VERSION "ConnectivityCANFD"

NS_ :

BS_ :

BU_ :  ETC IHU TCAM

BO_ 176 TcamConnCANFDFr01 : 64 TCAM
 SG_ ApproachReq_UB : 455|1@0+ (1,0) [0|1] "" IHU
 SG_ ApproachReqData1 : 7|8@0+ (1.0,0.0) [0.0|255.0] "Unitless" IHU
 SG_ ApproachReqData10 : 79|8@0+ (1.0,0.0) [0.0|255.0] "Unitless" IHU
 SG_ ApproachReqData11 : 87|8@0+ (1.0,0.0) [0.0|255.0] "Unitless" IHU
 SG_ ApproachReqData12 : 95|8@0+ (1.0,0.0) [0.0|255.0] "Unitless" IHU
 SG_ ApproachReqData13 : 103|8@0+ (1.0,0.0) [0.0|255.0] "Unitless" IHU
 SG_ ApproachReqData14 : 111|8@0+ (1.0,0.0) [0.0|255.0] "Unitless" IHU
 SG_ ApproachReqData15 : 119|8@0+ (1.0,0.0) [0.0|255.0] "Unitless" IHU
 SG_ ApproachReqData16 : 127|8@0+ (1.0,0.0) [0.0|255.0] "Unitless" IHU
 SG_ ApproachReqData2 : 15|8@0+ (1.0,0.0) [0.0|255.0] "Unitless" IHU
 SG_ ApproachReqData3 : 23|8@0+ (1.0,0.0) [0.0|255.0] "Unitless" IHU
 SG_ ApproachReqData4 : 31|8@0+ (1.0,0.0) [0.0|255.0] "Unitless" IHU
 SG_ ApproachReqData5 : 39|8@0+ (1.0,0.0) [0.0|255.0] "Unitless" IHU
 SG_ ApproachReqData6 : 47|8@0+ (1.0,0.0) [0.0|255.0] "Unitless" IHU
 SG_ ApproachReqData7 : 55|8@0+ (1.0,0.0) [0.0|255.0] "Unitless" IHU
 SG_ ApproachReqData8 : 63|8@0+ (1.0,0.0) [0.0|255.0] "Unitless" IHU
 SG_ ApproachReqData9 : 71|8@0+ (1.0,0.0) [0.0|255.0] "Unitless" IHU
 SG_ BLEKeySearchResp_UB : 454|1@0+ (1,0) [0|1] "" IHU
 SG_ BLEKeySearchRespData1 : 135|8@0+ (1.0,0.0) [0.0|255.0] "Unitless" IHU
 SG_ BLEKeySearchRespData10 : 207|8@0+ (1.0,0.0) [0.0|255.0] "Unitless" IHU
 SG_ BLEKeySearchRespData11 : 215|8@0+ (1.0,0.0) [0.0|255.0] "Unitless" IHU
 SG_ BLEKeySearchRespData12 : 223|8@0+ (1.0,0.0) [0.0|255.0] "Unitless" IHU
 SG_ BLEKeySearchRespData13 : 231|8@0+ (1.0,0.0) [0.0|255.0] "Unitless" IHU
 SG_ BLEKeySearchRespData14 : 239|8@0+ (1.0,0.0) [0.0|255.0] "Unitless" IHU
 SG_ BLEKeySearchRespData15 : 247|8@0+ (1.0,0.0) [0.0|255.0] "Unitless" IHU
 SG_ BLEKeySearchRespData16 : 255|8@0+ (1.0,0.0) [0.0|255.0] "Unitless" IHU
 SG_ BLEKeySearchRespData2 : 143|8@0+ (1.0,0.0) [0.0|255.0] "Unitless" IHU
 SG_ BLEKeySearchRespData3 : 151|8@0+ (1.0,0.0) [0.0|255.0] "Unitless" IHU
 SG_ BLEKeySearchRespData4 : 159|8@0+ (1.0,0.0) [0.0|255.0] "Unitless" IHU
 SG_ BLEKeySearchRespData5 : 167|8@0+ (1.0,0.0) [0.0|255.0] "Unitless" IHU
 SG_ BLEKeySearchRespData6 : 175|8@0+ (1.0,0.0) [0.0|255.0] "Unitless" IHU
 SG_ BLEKeySearchRespData7 : 183|8@0+ (1.0,0.0) [0.0|255.0] "Unitless" IHU
 SG_ BLEKeySearchRespData8 : 191|8@0+ (1.0,0.0) [0.0|255.0] "Unitless" IHU
 SG_ BLEKeySearchRespData9 : 199|8@0+ (1.0,0.0) [0.0|255.0] "Unitless" IHU
 SG_ DigKeyDataToHMI_UB : 453|1@0+ (1,0) [0|1] "" IHU
 SG_ DigKeyDataToHMIAcknowledgment : 263|8@0+ (1.0,0.0) [0.0|255.0] "Unitless" IHU
 SG_ DigKeyDataToHMIDKDataByte1 : 271|8@0+ (1.0,0.0) [0.0|255.0] "Unitless" IHU
 SG_ DigKeyDataToHMIDKDataByte2 : 279|8@0+ (1.0,0.0) [0.0|255.0] "Unitless" IHU
 SG_ DigKeyDataToHMIDKDataByte3 : 287|8@0+ (1.0,0.0) [0.0|255.0] "Unitless" IHU
 SG_ DigKeyDataToHMIDKDataByte4 : 295|8@0+ (1.0,0.0) [0.0|255.0] "Unitless" IHU
 SG_ DigKeyDataToHMIDKDataByte5 : 303|8@0+ (1.0,0.0) [0.0|255.0] "Unitless" IHU
 SG_ DigKeyDataToHMIDKDataByte6 : 311|8@0+ (1.0,0.0) [0.0|255.0] "Unitless" IHU
 SG_ DigKeyDataToHMIHeader : 319|8@0+ (1.0,0.0) [0.0|255.0] "Unitless" IHU
 SG_ NFCAndBLEKeyEnaSts_UB : 452|1@0+ (1,0) [0|1] "" IHU
 SG_ NFCAndBLEKeyEnaStsData1 : 327|8@0+ (1.0,0.0) [0.0|255.0] "Unitless" IHU
 SG_ NFCAndBLEKeyEnaStsData10 : 399|8@0+ (1.0,0.0) [0.0|255.0] "Unitless" IHU
 SG_ NFCAndBLEKeyEnaStsData11 : 407|8@0+ (1.0,0.0) [0.0|255.0] "Unitless" IHU
 SG_ NFCAndBLEKeyEnaStsData12 : 415|8@0+ (1.0,0.0) [0.0|255.0] "Unitless" IHU
 SG_ NFCAndBLEKeyEnaStsData13 : 423|8@0+ (1.0,0.0) [0.0|255.0] "Unitless" IHU
 SG_ NFCAndBLEKeyEnaStsData14 : 431|8@0+ (1.0,0.0) [0.0|255.0] "Unitless" IHU
 SG_ NFCAndBLEKeyEnaStsData15 : 439|8@0+ (1.0,0.0) [0.0|255.0] "Unitless" IHU
 SG_ NFCAndBLEKeyEnaStsData16 : 447|8@0+ (1.0,0.0) [0.0|255.0] "Unitless" IHU
 SG_ NFCAndBLEKeyEnaStsData2 : 335|8@0+ (1.0,0.0) [0.0|255.0] "Unitless" IHU
 SG_ NFCAndBLEKeyEnaStsData3 : 343|8@0+ (1.0,0.0) [0.0|255.0] "Unitless" IHU
 SG_ NFCAndBLEKeyEnaStsData4 : 351|8@0+ (1.0,0.0) [0.0|255.0] "Unitless" IHU
 SG_ NFCAndBLEKeyEnaStsData5 : 359|8@0+ (1.0,0.0) [0.0|255.0] "Unitless" IHU
 SG_ NFCAndBLEKeyEnaStsData6 : 367|8@0+ (1.0,0.0) [0.0|255.0] "Unitless" IHU
 SG_ NFCAndBLEKeyEnaStsData7 : 375|8@0+ (1.0,0.0) [0.0|255.0] "Unitless" IHU
 SG_ NFCAndBLEKeyEnaStsData8 : 383|8@0+ (1.0,0.0) [0.0|255.0] "Unitless" IHU
 SG_ NFCAndBLEKeyEnaStsData9 : 391|8@0+ (1.0,0.0) [0.0|255.0] "Unitless" IHU

BO_ 336 TcamConnCANFDFr02 : 64 TCAM
 SG_ BattPreHeatgLvl : 21|2@0+ (1,0) [0|3] "" IHU
 SG_ BattPreHeatgLvl_UB : 22|1@0+ (1,0) [0|1] "" IHU
 SG_ BattPreHeatgTiDif : 7|16@0+ (1.0,0.0) [0.0|65535.0] "Mins" IHU
 SG_ BattPreHeatgTiDif_UB : 23|1@0+ (1,0) [0|1] "" IHU
 SG_ BookChrgnActvdReq : 19|1@0+ (1,0) [0|1] "" IHU
 SG_ BookChrgnActvdReq_UB : 18|1@0+ (1,0) [0|1] "" IHU
 SG_ BookStopTiAchieved : 17|1@0+ (1,0) [0|1] "" IHU
 SG_ BookStopTiAchieved_UB : 16|1@0+ (1,0) [0|1] "" IHU
 SG_ BookTrvlClimaActvReq : 31|2@0+ (1,0) [0|3] "" IHU
 SG_ BookTrvlClimaActvReq_UB : 27|1@0+ (1,0) [0|1] "" IHU
 SG_ CarFindrHornLiReqFromTelm : 29|2@0+ (1,0) [0|3] "" IHU
 SG_ CarFindrHornLiReqFromTelm_UB : 26|1@0+ (1,0) [0|1] "" IHU
 SG_ CbnOverHeatProtnEnaFromTelm : 25|1@0+ (1,0) [0|1] "" IHU
 SG_ CbnOverHeatProtnEnaFromTelm_UB : 24|1@0+ (1,0) [0|1] "" IHU
 SG_ ChrgLidTelmLockgReq : 33|1@0+ (1,0) [0|1] "" IHU
 SG_ ChrgLidTelmLockgReq_UB : 32|1@0+ (1,0) [0|1] "" IHU
 SG_ ChrgnCtrlToEndOrRetartFromApp : 39|2@0+ (1,0) [0|3] "" IHU
 SG_ ChrgnCtrlToEndOrRetartFromApp_UB : 35|1@0+ (1,0) [0|1] "" IHU
 SG_ ClimaRqrd1 : 37|2@0+ (1,0) [0|3] "" IHU
 SG_ ClimaRqrd1_UB : 34|1@0+ (1,0) [0|1] "" IHU
 SG_ ClimaTmrStsTelmRqrd : 47|1@0+ (1,0) [0|1] "" IHU
 SG_ ClimaTmrStsTelmRqrd_UB : 46|1@0+ (1,0) [0|1] "" IHU
 SG_ CnclBookTrvlReq : 45|1@0+ (1,0) [0|1] "" IHU
 SG_ CnclBookTrvlReq_UB : 44|1@0+ (1,0) [0|1] "" IHU
 SG_ DigKeyGidInfo1_UB : 40|1@0+ (1,0) [0|1] "" IHU
 SG_ DigKeyGidInfo1Byte0 : 55|8@0+ (1.0,0.0) [0.0|255.0] "Unitless" IHU
 SG_ DigKeyGidInfo1Byte1 : 63|8@0+ (1.0,0.0) [0.0|255.0] "Unitless" IHU
 SG_ DigKeyGidInfo1Byte2 : 71|8@0+ (1.0,0.0) [0.0|255.0] "Unitless" IHU
 SG_ DigKeyGidInfo1Byte3 : 79|8@0+ (1.0,0.0) [0.0|255.0] "Unitless" IHU
 SG_ DigKeyGidInfo1Byte4 : 87|8@0+ (1.0,0.0) [0.0|255.0] "Unitless" IHU
 SG_ DigKeyGidInfo1Byte5 : 95|8@0+ (1.0,0.0) [0.0|255.0] "Unitless" IHU
 SG_ DigKeyGidInfo1Byte6 : 103|8@0+ (1.0,0.0) [0.0|255.0] "Unitless" IHU
 SG_ DigKeyGidInfo1Byte7 : 111|8@0+ (1.0,0.0) [0.0|255.0] "Unitless" IHU
 SG_ DigKeyGidInfo2_UB : 183|1@0+ (1,0) [0|1] "" IHU
 SG_ DigKeyGidInfo2Byte0 : 119|8@0+ (1.0,0.0) [0.0|255.0] "Unitless" IHU
 SG_ DigKeyGidInfo2Byte1 : 127|8@0+ (1.0,0.0) [0.0|255.0] "Unitless" IHU
 SG_ DigKeyGidInfo2Byte2 : 135|8@0+ (1.0,0.0) [0.0|255.0] "Unitless" IHU
 SG_ DigKeyGidInfo2Byte3 : 143|8@0+ (1.0,0.0) [0.0|255.0] "Unitless" IHU
 SG_ DigKeyGidInfo2Byte4 : 151|8@0+ (1.0,0.0) [0.0|255.0] "Unitless" IHU
 SG_ DigKeyGidInfo2Byte5 : 159|8@0+ (1.0,0.0) [0.0|255.0] "Unitless" IHU
 SG_ DigKeyGidInfo2Byte6 : 167|8@0+ (1.0,0.0) [0.0|255.0] "Unitless" IHU
 SG_ DigKeyGidInfo2Byte7 : 175|8@0+ (1.0,0.0) [0.0|255.0] "Unitless" IHU
 SG_ DKDataFromTelm_UB : 182|1@0+ (1,0) [0|1] "" IHU
 SG_ DKDataFromTelmAcknowledgment : 191|8@0+ (1.0,0.0) [0.0|255.0] "Unitless" IHU
 SG_ DKDataFromTelmDKDataByte1 : 199|8@0+ (1.0,0.0) [0.0|255.0] "Unitless" IHU
 SG_ DKDataFromTelmDKDataByte2 : 207|8@0+ (1.0,0.0) [0.0|255.0] "Unitless" IHU
 SG_ DKDataFromTelmDKDataByte3 : 215|8@0+ (1.0,0.0) [0.0|255.0] "Unitless" IHU
 SG_ DKDataFromTelmDKDataByte4 : 223|8@0+ (1.0,0.0) [0.0|255.0] "Unitless" IHU
 SG_ DKDataFromTelmDKDataByte5 : 231|8@0+ (1.0,0.0) [0.0|255.0] "Unitless" IHU
 SG_ DKDataFromTelmDKDataByte6 : 239|8@0+ (1.0,0.0) [0.0|255.0] "Unitless" IHU
 SG_ DKDataFromTelmHeader : 247|8@0+ (1.0,0.0) [0.0|255.0] "Unitless" IHU
 SG_ EmgyAsscTrigSts : 43|2@0+ (1,0) [0|3] "" IHU
 SG_ EmgyAsscTrigSts_UB : 41|1@0+ (1,0) [0|1] "" IHU
 SG_ EngForbidReqFromTelm : 259|1@0+ (1,0) [0|1] "" IHU
 SG_ EngForbidReqFromTelm_UB : 258|1@0+ (1,0) [0|1] "" IHU
 SG_ EngPermitReqFromTelm : 257|1@0+ (1,0) [0|1] "" IHU
 SG_ EngPermitReqFromTelm_UB : 256|1@0+ (1,0) [0|1] "" IHU
 SG_ ErsCmdRec_UB : 263|1@0+ (1,0) [0|1] "" IHU
 SG_ ErsCmdRecErsCmd : 255|2@0+ (1,0) [0|3] "" IHU
 SG_ ErsCmdRecErsRunTime : 253|6@0+ (1.0,0.0) [0.0|59.0] "Mins" IHU
 SG_ MemPosnFromTelm : 179|2@0+ (1,0) [0|3] "" IHU
 SG_ MemPosnFromTelm_UB : 180|1@0+ (1,0) [0|1] "" IHU
 SG_ RemACChrgLidTelmReq : 177|2@0+ (1,0) [0|3] "" IHU
 SG_ RemACChrgLidTelmReq_UB : 181|1@0+ (1,0) [0|1] "" IHU
 SG_ RemBookChrgnTarVal : 271|10@0+ (0.1,0.0) [0.0|100.0] "%" IHU
 SG_ RemBookChrgnTarVal_UB : 277|1@0+ (1,0) [0|1] "" IHU
 SG_ RemChkTInVeh : 273|1@0+ (1,0) [0|1] "" IHU
 SG_ RemChkTInVeh_UB : 272|1@0+ (1,0) [0|1] "" IHU
 SG_ RemDCChrgLidTelmReq : 261|2@0+ (1,0) [0|3] "" IHU
 SG_ RemDCChrgLidTelmReq_UB : 262|1@0+ (1,0) [0|1] "" IHU
 SG_ RemsSetDchaTarVal : 287|10@0+ (0.1,0.0) [0.0|100.0] "%" IHU
 SG_ RemsSetDchaTarVal_UB : 293|1@0+ (1,0) [0|1] "" IHU
 SG_ RemVentReq : 275|2@0+ (1,0) [0|3] "" IHU
 SG_ RemVentReq_UB : 276|1@0+ (1,0) [0|1] "" IHU
 SG_ ReqFragLvlTelm : 291|2@0+ (1,0) [0|3] "" IHU
 SG_ ReqFragLvlTelm_UB : 292|1@0+ (1,0) [0|1] "" IHU
 SG_ SeatHeatDurgClimaEnadFromTelm : 303|3@0+ (1,0) [0|7] "" IHU
 SG_ SeatHeatDurgClimaEnadFromTelm_UB : 300|1@0+ (1,0) [0|1] "" IHU
 SG_ SteerWhlHeatgDurgClimaEnadFromTelm : 289|1@0+ (1,0) [0|1] "" IHU
 SG_ SteerWhlHeatgDurgClimaEnadFromTelm_UB : 288|1@0+ (1,0) [0|1] "" IHU
 SG_ SunRoofAndCurtCmdTelm : 311|8@0+ (1,0) [0|255] "" IHU
 SG_ SunRoofAndCurtCmdTelm_UB : 296|1@0+ (1,0) [0|1] "" IHU
 SG_ TankFlapTelmLockgReq : 319|3@0+ (1,0) [0|7] "" IHU
 SG_ TankFlapTelmLockgReq_UB : 316|1@0+ (1,0) [0|1] "" IHU
 SG_ TelmAirFragTasteReq : 315|3@0+ (1,0) [0|7] "" IHU
 SG_ TelmAirFragTasteReq_UB : 312|1@0+ (1,0) [0|1] "" IHU
 SG_ TelmBookChrgnReq : 298|2@0+ (1,0) [0|3] "" IHU
 SG_ TelmBookChrgnReq_UB : 299|1@0+ (1,0) [0|1] "" IHU
 SG_ TelmBookClimaReq_UB : 328|1@0+ (1,0) [0|1] "" IHU
 SG_ TelmBookClimaReqHmiCmptmtTSpSpcl : 321|2@0+ (1,0) [0|3] "" IHU
 SG_ TelmBookClimaReqOnOffNoReq : 335|2@0+ (1,0) [0|3] "" IHU
 SG_ TelmBookClimaReqTempRange : 333|5@0+ (0.5,15.5) [15.5|28.5] "degC" IHU
 SG_ TelmBookClimaTmr : 343|16@0+ (1.0,0.0) [0.0|65535.0] "s" IHU
 SG_ TelmBookClimaTmr_UB : 322|1@0+ (1,0) [0|1] "" IHU
 SG_ TelmBookSeatHeatClimalReq_UB : 372|1@0+ (1,0) [0|1] "" IHU
 SG_ TelmBookSeatHeatClimalReqDrvHeatClimaLvl : 371|2@0+ (1,0) [0|3] "" IHU
 SG_ TelmBookSeatHeatClimalReqPassHeatClimaLvl : 369|2@0+ (1,0) [0|3] "" IHU
 SG_ TelmBookSeatHeatClimalReqSecLeHeatClimaLvl : 383|2@0+ (1,0) [0|3] "" IHU
 SG_ TelmBookSeatHeatClimalReqSecRiHeatClimaLvl : 381|2@0+ (1,0) [0|3] "" IHU
 SG_ TelmBookSeatHeatClimalReqThrdLeHeatClimaLvl : 379|2@0+ (1,0) [0|3] "" IHU
 SG_ TelmBookSeatHeatClimalReqThrdRiHeatClimaLvl : 377|2@0+ (1,0) [0|3] "" IHU
 SG_ TelmBookSeatVentnClimalReq_UB : 395|1@0+ (1,0) [0|1] "" IHU
 SG_ TelmBookSeatVentnClimalReqDrvVentnClimaLvl : 391|2@0+ (1,0) [0|3] "" IHU
 SG_ TelmBookSeatVentnClimalReqPassVentnClimaLvl : 389|2@0+ (1,0) [0|3] "" IHU
 SG_ TelmBookSeatVentnClimalReqSecLeVentnClimaLvl : 387|2@0+ (1,0) [0|3] "" IHU
 SG_ TelmBookSeatVentnClimalReqSecRiVentnClimaLvl : 385|2@0+ (1,0) [0|3] "" IHU
 SG_ TelmBookSeatVentnClimalReqThrdLeVentnClimaLvl : 399|2@0+ (1,0) [0|3] "" IHU
 SG_ TelmBookSeatVentnClimalReqThrdRiVentnClimaL : 397|2@0+ (1,0) [0|3] "" IHU
 SG_ TelmBookSteerWhlHeatClimalReq : 327|1@0+ (1,0) [0|1] "" IHU
 SG_ TelmBookSteerWhlHeatClimalReq_UB : 326|1@0+ (1,0) [0|1] "" IHU
 SG_ TelmClimaReq : 375|2@0+ (1,0) [0|3] "" IHU
 SG_ TelmClimaReq_UB : 373|1@0+ (1,0) [0|1] "" IHU
 SG_ TelmClimaTmr : 359|16@0+ (1.0,0.0) [0.0|65535.0] "s" IHU
 SG_ TelmClimaTmr_UB : 323|1@0+ (1,0) [0|1] "" IHU
 SG_ TelmClimaTSet_UB : 407|1@0+ (1,0) [0|1] "" IHU
 SG_ TelmClimaTSetHmiCmptmtTSpSpcl : 406|2@0+ (1,0) [0|3] "" IHU
 SG_ TelmClimaTSetTempRange : 404|5@0+ (0.5,15.5) [15.5|28.5] "degC" IHU
 SG_ TelmDefrostReq : 393|2@0+ (1,0) [0|3] "" IHU
 SG_ TelmDefrostReq_UB : 394|1@0+ (1,0) [0|1] "" IHU
 SG_ TelmEngDelayTi : 415|6@0+ (1.0,0.0) [0.0|59.0] "Mins" IHU
 SG_ TelmEngDelayTi_UB : 409|1@0+ (1,0) [0|1] "" IHU
 SG_ TelmFctReq : 325|1@0+ (1,0) [0|1] "" IHU
 SG_ TelmFctReq_UB : 324|1@0+ (1,0) [0|1] "" IHU
 SG_ TelmLockgCenReq_UB : 422|1@0+ (1,0) [0|1] "" IHU
 SG_ TelmLockgCenReqReqTyp : 421|2@0+ (1,0) [0|3] "" IHU
 SG_ TelmLockgCenReqTiVld : 419|4@0+ (1.0,0.0) [0.0|15.0] "Unitless" IHU
 SG_ TelmPM25Req : 408|1@0+ (1,0) [0|1] "" IHU
 SG_ TelmPM25Req_UB : 423|1@0+ (1,0) [0|1] "" IHU
 SG_ TelmPreClimaPrio : 431|2@0+ (1,0) [0|3] "" IHU
 SG_ TelmPreClimaPrio_UB : 447|1@0+ (1,0) [0|1] "" IHU
 SG_ TelmSeatDrvHeatClimaLvl : 429|2@0+ (1,0) [0|3] "" IHU
 SG_ TelmSeatDrvHeatClimaLvl_UB : 446|1@0+ (1,0) [0|1] "" IHU
 SG_ TelmSeatDrvVentnClimaLvl : 427|2@0+ (1,0) [0|3] "" IHU
 SG_ TelmSeatDrvVentnClimaLvl_UB : 445|1@0+ (1,0) [0|1] "" IHU
 SG_ TelmSeatPassHeatClimaLvl : 425|2@0+ (1,0) [0|3] "" IHU
 SG_ TelmSeatPassHeatClimaLvl_UB : 444|1@0+ (1,0) [0|1] "" IHU
 SG_ TelmSeatPassVentnClimaLvl : 439|2@0+ (1,0) [0|3] "" IHU
 SG_ TelmSeatPassVentnClimaLvl_UB : 443|1@0+ (1,0) [0|1] "" IHU
 SG_ TelmSeatSecLeHeatClimaLvl : 437|2@0+ (1,0) [0|3] "" IHU
 SG_ TelmSeatSecLeHeatClimaLvl_UB : 442|1@0+ (1,0) [0|1] "" IHU
 SG_ TelmSeatSecLeVentnClimaLvl : 435|2@0+ (1,0) [0|3] "" IHU
 SG_ TelmSeatSecLeVentnClimaLvl_UB : 441|1@0+ (1,0) [0|1] "" IHU
 SG_ TelmSeatSecRiHeatClimaLvl : 433|2@0+ (1,0) [0|3] "" IHU
 SG_ TelmSeatSecRiHeatClimaLvl_UB : 440|1@0+ (1,0) [0|1] "" IHU
 SG_ TelmSeatSecRiVentnClimaLvl : 455|2@0+ (1,0) [0|3] "" IHU
 SG_ TelmSeatSecRiVentnClimaLvl_UB : 479|1@0+ (1,0) [0|1] "" IHU
 SG_ TelmSeatThrdLeHeatClimaLvl : 453|2@0+ (1,0) [0|3] "" IHU
 SG_ TelmSeatThrdLeHeatClimaLvl_UB : 478|1@0+ (1,0) [0|1] "" IHU
 SG_ TelmSeatThrdLeVentnClimaLvl : 451|2@0+ (1,0) [0|3] "" IHU
 SG_ TelmSeatThrdLeVentnClimaLvl_UB : 477|1@0+ (1,0) [0|1] "" IHU
 SG_ TelmSeatThrdRiHeatClimaLvl : 449|2@0+ (1,0) [0|3] "" IHU
 SG_ TelmSeatThrdRiHeatClimaLvl_UB : 476|1@0+ (1,0) [0|1] "" IHU
 SG_ TelmSeatThrdRiVentnClimaLvl : 463|2@0+ (1,0) [0|3] "" IHU
 SG_ TelmSeatThrdRiVentnClimaLvl_UB : 475|1@0+ (1,0) [0|1] "" IHU
 SG_ TelmStrtEngForChrgnReq : 461|2@0+ (1,0) [0|3] "" IHU
 SG_ TelmStrtEngForChrgnReq_UB : 474|1@0+ (1,0) [0|1] "" IHU
 SG_ TelmThermoTankReq1 : 503|2@0+ (1,0) [0|3] "" IHU
 SG_ TelmThermoTankReq1_UB : 488|1@0+ (1,0) [0|1] "" IHU
 SG_ TelmThermoTankT : 487|8@0+ (1.0,-50.0) [-50.0|205.0] "degC" IHU
 SG_ TelmThermoTankT_UB : 495|1@0+ (1,0) [0|1] "" IHU
 SG_ TelmThermoTankTmr1 : 494|5@0+ (1.0,0.0) [0.0|31.0] "hours" IHU
 SG_ TelmThermoTankTmr1_UB : 489|1@0+ (1,0) [0|1] "" IHU
 SG_ UnlockAndLogInAccountReq : 459|2@0+ (1,0) [0|3] "" IHU
 SG_ UnlockAndLogInAccountReq_UB : 473|1@0+ (1,0) [0|1] "" IHU
 SG_ WinOpenClsGlbReqFromTelm_UB : 472|1@0+ (1,0) [0|1] "" IHU
 SG_ WinOpenClsGlbReqFromTelmWindowOpenValue : 471|8@0+ (1.0,0.0) [0.0|100.0] "%" IHU
 SG_ WinOpenClsGlbReqFromTelmWinOpenClsGlbSts : 457|2@0+ (1,0) [0|3] "" IHU

BO_ 192 TcamConnCANFDFr03 : 64 TCAM
 SG_ DKDataFromBLE_UB : 261|1@0+ (1,0) [0|1] "" IHU
 SG_ DKDataFromBLEAcknowledgment : 271|8@0+ (1.0,0.0) [0.0|255.0] "Unitless" IHU
 SG_ DKDataFromBLEDKDataByte1 : 279|8@0+ (1.0,0.0) [0.0|255.0] "Unitless" IHU
 SG_ DKDataFromBLEDKDataByte2 : 287|8@0+ (1.0,0.0) [0.0|255.0] "Unitless" IHU
 SG_ DKDataFromBLEDKDataByte3 : 295|8@0+ (1.0,0.0) [0.0|255.0] "Unitless" IHU
 SG_ DKDataFromBLEDKDataByte4 : 303|8@0+ (1.0,0.0) [0.0|255.0] "Unitless" IHU
 SG_ DKDataFromBLEDKDataByte5 : 311|8@0+ (1.0,0.0) [0.0|255.0] "Unitless" IHU
 SG_ DKDataFromBLEDKDataByte6 : 319|8@0+ (1.0,0.0) [0.0|255.0] "Unitless" IHU
 SG_ DKDataFromBLEHeader : 327|8@0+ (1.0,0.0) [0.0|255.0] "Unitless" IHU
 SG_ DKDataFromTelm1_UB : 260|1@0+ (1,0) [0|1] "" IHU
 SG_ DKDataFromTelm1Acknowledgment : 335|8@0+ (1.0,0.0) [0.0|255.0] "Unitless" IHU
 SG_ DKDataFromTelm1DKDataByte1 : 343|8@0+ (1.0,0.0) [0.0|255.0] "Unitless" IHU
 SG_ DKDataFromTelm1DKDataByte2 : 351|8@0+ (1.0,0.0) [0.0|255.0] "Unitless" IHU
 SG_ DKDataFromTelm1DKDataByte3 : 359|8@0+ (1.0,0.0) [0.0|255.0] "Unitless" IHU
 SG_ DKDataFromTelm1DKDataByte4 : 367|8@0+ (1.0,0.0) [0.0|255.0] "Unitless" IHU
 SG_ DKDataFromTelm1DKDataByte5 : 375|8@0+ (1.0,0.0) [0.0|255.0] "Unitless" IHU
 SG_ DKDataFromTelm1DKDataByte6 : 383|8@0+ (1.0,0.0) [0.0|255.0] "Unitless" IHU
 SG_ DKDataFromTelm1Header : 391|8@0+ (1.0,0.0) [0.0|255.0] "Unitless" IHU
 SG_ NFCKeySearchResp_UB : 263|1@0+ (1,0) [0|1] "" IHU
 SG_ NFCKeySearchRespData1 : 7|8@0+ (1.0,0.0) [0.0|255.0] "Unitless" IHU
 SG_ NFCKeySearchRespData10 : 79|8@0+ (1.0,0.0) [0.0|255.0] "Unitless" IHU
 SG_ NFCKeySearchRespData11 : 87|8@0+ (1.0,0.0) [0.0|255.0] "Unitless" IHU
 SG_ NFCKeySearchRespData12 : 95|8@0+ (1.0,0.0) [0.0|255.0] "Unitless" IHU
 SG_ NFCKeySearchRespData13 : 103|8@0+ (1.0,0.0) [0.0|255.0] "Unitless" IHU
 SG_ NFCKeySearchRespData14 : 111|8@0+ (1.0,0.0) [0.0|255.0] "Unitless" IHU
 SG_ NFCKeySearchRespData15 : 119|8@0+ (1.0,0.0) [0.0|255.0] "Unitless" IHU
 SG_ NFCKeySearchRespData16 : 127|8@0+ (1.0,0.0) [0.0|255.0] "Unitless" IHU
 SG_ NFCKeySearchRespData2 : 15|8@0+ (1.0,0.0) [0.0|255.0] "Unitless" IHU
 SG_ NFCKeySearchRespData3 : 23|8@0+ (1.0,0.0) [0.0|255.0] "Unitless" IHU
 SG_ NFCKeySearchRespData4 : 31|8@0+ (1.0,0.0) [0.0|255.0] "Unitless" IHU
 SG_ NFCKeySearchRespData5 : 39|8@0+ (1.0,0.0) [0.0|255.0] "Unitless" IHU
 SG_ NFCKeySearchRespData6 : 47|8@0+ (1.0,0.0) [0.0|255.0] "Unitless" IHU
 SG_ NFCKeySearchRespData7 : 55|8@0+ (1.0,0.0) [0.0|255.0] "Unitless" IHU
 SG_ NFCKeySearchRespData8 : 63|8@0+ (1.0,0.0) [0.0|255.0] "Unitless" IHU
 SG_ NFCKeySearchRespData9 : 71|8@0+ (1.0,0.0) [0.0|255.0] "Unitless" IHU
 SG_ RKEAndNFCReqSts_UB : 262|1@0+ (1,0) [0|1] "" IHU
 SG_ RKEAndNFCReqStsData1 : 135|8@0+ (1.0,0.0) [0.0|255.0] "Unitless" IHU
 SG_ RKEAndNFCReqStsData10 : 207|8@0+ (1.0,0.0) [0.0|255.0] "Unitless" IHU
 SG_ RKEAndNFCReqStsData11 : 215|8@0+ (1.0,0.0) [0.0|255.0] "Unitless" IHU
 SG_ RKEAndNFCReqStsData12 : 223|8@0+ (1.0,0.0) [0.0|255.0] "Unitless" IHU
 SG_ RKEAndNFCReqStsData13 : 231|8@0+ (1.0,0.0) [0.0|255.0] "Unitless" IHU
 SG_ RKEAndNFCReqStsData14 : 239|8@0+ (1.0,0.0) [0.0|255.0] "Unitless" IHU
 SG_ RKEAndNFCReqStsData15 : 247|8@0+ (1.0,0.0) [0.0|255.0] "Unitless" IHU
 SG_ RKEAndNFCReqStsData16 : 255|8@0+ (1.0,0.0) [0.0|255.0] "Unitless" IHU
 SG_ RKEAndNFCReqStsData2 : 143|8@0+ (1.0,0.0) [0.0|255.0] "Unitless" IHU
 SG_ RKEAndNFCReqStsData3 : 151|8@0+ (1.0,0.0) [0.0|255.0] "Unitless" IHU
 SG_ RKEAndNFCReqStsData4 : 159|8@0+ (1.0,0.0) [0.0|255.0] "Unitless" IHU
 SG_ RKEAndNFCReqStsData5 : 167|8@0+ (1.0,0.0) [0.0|255.0] "Unitless" IHU
 SG_ RKEAndNFCReqStsData6 : 175|8@0+ (1.0,0.0) [0.0|255.0] "Unitless" IHU
 SG_ RKEAndNFCReqStsData7 : 183|8@0+ (1.0,0.0) [0.0|255.0] "Unitless" IHU
 SG_ RKEAndNFCReqStsData8 : 191|8@0+ (1.0,0.0) [0.0|255.0] "Unitless" IHU
 SG_ RKEAndNFCReqStsData9 : 199|8@0+ (1.0,0.0) [0.0|255.0] "Unitless" IHU

BO_ 320 TcamConnCANFDFr04 : 64 TCAM
 SG_ GuestrSts1_UB : 5|1@0+ (1,0) [0|1] "" IHU
 SG_ GuestrSts1Chks : 15|8@0+ (1.0,0.0) [0.0|255.0] "Unitless" IHU
 SG_ GuestrSts1Cntr : 3|4@0+ (1.0,0.0) [0.0|15.0] "Unitless" IHU
 SG_ GuestrSts1Validity : 4|1@0+ (1,0) [0|1] "" IHU
 SG_ KickTailgateSig : 90|1@0+ (1,0) [0|1] "" IHU
 SG_ KickTailgateSig_UB : 89|1@0+ (1,0) [0|1] "" IHU
 SG_ MobDevRPAAuthResp1_UB : 50|1@0+ (1,0) [0|1] "" IHU
 SG_ MobDevRPAAuthResp1Answer : 47|9@0+ (1.0,0.0) [0.0|511.0] "Unitless" IHU
 SG_ MobDevRPAAuthResp1Chks : 23|8@0+ (1.0,0.0) [0.0|255.0] "Unitless" IHU
 SG_ MobDevRPAAuthResp1Cntr : 54|4@0+ (1.0,0.0) [0.0|15.0] "Unitless" IHU
 SG_ MobDevRPAAuthResp1X : 31|8@0+ (1.0,0.0) [0.0|255.0] "Unitless" IHU
 SG_ MobDevRPAAuthResp1Y : 39|8@0+ (1.0,0.0) [0.0|255.0] "Unitless" IHU
 SG_ MobDevRPAReq1_UB : 63|1@0+ (1,0) [0|1] "" IHU
 SG_ MobDevRPAReq1Chks : 71|8@0+ (1.0,0.0) [0.0|255.0] "Unitless" IHU
 SG_ MobDevRPAReq1Cntr : 59|4@0+ (1.0,0.0) [0.0|15.0] "Unitless" IHU
 SG_ MobDevRPAReq1MobDevSts : 79|8@0+ (1.0,0.0) [0.0|255.0] "Unitless" IHU
 SG_ MobDevRPAReq1RPAOutModeSubT : 87|4@0+ (1,0) [0|15] "" IHU
 SG_ MobDevRPAReq1RPAReq : 83|4@0+ (1,0) [0|15] "" IHU
 SG_ MobDevRPAReq1RSPACtrl : 62|3@0+ (1,0) [0|7] "" IHU
 SG_ PasEntryEnaReq1 : 7|1@0+ (1,0) [0|1] "" IHU
 SG_ PasEntryEnaReq1_UB : 6|1@0+ (1,0) [0|1] "" IHU
 SG_ RemHvStrtActvReq : 95|2@0+ (1,0) [0|3] "" IHU
 SG_ RemHvStrtActvReq_UB : 93|1@0+ (1,0) [0|1] "" IHU

BO_ 928 TcamConnCANFDFr05 : 64 TCAM
 SG_ CarSharingMde : 3|1@0+ (1,0) [0|1] "" IHU
 SG_ CarSharingMde_UB : 2|1@0+ (1,0) [0|1] "" IHU
 SG_ MobDevBtnPanicReq : 9|2@0+ (1,0) [0|3] "" IHU
 SG_ MobDevBtnPanicReq_UB : 10|1@0+ (1,0) [0|1] "" IHU
 SG_ PhoneForgottenRmnBNCM2 : 1|1@0+ (1,0) [0|1] "" IHU
 SG_ PhoneForgottenRmnBNCM2_UB : 0|1@0+ (1,0) [0|1] "" IHU
 SG_ TelmBookChrgnTyp : 7|3@0+ (1,0) [0|7] "" IHU
 SG_ TelmBookChrgnTyp_UB : 4|1@0+ (1,0) [0|1] "" IHU
 SG_ WPCChrgnStsFrntLeWPC4 : 23|2@0+ (1,0) [0|3] "" IHU
 SG_ WPCChrgnStsFrntLeWPC4_UB : 31|1@0+ (1,0) [0|1] "" IHU
 SG_ WPCChrgnStsFrntRiWPC4 : 21|2@0+ (1,0) [0|3] "" IHU
 SG_ WPCChrgnStsFrntRiWPC4_UB : 30|1@0+ (1,0) [0|1] "" IHU
 SG_ WPCCtrlResFrntLeWPC4 : 19|2@0+ (1,0) [0|3] "" IHU
 SG_ WPCCtrlResFrntLeWPC4_UB : 29|1@0+ (1,0) [0|1] "" IHU
 SG_ WPCCtrlResFrntRiWPC4 : 17|2@0+ (1,0) [0|3] "" IHU
 SG_ WPCCtrlResFrntRiWPC4_UB : 28|1@0+ (1,0) [0|1] "" IHU
 SG_ WPCFailureStsFrntLeWPC4 : 39|4@0+ (1,0) [0|15] "" IHU
 SG_ WPCFailureStsFrntLeWPC4_UB : 27|1@0+ (1,0) [0|1] "" IHU
 SG_ WPCFailureStsFrntRiWPC4 : 35|4@0+ (1,0) [0|15] "" IHU
 SG_ WPCFailureStsFrntRiWPC4_UB : 26|1@0+ (1,0) [0|1] "" IHU
 SG_ WPCModuleStsBNCM2 : 15|4@0+ (1,0) [0|15] "" IHU
 SG_ WPCModuleStsBNCM2_UB : 11|1@0+ (1,0) [0|1] "" IHU
 SG_ WPCModuleStsFrntLeWPC4 : 47|4@0+ (1,0) [0|15] "" IHU
 SG_ WPCModuleStsFrntLeWPC4_UB : 25|1@0+ (1,0) [0|1] "" IHU
 SG_ WPCModuleStsFrntRiWPC4 : 43|4@0+ (1,0) [0|15] "" IHU
 SG_ WPCModuleStsFrntRiWPC4_UB : 24|1@0+ (1,0) [0|1] "" IHU

BO_ 848 TcamConnCANFDFr06 : 64 TCAM
 SG_ BLEKeyBattLoSts : 5|1@0+ (1,0) [0|1] "" IHU
 SG_ BLEKeyBattLoSts_UB : 4|1@0+ (1,0) [0|1] "" IHU
 SG_ PhoneForgottenRmnFrntLeWPC4 : 7|1@0+ (1,0) [0|1] "" IHU
 SG_ PhoneForgottenRmnFrntLeWPC4_UB : 6|1@0+ (1,0) [0|1] "" IHU
 SG_ PhoneForgottenRmnFrntRiWPC4 : 3|1@0+ (1,0) [0|1] "" IHU
 SG_ PhoneForgottenRmnFrntRiWPC4_UB : 2|1@0+ (1,0) [0|1] "" IHU
 SG_ RemVSTDCtrlReq : 11|2@0+ (1,0) [0|3] "" IHU
 SG_ RemVSTDCtrlReq_UB : 9|1@0+ (1,0) [0|1] "" IHU

BO_ 736 TcamConnCANFDFr07 : 64 TCAM
 SG_ BleConSts : 37|1@0+ (1,0) [0|1] "" IHU
 SG_ BleConSts_UB : 36|1@0+ (1,0) [0|1] "" IHU
 SG_ CalltypeAndSts_UB : 1|1@0+ (1,0) [0|1] "" IHU
 SG_ CalltypeAndStsCallType : 7|3@0+ (1,0) [0|7] "" IHU
 SG_ CalltypeAndStsEcallStatus : 4|3@0+ (1,0) [0|7] "" IHU
 SG_ CarLocatorActvSts : 15|2@0+ (1,0) [0|3] "" IHU
 SG_ CarLocatorActvSts_UB : 0|1@0+ (1,0) [0|1] "" IHU
 SG_ NetTCAMActvt : 31|8@0+ (1.0,0.0) [0.0|255.0] "Unitless" IHU
 SG_ NetTCAMActvt_UB : 16|1@0+ (1,0) [0|1] "" IHU
 SG_ TelmPrkgCameraReq : 10|2@0+ (1,0) [0|3] "" IHU
 SG_ TelmPrkgCameraReq_UB : 8|1@0+ (1,0) [0|1] "" IHU
 SG_ UsgModChgReqFromUWB : 39|1@0+ (1,0) [0|1] "" IHU
 SG_ UsgModChgReqFromUWB_UB : 38|1@0+ (1,0) [0|1] "" IHU

BO_ 416 TcamConnCANFDFr08 : 64 TCAM
 SG_ PrkgCmftModTiCtrlReq : 7|2@0+ (1,0) [0|3] "" IHU
 SG_ PrkgCmftModTiCtrlReq_UB : 5|1@0+ (1,0) [0|1] "" IHU
 SG_ RemRemoveStrangerPassWordReq : 71|1@0+ (1,0) [0|1] "" IHU
 SG_ RemRemoveStrangerPassWordReq_UB : 70|1@0+ (1,0) [0|1] "" IHU
 SG_ RemStrtExtnTiReq : 15|6@0+ (1.0,0.0) [0.0|59.0] "Mins" IHU
 SG_ RemStrtExtnTiReq_UB : 9|1@0+ (1,0) [0|1] "" IHU
 SG_ RemStrtHvCtrlReq_UB : 8|1@0+ (1,0) [0|1] "" IHU
 SG_ RemStrtHvCtrlReqErsCmd : 23|2@0+ (1,0) [0|3] "" IHU
 SG_ RemStrtHvCtrlReqErsRunTime : 21|6@0+ (1.0,0.0) [0.0|59.0] "Mins" IHU
 SG_ TcamResetResp : 3|2@0+ (1,0) [0|3] "" IHU
 SG_ TcamResetResp_UB : 4|1@0+ (1,0) [0|1] "" IHU
 SG_ TelmExtrLiFileDeleteReq_UB : 24|1@0+ (1,0) [0|1] "" IHU
 SG_ TelmExtrLiFileDeleteReqID : 31|5@0+ (1.0,0.0) [0.0|31.0] "Unitless" IHU
 SG_ TelmExtrLiFileDeleteReqNoReqOnOff : 26|2@0+ (1,0) [0|3] "" IHU
 SG_ TelmExtrLiFileDownloadReq_UB : 32|1@0+ (1,0) [0|1] "" IHU
 SG_ TelmExtrLiFileDownloadReqID : 39|5@0+ (1.0,0.0) [0.0|31.0] "Unitless" IHU
 SG_ TelmExtrLiFileDownloadReqNoReqOnOff : 34|2@0+ (1,0) [0|3] "" IHU
 SG_ TelmExtrLiShowReq_UB : 40|1@0+ (1,0) [0|1] "" IHU
 SG_ TelmExtrLiShowReqID : 47|5@0+ (1.0,0.0) [0.0|31.0] "Unitless" IHU
 SG_ TelmExtrLiShowReqNoReqOnOff : 42|2@0+ (1,0) [0|3] "" IHU
 SG_ TelmStrangePassWordSet_UB : 67|1@0+ (1,0) [0|1] "" IHU
 SG_ TelmStrangePassWordSetNo1 : 55|4@0+ (1.0,0.0) [0.0|9.0] "Unitless" IHU
 SG_ TelmStrangePassWordSetNo2 : 51|4@0+ (1.0,0.0) [0.0|9.0] "Unitless" IHU
 SG_ TelmStrangePassWordSetNo3 : 63|4@0+ (1.0,0.0) [0.0|9.0] "Unitless" IHU
 SG_ TelmStrangePassWordSetNo4 : 59|4@0+ (1.0,0.0) [0.0|9.0] "Unitless" IHU
 SG_ TelmStrangerModStopCtrlReq : 69|1@0+ (1,0) [0|1] "" IHU
 SG_ TelmStrangerModStopCtrlReq_UB : 68|1@0+ (1,0) [0|1] "" IHU

BO_ 544 TcamConnCANFDFr09 : 64 TCAM
 SG_ BiasedPosnFromSatlt1_UB : 71|1@0+ (1,0) [0|1] "" IHU
 SG_ BiasedPosnFromSatlt1Cntr : 58|3@0+ (1.0,0.0) [0.0|7.0] "Unitless" IHU
 SG_ BiasedPosnFromSatlt1PosnLat : 7|30@0- (0.000000277778,0.0) [-90.000072|90.000072] "Deg" IHU
 SG_ BiasedPosnFromSatlt1PosnLgt : 25|31@0- (0.000000277778,0.0) [-180.000144|180.000144] "Deg" IHU
 SG_ GNSSSolution1_UB : 135|1@0+ (1,0) [0|1] "" IHU
 SG_ GNSSSolution1Cntr : 79|3@0+ (1.0,0.0) [0.0|7.0] "Unitless" IHU
 SG_ GNSSSolution1NoOfSatItForSysNo1 : 76|5@0+ (1.0,0.0) [0.0|31.0] "Unitless" IHU
 SG_ GNSSSolution1NoOfSatItForSysNo2 : 84|5@0+ (1.0,0.0) [0.0|31.0] "Unitless" IHU
 SG_ GNSSSolution1NoOfSatItForSysNo3 : 92|5@0+ (1.0,0.0) [0.0|31.0] "Unitless" IHU
 SG_ GNSSSolution1NoOfSatItForSysNo4 : 100|5@0+ (1.0,0.0) [0.0|31.0] "Unitless" IHU
 SG_ GNSSSolution1NoOfSatItForSysNo5 : 108|5@0+ (1.0,0.0) [0.0|31.0] "Unitless" IHU
 SG_ GNSSSolution1NoOfSatItForSysNo6 : 116|5@0+ (1.0,0.0) [0.0|31.0] "Unitless" IHU
 SG_ GNSSSolution1NoOfSatItForSysNo7 : 124|5@0+ (1.0,0.0) [0.0|31.0] "Unitless" IHU
 SG_ GNSSSolution1SatItSysNo1InUse : 85|1@0+ (1,0) [0|1] "" IHU
 SG_ GNSSSolution1SatItSysNo2InUse : 86|1@0+ (1,0) [0|1] "" IHU
 SG_ GNSSSolution1SatItSysNo3InUse : 87|1@0+ (1,0) [0|1] "" IHU
 SG_ GNSSSolution1SatItSysNo4InUse : 93|1@0+ (1,0) [0|1] "" IHU
 SG_ GNSSSolution1SatItSysNo5InUse : 94|1@0+ (1,0) [0|1] "" IHU
 SG_ GNSSSolution1SatItSysNo6InUse : 95|1@0+ (1,0) [0|1] "" IHU
 SG_ GNSSSolution1SatItSysNo7InUse : 101|1@0+ (1,0) [0|1] "" IHU
 SG_ GNSSSolution1SatltPosnStsPrm1 : 103|2@0+ (1,0) [0|3] "" IHU
 SG_ GNSSSolution1SatltPosnStsPrm2 : 109|1@0+ (1,0) [0|1] "" IHU
 SG_ GNSSSolution2_UB : 131|1@0+ (1,0) [0|1] "" IHU
 SG_ GNSSSolution2Cntr : 130|3@0+ (1.0,0.0) [0.0|7.0] "Unitless" IHU
 SG_ GNSSSolution2PreHozlDil : 143|8@0+ (0.1,0.0) [0.0|25.5] "Unitless" IHU
 SG_ GNSSSolution2PrePosnDil : 151|8@0+ (0.1,0.0) [0.0|25.5] "Unitless" IHU
 SG_ GNSSSolution2PreVertDil : 159|8@0+ (0.1,0.0) [0.0|25.5] "Unitless" IHU
 SG_ ImobVehRemReqAndResp_UB : 163|1@0+ (1,0) [0|1] "" IHU
 SG_ ImobVehRemReqAndRespImobVehDataRemReq0 : 175|8@0+ (1.0,0.0) [0.0|255.0] "Unitless" IHU
 SG_ ImobVehRemReqAndRespImobVehDataRemReq1 : 183|8@0+ (1.0,0.0) [0.0|255.0] "Unitless" IHU
 SG_ ImobVehRemReqAndRespImobVehDataRemReq2 : 191|8@0+ (1.0,0.0) [0.0|255.0] "Unitless" IHU
 SG_ ImobVehRemReqAndRespImobVehDataRemReq3 : 199|8@0+ (1.0,0.0) [0.0|255.0] "Unitless" IHU
 SG_ ImobVehRemReqAndRespImobVehDataRemReq4 : 207|8@0+ (1.0,0.0) [0.0|255.0] "Unitless" IHU
 SG_ ImobVehRemReqAndRespImobVehRemReqCmd : 162|3@0+ (1,0) [0|7] "" IHU
 SG_ ImobVehRemReqAndRespImobVehRemTmrOrSpdLim : 215|8@0+ (1.0,0.0) [0.0|255.0] "Unitless" IHU
 SG_ LowrReAxle : 70|1@0+ (1,0) [0|1] "" IHU
 SG_ LowrReAxle_UB : 69|1@0+ (1,0) [0|1] "" IHU
 SG_ MobDevDistSts1 : 361|10@0+ (1.0,0.0) [0.0|1023.0] "cm" IHU
 SG_ MobDevDistSts1_UB : 362|1@0+ (1,0) [0|1] "" IHU
 SG_ MobDevRCVReq1_UB : 383|1@0+ (1,0) [0|1] "" IHU
 SG_ MobDevRCVReq1Chks : 399|8@0+ (1.0,0.0) [0.0|255.0] "Unitless" IHU
 SG_ MobDevRCVReq1Cntr : 407|4@0+ (1.0,0.0) [0.0|15.0] "Unitless" IHU
 SG_ MobDevRCVReq1MobDevSts : 391|8@0+ (1.0,0.0) [0.0|255.0] "Unitless" IHU
 SG_ MobDevRCVReq1RCVCtrl : 379|4@0+ (1,0) [0|15] "" IHU
 SG_ MobDevRCVReq1Steertrim : 382|3@0+ (1,0) [0|7] "" IHU
 SG_ PosnFromSatlt1_UB : 223|1@0+ (1,0) [0|1] "" IHU
 SG_ PosnFromSatlt1Cntr : 287|3@0+ (1.0,0.0) [0.0|7.0] "Unitless" IHU
 SG_ PosnFromSatlt1PosnLat : 255|30@0- (0.000000277778,0.0) [-90.000072|90.000072] "Deg" IHU
 SG_ PosnFromSatlt1PosnLgt : 222|31@0- (0.000000277778,0.0) [-180.000144|180.000144] "Deg" IHU
 SG_ PosnFromSatlt2_UB : 284|1@0+ (1,0) [0|1] "" IHU
 SG_ PosnFromSatlt2Cntr : 283|3@0+ (1.0,0.0) [0.0|7.0] "Unitless" IHU
 SG_ PosnFromSatlt2PosnSpdosn : 280|17@0+ (0.001,0.0) [0.0|100.0] "m/s" IHU
 SG_ PosnFromSatlt3_UB : 364|1@0+ (1,0) [0|1] "" IHU
 SG_ PosnFromSatlt3Cntr : 367|3@0+ (1.0,0.0) [0.0|7.0] "Unitless" IHU
 SG_ PosnFromSatlt3PosnAlti : 311|16@0+ (0.1,-100.0) [-100.0|6000.0] "m" IHU
 SG_ PosnFromSatlt3PosnDir : 327|16@0+ (0.01,0.0) [0.0|359.99] "Deg" IHU
 SG_ PosnFromSatlt3TiForMins : 349|6@0+ (1.0,0.0) [0.0|59.0] "Mins" IHU
 SG_ PosnFromSatlt3TiForMsec : 343|10@0+ (1.0,0.0) [0.0|1023.0] "Unitless" IHU
 SG_ PosnFromSatlt3TiForSec : 359|6@0+ (1.0,0.0) [0.0|59.0] "s" IHU
 SG_ UWBKeyDistrictSts_UB : 400|1@0+ (1,0) [0|1] "" IHU
 SG_ UWBKeyDistrictStsKey0 : 415|4@0+ (1,0) [0|15] "" IHU
 SG_ UWBKeyDistrictStsKey1 : 411|4@0+ (1,0) [0|15] "" IHU
 SG_ UWBKeyDistrictStsKey2 : 423|4@0+ (1,0) [0|15] "" IHU
 SG_ UWBKeyDistrictStsKey3 : 419|4@0+ (1,0) [0|15] "" IHU

BO_ 80 TcamConnCANFDFr10 : 64 TCAM
 SG_ SpdLimdSts : 0|1@0+ (1,0) [0|1] "" IHU
 SG_ SpdLimdSts_UB : 1|1@0+ (1,0) [0|1] "" IHU

BO_ 337 TcamConnCANFDSycnReqFr : 1 TCAM
 SG_ TripResetSyncReqMsgTCAM : 7|8@0+ (1.0,0.0) [0.0|255.0] "Unitless" IHU

BO_ 1353 TcamConnCANFDVFCVectorFr : 8 TCAM
 SG_ VFCVectorTCAMBlockID : 1|2@0+ (1.0,0.0) [0.0|3.0] "Unitless" IHU
 SG_ VFCVectorTCAMVFCid0 : 2|1@0+ (1,0) [0|1] "" IHU
 SG_ VFCVectorTCAMVFCid1 : 3|1@0+ (1,0) [0|1] "" IHU
 SG_ VFCVectorTCAMVFCid10 : 12|1@0+ (1,0) [0|1] "" IHU
 SG_ VFCVectorTCAMVFCid11 : 13|1@0+ (1,0) [0|1] "" IHU
 SG_ VFCVectorTCAMVFCid12 : 14|1@0+ (1,0) [0|1] "" IHU
 SG_ VFCVectorTCAMVFCid13 : 15|1@0+ (1,0) [0|1] "" IHU
 SG_ VFCVectorTCAMVFCid14 : 16|1@0+ (1,0) [0|1] "" IHU
 SG_ VFCVectorTCAMVFCid15 : 17|1@0+ (1,0) [0|1] "" IHU
 SG_ VFCVectorTCAMVFCid16 : 18|1@0+ (1,0) [0|1] "" IHU
 SG_ VFCVectorTCAMVFCid17 : 19|1@0+ (1,0) [0|1] "" IHU
 SG_ VFCVectorTCAMVFCid18 : 20|1@0+ (1,0) [0|1] "" IHU
 SG_ VFCVectorTCAMVFCid19 : 21|1@0+ (1,0) [0|1] "" IHU
 SG_ VFCVectorTCAMVFCid2 : 4|1@0+ (1,0) [0|1] "" IHU
 SG_ VFCVectorTCAMVFCid20 : 22|1@0+ (1,0) [0|1] "" IHU
 SG_ VFCVectorTCAMVFCid21 : 23|1@0+ (1,0) [0|1] "" IHU
 SG_ VFCVectorTCAMVFCid22 : 24|1@0+ (1,0) [0|1] "" IHU
 SG_ VFCVectorTCAMVFCid23 : 25|1@0+ (1,0) [0|1] "" IHU
 SG_ VFCVectorTCAMVFCid24 : 26|1@0+ (1,0) [0|1] "" IHU
 SG_ VFCVectorTCAMVFCid25 : 27|1@0+ (1,0) [0|1] "" IHU
 SG_ VFCVectorTCAMVFCid26 : 28|1@0+ (1,0) [0|1] "" IHU
 SG_ VFCVectorTCAMVFCid27 : 29|1@0+ (1,0) [0|1] "" IHU
 SG_ VFCVectorTCAMVFCid28 : 30|1@0+ (1,0) [0|1] "" IHU
 SG_ VFCVectorTCAMVFCid29 : 31|1@0+ (1,0) [0|1] "" IHU
 SG_ VFCVectorTCAMVFCid3 : 5|1@0+ (1,0) [0|1] "" IHU
 SG_ VFCVectorTCAMVFCid30 : 32|1@0+ (1,0) [0|1] "" IHU
 SG_ VFCVectorTCAMVFCid31 : 33|1@0+ (1,0) [0|1] "" IHU
 SG_ VFCVectorTCAMVFCid32 : 34|1@0+ (1,0) [0|1] "" IHU
 SG_ VFCVectorTCAMVFCid33 : 35|1@0+ (1,0) [0|1] "" IHU
 SG_ VFCVectorTCAMVFCid34 : 36|1@0+ (1,0) [0|1] "" IHU
 SG_ VFCVectorTCAMVFCid35 : 37|1@0+ (1,0) [0|1] "" IHU
 SG_ VFCVectorTCAMVFCid36 : 38|1@0+ (1,0) [0|1] "" IHU
 SG_ VFCVectorTCAMVFCid37 : 39|1@0+ (1,0) [0|1] "" IHU
 SG_ VFCVectorTCAMVFCid38 : 40|1@0+ (1,0) [0|1] "" IHU
 SG_ VFCVectorTCAMVFCid39 : 41|1@0+ (1,0) [0|1] "" IHU
 SG_ VFCVectorTCAMVFCid4 : 6|1@0+ (1,0) [0|1] "" IHU
 SG_ VFCVectorTCAMVFCid40 : 42|1@0+ (1,0) [0|1] "" IHU
 SG_ VFCVectorTCAMVFCid41 : 43|1@0+ (1,0) [0|1] "" IHU
 SG_ VFCVectorTCAMVFCid42 : 44|1@0+ (1,0) [0|1] "" IHU
 SG_ VFCVectorTCAMVFCid43 : 45|1@0+ (1,0) [0|1] "" IHU
 SG_ VFCVectorTCAMVFCid44 : 46|1@0+ (1,0) [0|1] "" IHU
 SG_ VFCVectorTCAMVFCid45 : 47|1@0+ (1,0) [0|1] "" IHU
 SG_ VFCVectorTCAMVFCid46 : 48|1@0+ (1,0) [0|1] "" IHU
 SG_ VFCVectorTCAMVFCid47 : 49|1@0+ (1,0) [0|1] "" IHU
 SG_ VFCVectorTCAMVFCid48 : 50|1@0+ (1,0) [0|1] "" IHU
 SG_ VFCVectorTCAMVFCid49 : 51|1@0+ (1,0) [0|1] "" IHU
 SG_ VFCVectorTCAMVFCid5 : 7|1@0+ (1,0) [0|1] "" IHU
 SG_ VFCVectorTCAMVFCid50 : 52|1@0+ (1,0) [0|1] "" IHU
 SG_ VFCVectorTCAMVFCid51 : 53|1@0+ (1,0) [0|1] "" IHU
 SG_ VFCVectorTCAMVFCid52 : 54|1@0+ (1,0) [0|1] "" IHU
 SG_ VFCVectorTCAMVFCid53 : 55|1@0+ (1,0) [0|1] "" IHU
 SG_ VFCVectorTCAMVFCid54 : 56|1@0+ (1,0) [0|1] "" IHU
 SG_ VFCVectorTCAMVFCid55 : 57|1@0+ (1,0) [0|1] "" IHU
 SG_ VFCVectorTCAMVFCid56 : 58|1@0+ (1,0) [0|1] "" IHU
 SG_ VFCVectorTCAMVFCid57 : 59|1@0+ (1,0) [0|1] "" IHU
 SG_ VFCVectorTCAMVFCid58 : 60|1@0+ (1,0) [0|1] "" IHU
 SG_ VFCVectorTCAMVFCid59 : 61|1@0+ (1,0) [0|1] "" IHU
 SG_ VFCVectorTCAMVFCid6 : 8|1@0+ (1,0) [0|1] "" IHU
 SG_ VFCVectorTCAMVFCid60 : 62|1@0+ (1,0) [0|1] "" IHU
 SG_ VFCVectorTCAMVFCid61 : 63|1@0+ (1,0) [0|1] "" IHU
 SG_ VFCVectorTCAMVFCid7 : 9|1@0+ (1,0) [0|1] "" IHU
 SG_ VFCVectorTCAMVFCid8 : 10|1@0+ (1,0) [0|1] "" IHU
 SG_ VFCVectorTCAMVFCid9 : 11|1@0+ (1,0) [0|1] "" IHU

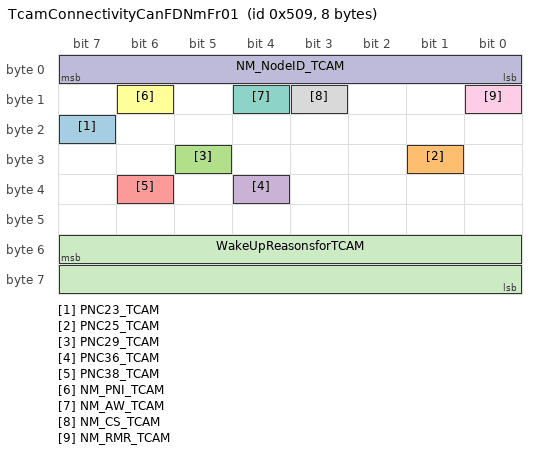
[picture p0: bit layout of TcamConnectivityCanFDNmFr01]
BO_ 1289 TcamConnectivityCanFDNmFr01 : 8 TCAM
 SG_ PNC23_TCAM : 23|1@0+ (1,0) [0|0] "" Vector__XXX
 SG_ PNC25_TCAM : 25|1@0+ (1,0) [0|0] "" Vector__XXX
 SG_ PNC29_TCAM : 29|1@0+ (1,0) [0|0] "" Vector__XXX
 SG_ PNC36_TCAM : 36|1@0+ (1,0) [0|0] "" Vector__XXX
 SG_ PNC38_TCAM : 38|1@0+ (1,0) [0|0] "" Vector__XXX
 SG_ NM_PNI_TCAM : 14|1@0+ (1,0) [0|0] "" Vector__XXX
 SG_ NM_AW_TCAM : 12|1@0+ (1,0) [0|0] "" Vector__XXX
 SG_ NM_CS_TCAM : 11|1@0+ (1,0) [0|0] "" Vector__XXX
 SG_ NM_RMR_TCAM : 8|1@0+ (1,0) [0|0] "" Vector__XXX
 SG_ NM_NodeID_TCAM : 7|8@0+ (1,0) [0|0] "" Vector__XXX

 SG_ WakeUpReasonsforTCAM : 55|16@0+ (1,0) [0|65535] "" Vector__XXX

BO_ 338 TcamToDhuSecOCFr01 : 64 TCAM
 SG_ DigKeyReqSts : 7|4@0+ (1,0) [0|15] "" IHU
 SG_ DigKeyReqSts_UB : 3|1@0+ (1,0) [0|1] "" IHU

BO_ 1574 Wpc3ToDhuConnectivityCANFDDiagResFrame : 64 TCAM

CM_ SG_ 176 ApproachReqData1 "data";
CM_ SG_ 176 ApproachReqData10 "data";
CM_ SG_ 176 ApproachReqData11 "data";
CM_ SG_ 176 ApproachReqData12 "data";
CM_ SG_ 176 ApproachReqData13 "data";
CM_ SG_ 176 ApproachReqData14 "data";
CM_ SG_ 176 ApproachReqData15 "data";
CM_ SG_ 176 ApproachReqData16 "data";
CM_ SG_ 176 ApproachReqData2 "data";
CM_ SG_ 176 ApproachReqData3 "data";
CM_ SG_ 176 ApproachReqData4 "data";
CM_ SG_ 176 ApproachReqData5 "data";
CM_ SG_ 176 ApproachReqData6 "data";
CM_ SG_ 176 ApproachReqData7 "data";
CM_ SG_ 176 ApproachReqData8 "data";
CM_ SG_ 176 ApproachReqData9 "data";
CM_ SG_ 176 BLEKeySearchRespData1 "data";
CM_ SG_ 176 BLEKeySearchRespData10 "data";
CM_ SG_ 176 BLEKeySearchRespData11 "data";
CM_ SG_ 176 BLEKeySearchRespData12 "data";
CM_ SG_ 176 BLEKeySearchRespData13 "data";
CM_ SG_ 176 BLEKeySearchRespData14 "data";
CM_ SG_ 176 BLEKeySearchRespData15 "data";
CM_ SG_ 176 BLEKeySearchRespData16 "data";
CM_ SG_ 176 BLEKeySearchRespData2 "data";
CM_ SG_ 176 BLEKeySearchRespData3 "data";
CM_ SG_ 176 BLEKeySearchRespData4 "data";
CM_ SG_ 176 BLEKeySearchRespData5 "data";
CM_ SG_ 176 BLEKeySearchRespData6 "data";
CM_ SG_ 176 BLEKeySearchRespData7 "data";
CM_ SG_ 176 BLEKeySearchRespData8 "data";
CM_ SG_ 176 BLEKeySearchRespData9 "data";
CM_ SG_ 176 DigKeyDataToHMIAcknowledgment "ACK";
CM_ SG_ 176 DigKeyDataToHMIDKDataByte1 "DATA";
CM_ SG_ 176 DigKeyDataToHMIDKDataByte2 "DATA";
CM_ SG_ 176 DigKeyDataToHMIDKDataByte3 "DATA";
CM_ SG_ 176 DigKeyDataToHMIDKDataByte4 "DATA";
CM_ SG_ 176 DigKeyDataToHMIDKDataByte5 "DATA";
CM_ SG_ 176 DigKeyDataToHMIDKDataByte6 "DATA";
CM_ SG_ 176 DigKeyDataToHMIHeader "Header";
CM_ SG_ 176 NFCAndBLEKeyEnaStsData1 "data";
CM_ SG_ 176 NFCAndBLEKeyEnaStsData10 "data";
CM_ SG_ 176 NFCAndBLEKeyEnaStsData11 "data";
CM_ SG_ 176 NFCAndBLEKeyEnaStsData12 "data";
CM_ SG_ 176 NFCAndBLEKeyEnaStsData13 "data";
CM_ SG_ 176 NFCAndBLEKeyEnaStsData14 "data";
CM_ SG_ 176 NFCAndBLEKeyEnaStsData15 "data";
CM_ SG_ 176 NFCAndBLEKeyEnaStsData16 "data";
CM_ SG_ 176 NFCAndBLEKeyEnaStsData2 "data";
CM_ SG_ 176 NFCAndBLEKeyEnaStsData3 "data";
CM_ SG_ 176 NFCAndBLEKeyEnaStsData4 "data";
CM_ SG_ 176 NFCAndBLEKeyEnaStsData5 "data";
CM_ SG_ 176 NFCAndBLEKeyEnaStsData6 "data";
CM_ SG_ 176 NFCAndBLEKeyEnaStsData7 "data";
CM_ SG_ 176 NFCAndBLEKeyEnaStsData8 "data";
CM_ SG_ 176 NFCAndBLEKeyEnaStsData9 "data";
CM_ SG_ 336 BattPreHeatgLvl "Battery heating level chosen by user in the book travel function";
CM_ SG_ 336 BattPreHeatgTiDif "Time difference between the current time and the departure time";
CM_ SG_ 336 BookChrgnActvdReq "Book Charging ACtivted Request";
CM_ SG_ 336 BookStopTiAchieved "Stop charging time Achieved";
CM_ SG_ 336 BookTrvlClimaActvReq "The request to activate air conditioning for the booking travel function with climate control";
CM_ SG_ 336 CarFindrHornLiReqFromTelm "Request signal from Telematics to activate the Car Locator Horn and Light function (FR Mobile App).";
CM_ SG_ 336 CbnOverHeatProtnEnaFromTelm "Users activate or inactivate the cabin overheat protection function through mobile app";
CM_ SG_ 336 ChrgLidTelmLockgReq "Release request for charging lid unlocking by phone App.";
CM_ SG_ 336 ChrgnCtrlToEndOrRetartFromApp "this signal is use for end DC or AC charging control  and use for  end discharging control ";
CM_ SG_ 336 ClimaRqrd1 "Request signal from Telematics to start or stop a remote pre-climatization.";
CM_ SG_ 336 ClimaTmrStsTelmRqrd "Pre-climatization  Indicate  an active time ";
CM_ SG_ 336 CnclBookTrvlReq "A cancel request of the reservation departure function";
CM_ SG_ 336 DigKeyGidInfo1Byte0 "digilate key GID info1";
CM_ SG_ 336 DigKeyGidInfo1Byte1 "digilate key GID info2";
CM_ SG_ 336 DigKeyGidInfo1Byte2 "digilate key GID info3";
CM_ SG_ 336 DigKeyGidInfo1Byte3 "digilate key GID info4";
CM_ SG_ 336 DigKeyGidInfo1Byte4 "digilate key GID info5";
CM_ SG_ 336 DigKeyGidInfo1Byte5 "digilate key GID info6";
CM_ SG_ 336 DigKeyGidInfo1Byte6 "digilate key GID info7";
CM_ SG_ 336 DigKeyGidInfo1Byte7 "digilate key GID info8";
CM_ SG_ 336 DigKeyGidInfo2Byte0 "digilate key GID info9";
CM_ SG_ 336 DigKeyGidInfo2Byte1 "digilate key GID info10";
CM_ SG_ 336 DigKeyGidInfo2Byte2 "digilate key GID info11";
CM_ SG_ 336 DigKeyGidInfo2Byte3 "digilate key GID InfoResv1";
CM_ SG_ 336 DigKeyGidInfo2Byte4 "digilate key GID InfoResv2";
CM_ SG_ 336 DigKeyGidInfo2Byte5 "digilate key GID InfoResv3";
CM_ SG_ 336 DigKeyGidInfo2Byte6 "digilate key GID InfoResv4";
CM_ SG_ 336 DigKeyGidInfo2Byte7 "digilate key GID InfoResv5";
CM_ SG_ 336 DKDataFromTelmAcknowledgment "Packet received acknowledgement";
CM_ SG_ 336 DKDataFromTelmDKDataByte1 "Byte number 1";
CM_ SG_ 336 DKDataFromTelmDKDataByte2 "Byte number 2";
CM_ SG_ 336 DKDataFromTelmDKDataByte3 "Byte number 3";
CM_ SG_ 336 DKDataFromTelmDKDataByte4 "Byte number 4";
CM_ SG_ 336 DKDataFromTelmDKDataByte5 "Byte number 5";
CM_ SG_ 336 DKDataFromTelmDKDataByte6 "Byte number 6";
CM_ SG_ 336 DKDataFromTelmHeader "Packet Header";
CM_ SG_ 336 EmgyAsscTrigSts "Defined the signal as:
0: when the eCall without trigget
1: eCall been automatically trigget by SRS
2: eCall been manually trigget by user via SOS button
3: eCall has fault when SRS trigget crash   ";
CM_ SG_ 336 EngForbidReqFromTelm "remote forbid engine start";
CM_ SG_ 336 EngPermitReqFromTelm "remote permit engine start";
CM_ SG_ 336 ErsCmdRecErsCmd "Ers command signal";
CM_ SG_ 336 ErsCmdRecErsRunTime "How long time to run ERS";
CM_ SG_ 336 MemPosnFromTelm "memory position from TSP";
CM_ SG_ 336 RemACChrgLidTelmReq "Remote DC charge lid open/close request";
CM_ SG_ 336 RemBookChrgnTarVal "Remote Book Charging Target Value";
CM_ SG_ 336 RemChkTInVeh "Remote Check Temperature In Vehicle";
CM_ SG_ 336 RemDCChrgLidTelmReq "Remote DC charge lid open/close request";
CM_ SG_ 336 RemsSetDchaTarVal "remote setting the discharging SOC";
CM_ SG_ 336 RemVentReq "remote cockpit ventilate request";
CM_ SG_ 336 ReqFragLvlTelm "remote  Fragrance lever request";
CM_ SG_ 336 SeatHeatDurgClimaEnadFromTelm "Request signal from Telematics to start the seat heater during a pre-climatization.";
CM_ SG_ 336 SteerWhlHeatgDurgClimaEnadFromTelm "Request signal from Telematics to start the stearing wheel heater during a pre-climatization.";
CM_ SG_ 336 SunRoofAndCurtCmdTelm " sunRoof and Curt Remote Command ";
CM_ SG_ 336 TankFlapTelmLockgReq "LockActvnOff";
CM_ SG_ 336 TelmAirFragTasteReq "remote Fragrance channel Taste request";
CM_ SG_ 336 TelmBookChrgnReq "Telm Book Chrgn Request form APP";
CM_ SG_ 336 TelmBookClimaReqHmiCmptmtTSpSpcl "Climate mode Normal/Lo/Hi";
CM_ SG_ 336 TelmBookClimaReqOnOffNoReq "Climate request On/Off";
CM_ SG_ 336 TelmBookClimaReqTempRange "Climate temperature set";
CM_ SG_ 336 TelmBookClimaTmr "Telm Book Clima Timer Set";
CM_ SG_ 336 TelmBookSeatHeatClimalReqDrvHeatClimaLvl "driver seat heat level for booking climate";
CM_ SG_ 336 TelmBookSeatHeatClimalReqPassHeatClimaLvl "passenger seat heat level for booking climate";
CM_ SG_ 336 TelmBookSeatHeatClimalReqSecLeHeatClimaLvl "second left seat heat level for booking climate";
CM_ SG_ 336 TelmBookSeatHeatClimalReqSecRiHeatClimaLvl "second right seat heat level for booking climate";
CM_ SG_ 336 TelmBookSeatHeatClimalReqThrdLeHeatClimaLvl "third left seat heat level for booking climate";
CM_ SG_ 336 TelmBookSeatHeatClimalReqThrdRiHeatClimaLvl "third right seat heat level for booking climate";
CM_ SG_ 336 TelmBookSeatVentnClimalReqDrvVentnClimaLvl "driver seat ventilate level for booking climate";
CM_ SG_ 336 TelmBookSeatVentnClimalReqPassVentnClimaLvl "passenger seat ventilate level for booking climate";
CM_ SG_ 336 TelmBookSeatVentnClimalReqSecLeVentnClimaLvl "second left seat ventilate level for booking climate";
CM_ SG_ 336 TelmBookSeatVentnClimalReqSecRiVentnClimaLvl "second right seat ventilate level for booking climate";
CM_ SG_ 336 TelmBookSeatVentnClimalReqThrdLeVentnClimaLvl "third left seat ventilate level for booking climate";
CM_ SG_ 336 TelmBookSeatVentnClimalReqThrdRiVentnClimaL "third right seat ventilate level for booking climate";
CM_ SG_ 336 TelmBookSteerWhlHeatClimalReq "Telm Book Steer Whleel Heat Request On/Off";
CM_ SG_ 336 TelmClimaReq "remote climate start request";
CM_ SG_ 336 TelmClimaTmr "Pre-climatization activated timer from telematics.";
CM_ SG_ 336 TelmClimaTSetHmiCmptmtTSpSpcl "remote climate temperature setting status";
CM_ SG_ 336 TelmClimaTSetTempRange "remote climate temperature setting";
CM_ SG_ 336 TelmDefrostReq "Remote defrost request
";
CM_ SG_ 336 TelmEngDelayTi "remote engine delay time";
CM_ SG_ 336 TelmFctReq "Telematis Function Request";
CM_ SG_ 336 TelmLockgCenReqReqTyp "Request signal from Telematics to central lock/unlock the vehicle or to unlock via tailgate enabled. (VEH-FCT : S-83-06 Vehicle LockingUnlocking / SPA; 0) Request type";
CM_ SG_ 336 TelmLockgCenReqTiVld "Request signal from Telematics to central lock/unlock the vehicle or to unlock via tailgate enabled. (VEH-FCT : S-83-06 Vehicle LockingUnlocking / SPA; 0) Valid time";
CM_ SG_ 336 TelmPM25Req "remote PM2.5request";
CM_ SG_ 336 TelmPreClimaPrio "Energy prioritization mode for pre-climatization";
CM_ SG_ 336 TelmSeatDrvHeatClimaLvl "remote driver seat heating level";
CM_ SG_ 336 TelmSeatDrvVentnClimaLvl "remote driver seat ventilate level";
CM_ SG_ 336 TelmSeatPassHeatClimaLvl "remote Passer seat heating level";
CM_ SG_ 336 TelmSeatPassVentnClimaLvl "remote passer seat ventilate level";
CM_ SG_ 336 TelmSeatSecLeHeatClimaLvl "remote second left seat heating level";
CM_ SG_ 336 TelmSeatSecLeVentnClimaLvl "remote second left seat ventilate level";
CM_ SG_ 336 TelmSeatSecRiHeatClimaLvl "remote second right seat heating level";
CM_ SG_ 336 TelmSeatSecRiVentnClimaLvl "remote second right seat ventilate level";
CM_ SG_ 336 TelmSeatThrdLeHeatClimaLvl "remote third left seat heat level";
CM_ SG_ 336 TelmSeatThrdLeVentnClimaLvl "remote third left seat ventilate level";
CM_ SG_ 336 TelmSeatThrdRiHeatClimaLvl "remote third right seat heat level";
CM_ SG_ 336 TelmSeatThrdRiVentnClimaLvl "remote third right seat ventilate level";
CM_ SG_ 336 TelmStrtEngForChrgnReq "remote start engine request for discharging";
CM_ SG_ 336 TelmThermoTankReq1 "Remote Thermotank Control request";
CM_ SG_ 336 TelmThermoTankT "temperature setting for Remote Thermotank Control ";
CM_ SG_ 336 TelmThermoTankTmr1 "Running time setting for Remote Thermotank Control ";
CM_ SG_ 336 UnlockAndLogInAccountReq "Unlock And Log In Account Request on or off";
CM_ SG_ 336 WinOpenClsGlbReqFromTelmWindowOpenValue "Windows open value pec open 1-100";
CM_ SG_ 336 WinOpenClsGlbReqFromTelmWinOpenClsGlbSts "remote global windows open and closed command request from telematics";
CM_ SG_ 192 DKDataFromBLEAcknowledgment "ACK";
CM_ SG_ 192 DKDataFromBLEDKDataByte1 "data";
CM_ SG_ 192 DKDataFromBLEDKDataByte2 "data";
CM_ SG_ 192 DKDataFromBLEDKDataByte3 "data";
CM_ SG_ 192 DKDataFromBLEDKDataByte4 "data";
CM_ SG_ 192 DKDataFromBLEDKDataByte5 "data";
CM_ SG_ 192 DKDataFromBLEDKDataByte6 "data";
CM_ SG_ 192 DKDataFromBLEHeader "header";
CM_ SG_ 192 DKDataFromTelm1Acknowledgment "ACK";
CM_ SG_ 192 DKDataFromTelm1DKDataByte1 "data";
CM_ SG_ 192 DKDataFromTelm1DKDataByte2 "data";
CM_ SG_ 192 DKDataFromTelm1DKDataByte3 "data";
CM_ SG_ 192 DKDataFromTelm1DKDataByte4 "data";
CM_ SG_ 192 DKDataFromTelm1DKDataByte5 "data";
CM_ SG_ 192 DKDataFromTelm1DKDataByte6 "data";
CM_ SG_ 192 DKDataFromTelm1Header "header";
CM_ SG_ 192 NFCKeySearchRespData1 "data";
CM_ SG_ 192 NFCKeySearchRespData10 "data";
CM_ SG_ 192 NFCKeySearchRespData11 "data";
CM_ SG_ 192 NFCKeySearchRespData12 "data";
CM_ SG_ 192 NFCKeySearchRespData13 "data";
CM_ SG_ 192 NFCKeySearchRespData14 "data";
CM_ SG_ 192 NFCKeySearchRespData15 "data";
CM_ SG_ 192 NFCKeySearchRespData16 "data";
CM_ SG_ 192 NFCKeySearchRespData2 "data";
CM_ SG_ 192 NFCKeySearchRespData3 "data";
CM_ SG_ 192 NFCKeySearchRespData4 "data";
CM_ SG_ 192 NFCKeySearchRespData5 "data";
CM_ SG_ 192 NFCKeySearchRespData6 "data";
CM_ SG_ 192 NFCKeySearchRespData7 "data";
CM_ SG_ 192 NFCKeySearchRespData8 "data";
CM_ SG_ 192 NFCKeySearchRespData9 "data";
CM_ SG_ 192 RKEAndNFCReqStsData1 "data";
CM_ SG_ 192 RKEAndNFCReqStsData10 "data";
CM_ SG_ 192 RKEAndNFCReqStsData11 "data";
CM_ SG_ 192 RKEAndNFCReqStsData12 "data";
CM_ SG_ 192 RKEAndNFCReqStsData13 "data";
CM_ SG_ 192 RKEAndNFCReqStsData14 "data";
CM_ SG_ 192 RKEAndNFCReqStsData15 "data";
CM_ SG_ 192 RKEAndNFCReqStsData16 "data";
CM_ SG_ 192 RKEAndNFCReqStsData2 "data";
CM_ SG_ 192 RKEAndNFCReqStsData3 "data";
CM_ SG_ 192 RKEAndNFCReqStsData4 "data";
CM_ SG_ 192 RKEAndNFCReqStsData5 "data";
CM_ SG_ 192 RKEAndNFCReqStsData6 "data";
CM_ SG_ 192 RKEAndNFCReqStsData7 "data";
CM_ SG_ 192 RKEAndNFCReqStsData8 "data";
CM_ SG_ 192 RKEAndNFCReqStsData9 "data";
CM_ SG_ 320 GuestrSts1Chks "checksum calculation";
CM_ SG_ 320 GuestrSts1Cntr "E2E counter";
CM_ SG_ 320 GuestrSts1Validity "Guesture status";
CM_ SG_ 320 KickTailgateSig "UWB kick tailgate signal";
CM_ SG_ 320 MobDevRPAAuthResp1Answer "answer";
CM_ SG_ 320 MobDevRPAAuthResp1Chks "checksum calculation";
CM_ SG_ 320 MobDevRPAAuthResp1Cntr "E2E counter";
CM_ SG_ 320 MobDevRPAAuthResp1X "x";
CM_ SG_ 320 MobDevRPAAuthResp1Y "y";
CM_ SG_ 320 MobDevRPAReq1Chks "Checksum calculation for E2E";
CM_ SG_ 320 MobDevRPAReq1Cntr "E2E counter";
CM_ SG_ 320 MobDevRPAReq1MobDevSts "mobile device status";
CM_ SG_ 320 MobDevRPAReq1RPAOutModeSubT "RPA Out Mode Direction";
CM_ SG_ 320 MobDevRPAReq1RPAReq "RPA control";
CM_ SG_ 320 MobDevRPAReq1RSPACtrl "RSPA control";
CM_ SG_ 320 PasEntryEnaReq1 "Request locking to enable passive entry function";
CM_ SG_ 320 RemHvStrtActvReq "remote High volage power start request for remote real time video function";
CM_ SG_ 928 CarSharingMde "Car sharing mode";
CM_ SG_ 928 MobDevBtnPanicReq "Panic  alarm  active request on the Mobile Device ";
CM_ SG_ 928 PhoneForgottenRmnBNCM2 "remind user that the mobile phone was forgotten";
CM_ SG_ 928 TelmBookChrgnTyp "Telm Book Chrgn Type from HIM or APP";
CM_ SG_ 928 WPCChrgnStsFrntLeWPC4 "WPCChrgnStsFrntLeWPC4";
CM_ SG_ 928 WPCChrgnStsFrntRiWPC4 "WPCChrgnStsFrntRiWPC4";
CM_ SG_ 928 WPCCtrlResFrntLeWPC4 "WPCCtrlResFrntLeWPC4";
CM_ SG_ 928 WPCCtrlResFrntRiWPC4 "WPCCtrlResFrntRiWPC4";
CM_ SG_ 928 WPCFailureStsFrntLeWPC4 "WPCFailureStsFrntLeWPC4";
CM_ SG_ 928 WPCFailureStsFrntRiWPC4 "WPCFailureStsFrntRiWPC4";
CM_ SG_ 928 WPCModuleStsBNCM2 "WPC charging status and exception status";
CM_ SG_ 928 WPCModuleStsFrntLeWPC4 "WPCModuleStsFrntLeWPC4";
CM_ SG_ 928 WPCModuleStsFrntRiWPC4 "WPCModuleStsFrntRiWPC4";
CM_ SG_ 848 BLEKeyBattLoSts "BLE/UWB key fob battery low energy status";
CM_ SG_ 848 PhoneForgottenRmnFrntLeWPC4 "PhoneForgottenRmnFrntLeWPC4";
CM_ SG_ 848 PhoneForgottenRmnFrntRiWPC4 "PhoneForgottenRmnFrntRiWPC4";
CM_ SG_ 848 RemVSTDCtrlReq "Remote VSTD on/off control request";
CM_ SG_ 736 BleConSts "After the BLE module and mobile phone verification is completed, the BLE module provides Bluetooth connection status.";
CM_ SG_ 736 CalltypeAndStsCallType "call type";
CM_ SG_ 736 CalltypeAndStsEcallStatus "ecall status";
CM_ SG_ 736 CarLocatorActvSts "car locator actived status ";
CM_ SG_ 736 NetTCAMActvt "It describes which state managers that are member of each resource group.";
CM_ SG_ 736 TelmPrkgCameraReq "the setting request for taking picture when parking switch";
CM_ SG_ 736 UsgModChgReqFromUWB "Request UsgMod change to inactive from abandon for UWB key";
CM_ SG_ 416 PrkgCmftModTiCtrlReq "remote parking mode time control request from mobile APP";
CM_ SG_ 416 RemRemoveStrangerPassWordReq "Remote remove the pass word for stranger on HMI";
CM_ SG_ 416 RemStrtExtnTiReq "remote start high voltage extend time request";
CM_ SG_ 416 RemStrtHvCtrlReqErsCmd "remote start high voltage control request";
CM_ SG_ 416 RemStrtHvCtrlReqErsRunTime "remote start high voltage control time";
CM_ SG_ 416 TcamResetResp "TCAM response the reset request";
CM_ SG_ 416 TelmExtrLiFileDeleteReqID "External light show ID";
CM_ SG_ 416 TelmExtrLiFileDeleteReqNoReqOnOff "External light show delete File request
";
CM_ SG_ 416 TelmExtrLiFileDownloadReqID "External light show ID";
CM_ SG_ 416 TelmExtrLiFileDownloadReqNoReqOnOff "External light show File download request
";
CM_ SG_ 416 TelmExtrLiShowReqID "External light show ID";
CM_ SG_ 416 TelmExtrLiShowReqNoReqOnOff "External light show display request";
CM_ SG_ 416 TelmStrangePassWordSetNo1 "the first byte of remote stranger pass word setting ";
CM_ SG_ 416 TelmStrangePassWordSetNo2 "the second byte of remote stranger pass word setting ";
CM_ SG_ 416 TelmStrangePassWordSetNo3 "the third byte of remote stranger pass word setting ";
CM_ SG_ 416 TelmStrangePassWordSetNo4 "the fourth byte of remote stranger pass word setting ";
CM_ SG_ 416 TelmStrangerModStopCtrlReq "Stranger mode control request signal from Telematics";
CM_ SG_ 544 BiasedPosnFromSatlt1Cntr "counter";
CM_ SG_ 544 BiasedPosnFromSatlt1PosnLat "Latitude";
CM_ SG_ 544 BiasedPosnFromSatlt1PosnLgt "Longitude";
CM_ SG_ 544 GNSSSolution1Cntr "Counter";
CM_ SG_ 544 GNSSSolution1NoOfSatItForSysNo1 "Number of GPS satellites used for positioning";
CM_ SG_ 544 GNSSSolution1NoOfSatItForSysNo2 "Number of GLONASS satellites used for positioning";
CM_ SG_ 544 GNSSSolution1NoOfSatItForSysNo3 "Number of Galileo satellites used for positioning";
CM_ SG_ 544 GNSSSolution1NoOfSatItForSysNo4 "Number of SBAS satellites used for positioning";
CM_ SG_ 544 GNSSSolution1NoOfSatItForSysNo5 "Number of QZSS L1 satellites used for positioning";
CM_ SG_ 544 GNSSSolution1NoOfSatItForSysNo6 "Number of QZSS L1-SAIF satellites used for positioning";
CM_ SG_ 544 GNSSSolution1NoOfSatItForSysNo7 "Number of BeiDou satellites used for positioning";
CM_ SG_ 544 GNSSSolution1SatItSysNo1InUse "GPS used for positioning";
CM_ SG_ 544 GNSSSolution1SatItSysNo2InUse "GLONASS used for positioning";
CM_ SG_ 544 GNSSSolution1SatItSysNo3InUse "Galileo used for positioning";
CM_ SG_ 544 GNSSSolution1SatItSysNo4InUse "SBAS used for positioning";
CM_ SG_ 544 GNSSSolution1SatItSysNo5InUse "QZSS L1 used for positioning";
CM_ SG_ 544 GNSSSolution1SatItSysNo6InUse "QZSS L1-SAIF used for positioning";
CM_ SG_ 544 GNSSSolution1SatItSysNo7InUse "BeiDou used for positioning";
CM_ SG_ 544 GNSSSolution1SatltPosnStsPrm1 "Navigation solution status";
CM_ SG_ 544 GNSSSolution1SatltPosnStsPrm2 "DGPS usage in solution";
CM_ SG_ 544 GNSSSolution2Cntr "Counter ";
CM_ SG_ 544 GNSSSolution2PreHozlDil "Horizontal Dilution Of Precision";
CM_ SG_ 544 GNSSSolution2PrePosnDil "Position Dilution Of Precision";
CM_ SG_ 544 GNSSSolution2PreVertDil "Vertical Dilution Of Precision";
CM_ SG_ 544 ImobVehRemReqAndRespImobVehDataRemReq0 "RVI request from TEM to CEM, 5 bytes of response and timer value. Byte nummer 0";
CM_ SG_ 544 ImobVehRemReqAndRespImobVehDataRemReq1 "RVI request from TEM to CEM, 5 bytes of response and timer value. Byte nummer 1";
CM_ SG_ 544 ImobVehRemReqAndRespImobVehDataRemReq2 "RVI request from TEM to CEM, 5 bytes of response and timer value. Byte nummer 2";
CM_ SG_ 544 ImobVehRemReqAndRespImobVehDataRemReq3 "RVI request from TEM to CEM, 5 bytes of response and timer value. Byte nummer 3";
CM_ SG_ 544 ImobVehRemReqAndRespImobVehDataRemReq4 "RVI request from TEM to CEM, 5 bytes of response and timer value. Byte nummer 4";
CM_ SG_ 544 ImobVehRemReqAndRespImobVehRemReqCmd "RVI request from TEM to CEM, 5 bytes of response and timer value. Request from TEM";
CM_ SG_ 544 ImobVehRemReqAndRespImobVehRemTmrOrSpdLim "RVI request from TEM to CEM, 5 bytes of response and timer value. Time or Speed Limit";
CM_ SG_ 544 LowrReAxle "Lower rear axle request";
CM_ SG_ 544 MobDevDistSts1 "MobDevDistSts - Key Distance status";
CM_ SG_ 544 MobDevRCVReq1Chks "Checksum calculation for E2E";
CM_ SG_ 544 MobDevRCVReq1Cntr "E2E counter";
CM_ SG_ 544 MobDevRCVReq1MobDevSts "Mobile device status";
CM_ SG_ 544 MobDevRCVReq1RCVCtrl "RCV request";
CM_ SG_ 544 MobDevRCVReq1Steertrim "RcvSteeringRequest";
CM_ SG_ 544 PosnFromSatlt1Cntr "Counter ";
CM_ SG_ 544 PosnFromSatlt1PosnLat "Latitude";
CM_ SG_ 544 PosnFromSatlt1PosnLgt "Longitude";
CM_ SG_ 544 PosnFromSatlt2Cntr "counter";
CM_ SG_ 544 PosnFromSatlt2PosnSpdosn "Speed";
CM_ SG_ 544 PosnFromSatlt3Cntr "counter";
CM_ SG_ 544 PosnFromSatlt3PosnAlti "Altitide from mean sea level";
CM_ SG_ 544 PosnFromSatlt3PosnDir "Heading from true north";
CM_ SG_ 544 PosnFromSatlt3TiForMins "minute";
CM_ SG_ 544 PosnFromSatlt3TiForMsec "milliseconds";
CM_ SG_ 544 PosnFromSatlt3TiForSec "second";
CM_ SG_ 544 UWBKeyDistrictStsKey0 "UWB key district status";
CM_ SG_ 544 UWBKeyDistrictStsKey1 "UWB key district status";
CM_ SG_ 544 UWBKeyDistrictStsKey2 "UWB key district status";
CM_ SG_ 544 UWBKeyDistrictStsKey3 "UWB key district status";
CM_ SG_ 80 SpdLimdSts "the shared key speed limited status";
CM_ SG_ 337 TripResetSyncReqMsgTCAM "TripResetSyncReqMsg";
CM_ SG_ 1353 VFCVectorTCAMBlockID "BlockID";
CM_ SG_ 1353 VFCVectorTCAMVFCid0 "SettingsComfort";
CM_ SG_ 1353 VFCVectorTCAMVFCid1 "ParkingDrivingClimatization";
CM_ SG_ 1353 VFCVectorTCAMVFCid10 "ExteriorLighting";
CM_ SG_ 1353 VFCVectorTCAMVFCid11 "VFC11";
CM_ SG_ 1353 VFCVectorTCAMVFCid12 "Alarm";
CM_ SG_ 1353 VFCVectorTCAMVFCid13 "VFC13";
CM_ SG_ 1353 VFCVectorTCAMVFCid14 "InteriorLighting";
CM_ SG_ 1353 VFCVectorTCAMVFCid15 "VFC15";
CM_ SG_ 1353 VFCVectorTCAMVFCid16 "Locking";
CM_ SG_ 1353 VFCVectorTCAMVFCid17 "RemoteKeyFunctionality";
CM_ SG_ 1353 VFCVectorTCAMVFCid18 "PropulsionStart";
CM_ SG_ 1353 VFCVectorTCAMVFCid19 "VFC19";
CM_ SG_ 1353 VFCVectorTCAMVFCid2 "PostClimatisation";
CM_ SG_ 1353 VFCVectorTCAMVFCid20 "VFC20";
CM_ SG_ 1353 VFCVectorTCAMVFCid21 "PowerClosures";
CM_ SG_ 1353 VFCVectorTCAMVFCid22 "VehicleDriving";
CM_ SG_ 1353 VFCVectorTCAMVFCid23 "VFC23";
CM_ SG_ 1353 VFCVectorTCAMVFCid24 "SettingsProfile";
CM_ SG_ 1353 VFCVectorTCAMVFCid25 "SeatComfortFunctions";
CM_ SG_ 1353 VFCVectorTCAMVFCid26 "Brake";
CM_ SG_ 1353 VFCVectorTCAMVFCid27 "InfotainmentPoll";
CM_ SG_ 1353 VFCVectorTCAMVFCid28 "HVEnergyStorage";
CM_ SG_ 1353 VFCVectorTCAMVFCid29 "VFC29";
CM_ SG_ 1353 VFCVectorTCAMVFCid3 "PowertrainParkingClimatization";
CM_ SG_ 1353 VFCVectorTCAMVFCid30 "TelematicsConnectivity";
CM_ SG_ 1353 VFCVectorTCAMVFCid31 "VFC31";
CM_ SG_ 1353 VFCVectorTCAMVFCid32 "VFC32";
CM_ SG_ 1353 VFCVectorTCAMVFCid33 "Diagnostics";
CM_ SG_ 1353 VFCVectorTCAMVFCid34 "VehicleModeManagement";
CM_ SG_ 1353 VFCVectorTCAMVFCid35 "TrailerCaravanFunctions";
CM_ SG_ 1353 VFCVectorTCAMVFCid36 "Immobilizer";
CM_ SG_ 1353 VFCVectorTCAMVFCid37 "Windows";
CM_ SG_ 1353 VFCVectorTCAMVFCid38 "Visibility";
CM_ SG_ 1353 VFCVectorTCAMVFCid39 "VFC39";
CM_ SG_ 1353 VFCVectorTCAMVFCid4 "VFC4";
CM_ SG_ 1353 VFCVectorTCAMVFCid40 "VFC40";
CM_ SG_ 1353 VFCVectorTCAMVFCid41 "InfotainmentPush";
CM_ SG_ 1353 VFCVectorTCAMVFCid42 "ChargingHV";
CM_ SG_ 1353 VFCVectorTCAMVFCid43 "BodyPreClimatisation";
CM_ SG_ 1353 VFCVectorTCAMVFCid44 "Crash";
CM_ SG_ 1353 VFCVectorTCAMVFCid45 "GlobalShortDuration";
CM_ SG_ 1353 VFCVectorTCAMVFCid46 "ExteriorLightsHazard";
CM_ SG_ 1353 VFCVectorTCAMVFCid47 "VFC47";
CM_ SG_ 1353 VFCVectorTCAMVFCid48 "DoorOpenWarning";
CM_ SG_ 1353 VFCVectorTCAMVFCid49 "ChargingLVInit";
CM_ SG_ 1353 VFCVectorTCAMVFCid5 "VFC5";
CM_ SG_ 1353 VFCVectorTCAMVFCid50 "VFC50";
CM_ SG_ 1353 VFCVectorTCAMVFCid51 "VFC51";
CM_ SG_ 1353 VFCVectorTCAMVFCid52 "HVBatteryThermalEventWarning";
CM_ SG_ 1353 VFCVectorTCAMVFCid53 "VisualAssist";
CM_ SG_ 1353 VFCVectorTCAMVFCid54 "PassiveSafety";
CM_ SG_ 1353 VFCVectorTCAMVFCid55 "LifeDetection";
CM_ SG_ 1353 VFCVectorTCAMVFCid56 "BackboneFlexray";
CM_ SG_ 1353 VFCVectorTCAMVFCid57 "Functionmarket";
CM_ SG_ 1353 VFCVectorTCAMVFCid58 "VFC58";
CM_ SG_ 1353 VFCVectorTCAMVFCid59 "VFC59";
CM_ SG_ 1353 VFCVectorTCAMVFCid6 "SettingsVehicle";
CM_ SG_ 1353 VFCVectorTCAMVFCid60 "VFC60";
CM_ SG_ 1353 VFCVectorTCAMVFCid61 "VFC61";
CM_ SG_ 1353 VFCVectorTCAMVFCid7 "VFC7";
CM_ SG_ 1353 VFCVectorTCAMVFCid8 "VFC8";
CM_ SG_ 1353 VFCVectorTCAMVFCid9 "IPWakeup";
CM_ SG_ 1289 WakeUpReasonsforTCAM "WakeUpReasons";
CM_ SG_ 338 DigKeyReqSts "digital key request status to HMI";
BA_DEF_ BO_ "CANFD_BRS" ENUM "0","1";
BA_DEF_ BO_ "GenMsgCycleTime" INT 0 65536;
BA_DEF_ BO_ "GenMsgDelayTime" INT 0 65536;
BA_DEF_ BO_ "GenMsgSendType" ENUM "cyclic", "spontaneous", "not-used", "not-used", "not-used", "cyclicAndSpontaneous", "not-used", "cyclicIfActive", "NoMsgSendType";
BA_DEF_ BO_ "GenMsgStartDelayTime" INT 0 65536;
BA_DEF_ BO_ "VFrameFormat" ENUM "StandardCAN","ExtendedCAN","reserved","J1939PG","reserved","reserved","reserved","reserved","reserved","reserved","reserved","reserved","reserved","reserved","StandardCAN_FD","ExtendedCAN_FD";
BA_DEF_ SG_ "GenSigSendType" ENUM "Cyclic","OnWrite","OnWriteWithRepetition","OnChange","OnChangeWithRepetition","IfActive","IfActiveWithRepetition","NoSigSendType";
BA_DEF_ SG_ "GenSigStartValue" HEX 0 80000000;
BA_DEF_ BO_ "GenMsgILSupport" ENUM "No","Yes";
BA_DEF_ BO_ "NmAsrMessage" ENUM "No","Yes";
BA_DEF_ SG_ "GenSigFuncType" ENUM "NoFunction","n/a","n/a","n/a","n/a","n/a","n/a","n/a","n/a","n/a","n/a","n/a","n/a","n/a","n/a","CHK","CNTR","n/a","n/a","n/a","CNTR_AR_01","CRC_AR_01_BOTH","CRC_AR_01_ALT","CRC_AR_01_LOW","CRC_AR_01_NIBBLE","CNTR_AR_04","CRC_AR_04A","CNTR_AR_05","CRC_AR_05";
BA_DEF_ SG_ "GenSigDataID" STRING;
BA_DEF_ SG_ "SigGroup" STRING;
BA_DEF_DEF_ "CANFD_BRS" "1";
BA_DEF_DEF_ "GenSigStartValue" 0;
BA_DEF_DEF_ "VFrameFormat" "J1939PG";
BA_DEF_DEF_ "GenSigSendType" "NoSigSendType";
BA_DEF_DEF_ "GenMsgCycleTime" 0;
BA_DEF_DEF_ "GenMsgDelayTime" 0;
BA_DEF_DEF_ "GenMsgStartDelayTime" 0;
BA_DEF_DEF_ "GenMsgSendType" "NoMsgSendType";
BA_DEF_DEF_ "GenMsgILSupport" "Yes";
BA_DEF_DEF_ "NmAsrMessage" "No";
BA_DEF_DEF_ "GenSigFuncType" "NoFunction";
BA_DEF_DEF_ "GenSigDataID" "";
BA_DEF_DEF_ "SigGroup" "";

BA_ "GenMsgDelayTime" BO_ 176 10.000;
BA_ "GenMsgSendType" BO_ 176 1;
BA_ "VFrameFormat" BO_ 176 14;

BA_ "GenMsgDelayTime" BO_ 336 30.000;
BA_ "GenMsgSendType" BO_ 336 1;
BA_ "VFrameFormat" BO_ 336 14;

BA_ "GenMsgDelayTime" BO_ 192 10.000;
BA_ "GenMsgSendType" BO_ 192 1;
BA_ "VFrameFormat" BO_ 192 14;

BA_ "GenMsgCycleTime" BO_ 320 30.000;
BA_ "GenMsgSendType" BO_ 320 0;
BA_ "VFrameFormat" BO_ 320 14;

BA_ "GenMsgCycleTime" BO_ 928 250.000;
BA_ "GenMsgSendType" BO_ 928 0;
BA_ "VFrameFormat" BO_ 928 14;

BA_ "GenMsgCycleTime" BO_ 848 150.000;
BA_ "GenMsgSendType" BO_ 848 0;
BA_ "VFrameFormat" BO_ 848 14;

BA_ "GenMsgCycleTime" BO_ 736 100.000;
BA_ "GenMsgSendType" BO_ 736 0;
BA_ "VFrameFormat" BO_ 736 14;

BA_ "GenMsgDelayTime" BO_ 416 40.000;
BA_ "GenMsgSendType" BO_ 416 1;
BA_ "VFrameFormat" BO_ 416 14;

BA_ "GenMsgCycleTime" BO_ 544 60.000;
BA_ "GenMsgSendType" BO_ 544 0;
BA_ "VFrameFormat" BO_ 544 14;

BA_ "GenMsgCycleTime" BO_ 80 10.000;
BA_ "GenMsgSendType" BO_ 80 0;
BA_ "VFrameFormat" BO_ 80 14;

BA_ "GenMsgDelayTime" BO_ 337 50.000;
BA_ "GenMsgSendType" BO_ 337 1;
BA_ "VFrameFormat" BO_ 337 14;

BA_ "GenMsgCycleTime" BO_ 1353 500.000;
BA_ "GenMsgSendType" BO_ 1353 0;
BA_ "VFrameFormat" BO_ 1353 0;

BA_ "GenMsgDelayTime" BO_ 1289 20.000;
BA_ "GenMsgSendType" BO_ 1289 1;
BA_ "VFrameFormat" BO_ 1289 0;

BA_ "GenMsgCycleTime" BO_ 338 50.000;
BA_ "GenMsgSendType" BO_ 338 0;
BA_ "VFrameFormat" BO_ 338 14;

BA_ "GenMsgDelayTime" BO_ 1574 5.000;
BA_ "GenMsgSendType" BO_ 1574 1;
BA_ "VFrameFormat" BO_ 1574 14;
BA_ "GenMsgILSupport" BO_ 1289 0;
BA_ "NmAsrMessage" BO_ 1289 1;
BA_ "GenSigSendType" SG_ 176 ApproachReqData1 1;
BA_ "GenSigSendType" SG_ 176 ApproachReqData10 1;
BA_ "GenSigSendType" SG_ 176 ApproachReqData11 1;
BA_ "GenSigSendType" SG_ 176 ApproachReqData12 1;
BA_ "GenSigSendType" SG_ 176 ApproachReqData13 1;
BA_ "GenSigSendType" SG_ 176 ApproachReqData14 1;
BA_ "GenSigSendType" SG_ 176 ApproachReqData15 1;
BA_ "GenSigSendType" SG_ 176 ApproachReqData16 1;
BA_ "GenSigSendType" SG_ 176 ApproachReqData2 1;
BA_ "GenSigSendType" SG_ 176 ApproachReqData3 1;
BA_ "GenSigSendType" SG_ 176 ApproachReqData4 1;
BA_ "GenSigSendType" SG_ 176 ApproachReqData5 1;
BA_ "GenSigSendType" SG_ 176 ApproachReqData6 1;
BA_ "GenSigSendType" SG_ 176 ApproachReqData7 1;
BA_ "GenSigSendType" SG_ 176 ApproachReqData8 1;
BA_ "GenSigSendType" SG_ 176 ApproachReqData9 1;
BA_ "GenSigSendType" SG_ 848 BLEKeyBattLoSts 0;
BA_ "GenSigSendType" SG_ 176 BLEKeySearchRespData1 1;
BA_ "GenSigSendType" SG_ 176 BLEKeySearchRespData10 1;
BA_ "GenSigSendType" SG_ 176 BLEKeySearchRespData11 1;
BA_ "GenSigSendType" SG_ 176 BLEKeySearchRespData12 1;
BA_ "GenSigSendType" SG_ 176 BLEKeySearchRespData13 1;
BA_ "GenSigSendType" SG_ 176 BLEKeySearchRespData14 1;
BA_ "GenSigSendType" SG_ 176 BLEKeySearchRespData15 1;
BA_ "GenSigSendType" SG_ 176 BLEKeySearchRespData16 1;
BA_ "GenSigSendType" SG_ 176 BLEKeySearchRespData2 1;
BA_ "GenSigSendType" SG_ 176 BLEKeySearchRespData3 1;
BA_ "GenSigSendType" SG_ 176 BLEKeySearchRespData4 1;
BA_ "GenSigSendType" SG_ 176 BLEKeySearchRespData5 1;
BA_ "GenSigSendType" SG_ 176 BLEKeySearchRespData6 1;
BA_ "GenSigSendType" SG_ 176 BLEKeySearchRespData7 1;
BA_ "GenSigSendType" SG_ 176 BLEKeySearchRespData8 1;
BA_ "GenSigSendType" SG_ 176 BLEKeySearchRespData9 1;
BA_ "GenSigSendType" SG_ 336 BattPreHeatgLvl 1;
BA_ "GenSigSendType" SG_ 336 BattPreHeatgTiDif 1;
BA_ "GenSigSendType" SG_ 544 BiasedPosnFromSatlt1Cntr 0;
BA_ "GenSigSendType" SG_ 544 BiasedPosnFromSatlt1PosnLat 0;
BA_ "GenSigStartValue" SG_ 544 BiasedPosnFromSatlt1PosnLat 323999740.8002074;
BA_ "GenSigSendType" SG_ 544 BiasedPosnFromSatlt1PosnLgt 0;
BA_ "GenSigStartValue" SG_ 544 BiasedPosnFromSatlt1PosnLgt 647999481.6004148;
BA_ "GenSigSendType" SG_ 736 BleConSts 0;
BA_ "GenSigSendType" SG_ 336 BookChrgnActvdReq 1;
BA_ "GenSigSendType" SG_ 336 BookStopTiAchieved 1;
BA_ "GenSigSendType" SG_ 336 BookTrvlClimaActvReq 1;
BA_ "GenSigSendType" SG_ 736 CalltypeAndStsCallType 0;
BA_ "GenSigSendType" SG_ 736 CalltypeAndStsEcallStatus 0;
BA_ "GenSigSendType" SG_ 336 CarFindrHornLiReqFromTelm 1;
BA_ "GenSigSendType" SG_ 736 CarLocatorActvSts 0;
BA_ "GenSigSendType" SG_ 928 CarSharingMde 0;
BA_ "GenSigSendType" SG_ 336 CbnOverHeatProtnEnaFromTelm 1;
BA_ "GenSigSendType" SG_ 336 ChrgLidTelmLockgReq 1;
BA_ "GenSigSendType" SG_ 336 ChrgnCtrlToEndOrRetartFromApp 1;
BA_ "GenSigSendType" SG_ 336 ClimaRqrd1 1;
BA_ "GenSigSendType" SG_ 336 ClimaTmrStsTelmRqrd 1;
BA_ "GenSigSendType" SG_ 336 CnclBookTrvlReq 1;
BA_ "GenSigSendType" SG_ 192 DKDataFromBLEAcknowledgment 1;
BA_ "GenSigSendType" SG_ 192 DKDataFromBLEDKDataByte1 1;
BA_ "GenSigSendType" SG_ 192 DKDataFromBLEDKDataByte2 1;
BA_ "GenSigSendType" SG_ 192 DKDataFromBLEDKDataByte3 1;
BA_ "GenSigSendType" SG_ 192 DKDataFromBLEDKDataByte4 1;
BA_ "GenSigSendType" SG_ 192 DKDataFromBLEDKDataByte5 1;
BA_ "GenSigSendType" SG_ 192 DKDataFromBLEDKDataByte6 1;
BA_ "GenSigSendType" SG_ 192 DKDataFromBLEHeader 1;
BA_ "GenSigSendType" SG_ 192 DKDataFromTelm1Acknowledgment 1;
BA_ "GenSigSendType" SG_ 192 DKDataFromTelm1DKDataByte1 1;
BA_ "GenSigSendType" SG_ 192 DKDataFromTelm1DKDataByte2 1;
BA_ "GenSigSendType" SG_ 192 DKDataFromTelm1DKDataByte3 1;
BA_ "GenSigSendType" SG_ 192 DKDataFromTelm1DKDataByte4 1;
BA_ "GenSigSendType" SG_ 192 DKDataFromTelm1DKDataByte5 1;
BA_ "GenSigSendType" SG_ 192 DKDataFromTelm1DKDataByte6 1;
BA_ "GenSigSendType" SG_ 192 DKDataFromTelm1Header 1;
BA_ "GenSigSendType" SG_ 336 DKDataFromTelmAcknowledgment 1;
BA_ "GenSigSendType" SG_ 336 DKDataFromTelmDKDataByte1 1;
BA_ "GenSigSendType" SG_ 336 DKDataFromTelmDKDataByte2 1;
BA_ "GenSigSendType" SG_ 336 DKDataFromTelmDKDataByte3 1;
BA_ "GenSigSendType" SG_ 336 DKDataFromTelmDKDataByte4 1;
BA_ "GenSigSendType" SG_ 336 DKDataFromTelmDKDataByte5 1;
BA_ "GenSigSendType" SG_ 336 DKDataFromTelmDKDataByte6 1;
BA_ "GenSigSendType" SG_ 336 DKDataFromTelmHeader 1;
BA_ "GenSigSendType" SG_ 176 DigKeyDataToHMIAcknowledgment 1;
BA_ "GenSigSendType" SG_ 176 DigKeyDataToHMIDKDataByte1 1;
BA_ "GenSigSendType" SG_ 176 DigKeyDataToHMIDKDataByte2 1;
BA_ "GenSigSendType" SG_ 176 DigKeyDataToHMIDKDataByte3 1;
BA_ "GenSigSendType" SG_ 176 DigKeyDataToHMIDKDataByte4 1;
BA_ "GenSigSendType" SG_ 176 DigKeyDataToHMIDKDataByte5 1;
BA_ "GenSigSendType" SG_ 176 DigKeyDataToHMIDKDataByte6 1;
BA_ "GenSigSendType" SG_ 176 DigKeyDataToHMIHeader 1;
BA_ "GenSigSendType" SG_ 336 DigKeyGidInfo1Byte0 1;
BA_ "GenSigStartValue" SG_ 336 DigKeyGidInfo1Byte0 32;
BA_ "GenSigSendType" SG_ 336 DigKeyGidInfo1Byte1 1;
BA_ "GenSigStartValue" SG_ 336 DigKeyGidInfo1Byte1 32;
BA_ "GenSigSendType" SG_ 336 DigKeyGidInfo1Byte2 1;
BA_ "GenSigStartValue" SG_ 336 DigKeyGidInfo1Byte2 32;
BA_ "GenSigSendType" SG_ 336 DigKeyGidInfo1Byte3 1;
BA_ "GenSigStartValue" SG_ 336 DigKeyGidInfo1Byte3 32;
BA_ "GenSigSendType" SG_ 336 DigKeyGidInfo1Byte4 1;
BA_ "GenSigStartValue" SG_ 336 DigKeyGidInfo1Byte4 32;
BA_ "GenSigSendType" SG_ 336 DigKeyGidInfo1Byte5 1;
BA_ "GenSigStartValue" SG_ 336 DigKeyGidInfo1Byte5 32;
BA_ "GenSigSendType" SG_ 336 DigKeyGidInfo1Byte6 1;
BA_ "GenSigStartValue" SG_ 336 DigKeyGidInfo1Byte6 32;
BA_ "GenSigSendType" SG_ 336 DigKeyGidInfo1Byte7 1;
BA_ "GenSigStartValue" SG_ 336 DigKeyGidInfo1Byte7 32;
BA_ "GenSigSendType" SG_ 336 DigKeyGidInfo2Byte0 1;
BA_ "GenSigStartValue" SG_ 336 DigKeyGidInfo2Byte0 32;
BA_ "GenSigSendType" SG_ 336 DigKeyGidInfo2Byte1 1;
BA_ "GenSigStartValue" SG_ 336 DigKeyGidInfo2Byte1 32;
BA_ "GenSigSendType" SG_ 336 DigKeyGidInfo2Byte2 1;
BA_ "GenSigStartValue" SG_ 336 DigKeyGidInfo2Byte2 32;
BA_ "GenSigSendType" SG_ 336 DigKeyGidInfo2Byte3 1;
BA_ "GenSigStartValue" SG_ 336 DigKeyGidInfo2Byte3 32;
BA_ "GenSigSendType" SG_ 336 DigKeyGidInfo2Byte4 1;
BA_ "GenSigStartValue" SG_ 336 DigKeyGidInfo2Byte4 32;
BA_ "GenSigSendType" SG_ 336 DigKeyGidInfo2Byte5 1;
BA_ "GenSigStartValue" SG_ 336 DigKeyGidInfo2Byte5 32;
BA_ "GenSigSendType" SG_ 336 DigKeyGidInfo2Byte6 1;
BA_ "GenSigStartValue" SG_ 336 DigKeyGidInfo2Byte6 32;
BA_ "GenSigSendType" SG_ 336 DigKeyGidInfo2Byte7 1;
BA_ "GenSigStartValue" SG_ 336 DigKeyGidInfo2Byte7 32;
BA_ "GenSigSendType" SG_ 338 DigKeyReqSts 0;
BA_ "GenSigSendType" SG_ 336 EmgyAsscTrigSts 1;
BA_ "GenSigSendType" SG_ 336 EngForbidReqFromTelm 1;
BA_ "GenSigSendType" SG_ 336 EngPermitReqFromTelm 1;
BA_ "GenSigSendType" SG_ 336 ErsCmdRecErsCmd 1;
BA_ "GenSigSendType" SG_ 336 ErsCmdRecErsRunTime 1;
BA_ "GenSigSendType" SG_ 544 GNSSSolution1Cntr 0;
BA_ "GenSigSendType" SG_ 544 GNSSSolution1NoOfSatItForSysNo1 0;
BA_ "GenSigSendType" SG_ 544 GNSSSolution1NoOfSatItForSysNo2 0;
BA_ "GenSigSendType" SG_ 544 GNSSSolution1NoOfSatItForSysNo3 0;
BA_ "GenSigSendType" SG_ 544 GNSSSolution1NoOfSatItForSysNo4 0;
BA_ "GenSigSendType" SG_ 544 GNSSSolution1NoOfSatItForSysNo5 0;
BA_ "GenSigSendType" SG_ 544 GNSSSolution1NoOfSatItForSysNo6 0;
BA_ "GenSigSendType" SG_ 544 GNSSSolution1NoOfSatItForSysNo7 0;
BA_ "GenSigSendType" SG_ 544 GNSSSolution1SatItSysNo1InUse 0;
BA_ "GenSigSendType" SG_ 544 GNSSSolution1SatItSysNo2InUse 0;
BA_ "GenSigSendType" SG_ 544 GNSSSolution1SatItSysNo3InUse 0;
BA_ "GenSigSendType" SG_ 544 GNSSSolution1SatItSysNo4InUse 0;
BA_ "GenSigSendType" SG_ 544 GNSSSolution1SatItSysNo5InUse 0;
BA_ "GenSigSendType" SG_ 544 GNSSSolution1SatItSysNo6InUse 0;
BA_ "GenSigSendType" SG_ 544 GNSSSolution1SatItSysNo7InUse 0;
BA_ "GenSigSendType" SG_ 544 GNSSSolution1SatltPosnStsPrm1 0;
BA_ "GenSigSendType" SG_ 544 GNSSSolution1SatltPosnStsPrm2 0;
BA_ "GenSigSendType" SG_ 544 GNSSSolution2Cntr 0;
BA_ "GenSigSendType" SG_ 544 GNSSSolution2PreHozlDil 0;
BA_ "GenSigSendType" SG_ 544 GNSSSolution2PrePosnDil 0;
BA_ "GenSigSendType" SG_ 544 GNSSSolution2PreVertDil 0;
BA_ "GenSigDataID" SG_ 320 GuestrSts1Chks "0x1F5E";
BA_ "GenSigFuncType" SG_ 320 GuestrSts1Chks 15;
BA_ "GenSigSendType" SG_ 320 GuestrSts1Chks 0;
BA_ "GenSigFuncType" SG_ 320 GuestrSts1Cntr 16;
BA_ "GenSigSendType" SG_ 320 GuestrSts1Cntr 0;
BA_ "GenSigSendType" SG_ 320 GuestrSts1Validity 0;
BA_ "GenSigSendType" SG_ 544 ImobVehRemReqAndRespImobVehDataRemReq0 0;
BA_ "GenSigSendType" SG_ 544 ImobVehRemReqAndRespImobVehDataRemReq1 0;
BA_ "GenSigSendType" SG_ 544 ImobVehRemReqAndRespImobVehDataRemReq2 0;
BA_ "GenSigSendType" SG_ 544 ImobVehRemReqAndRespImobVehDataRemReq3 0;
BA_ "GenSigSendType" SG_ 544 ImobVehRemReqAndRespImobVehDataRemReq4 0;
BA_ "GenSigSendType" SG_ 544 ImobVehRemReqAndRespImobVehRemReqCmd 0;
BA_ "GenSigSendType" SG_ 544 ImobVehRemReqAndRespImobVehRemTmrOrSpdLim 0;
BA_ "GenSigSendType" SG_ 320 KickTailgateSig 0;
BA_ "GenSigSendType" SG_ 544 LowrReAxle 0;
BA_ "GenSigSendType" SG_ 336 MemPosnFromTelm 1;
BA_ "GenSigSendType" SG_ 928 MobDevBtnPanicReq 0;
BA_ "GenSigSendType" SG_ 544 MobDevDistSts1 0;
BA_ "GenSigStartValue" SG_ 544 MobDevDistSts1 1023;
BA_ "GenSigSendType" SG_ 544 MobDevRCVReq1Chks 0;
BA_ "GenSigSendType" SG_ 544 MobDevRCVReq1Cntr 0;
BA_ "GenSigSendType" SG_ 544 MobDevRCVReq1MobDevSts 0;
BA_ "GenSigSendType" SG_ 544 MobDevRCVReq1RCVCtrl 0;
BA_ "GenSigSendType" SG_ 544 MobDevRCVReq1Steertrim 0;
BA_ "GenSigSendType" SG_ 320 MobDevRPAAuthResp1Answer 0;
BA_ "GenSigDataID" SG_ 320 MobDevRPAAuthResp1Chks "0x1F5D";
BA_ "GenSigFuncType" SG_ 320 MobDevRPAAuthResp1Chks 15;
BA_ "GenSigSendType" SG_ 320 MobDevRPAAuthResp1Chks 0;
BA_ "GenSigFuncType" SG_ 320 MobDevRPAAuthResp1Cntr 16;
BA_ "GenSigSendType" SG_ 320 MobDevRPAAuthResp1Cntr 0;
BA_ "GenSigSendType" SG_ 320 MobDevRPAAuthResp1X 0;
BA_ "GenSigSendType" SG_ 320 MobDevRPAAuthResp1Y 0;
BA_ "GenSigDataID" SG_ 320 MobDevRPAReq1Chks "0x1F5C";
BA_ "GenSigFuncType" SG_ 320 MobDevRPAReq1Chks 15;
BA_ "GenSigSendType" SG_ 320 MobDevRPAReq1Chks 0;
BA_ "GenSigFuncType" SG_ 320 MobDevRPAReq1Cntr 16;
BA_ "GenSigSendType" SG_ 320 MobDevRPAReq1Cntr 0;
BA_ "GenSigSendType" SG_ 320 MobDevRPAReq1MobDevSts 0;
BA_ "GenSigSendType" SG_ 320 MobDevRPAReq1RPAOutModeSubT 0;
BA_ "GenSigSendType" SG_ 320 MobDevRPAReq1RPAReq 0;
BA_ "GenSigSendType" SG_ 320 MobDevRPAReq1RSPACtrl 0;
BA_ "GenSigSendType" SG_ 176 NFCAndBLEKeyEnaStsData1 1;
BA_ "GenSigSendType" SG_ 176 NFCAndBLEKeyEnaStsData10 1;
BA_ "GenSigSendType" SG_ 176 NFCAndBLEKeyEnaStsData11 1;
BA_ "GenSigSendType" SG_ 176 NFCAndBLEKeyEnaStsData12 1;
BA_ "GenSigSendType" SG_ 176 NFCAndBLEKeyEnaStsData13 1;
BA_ "GenSigSendType" SG_ 176 NFCAndBLEKeyEnaStsData14 1;
BA_ "GenSigSendType" SG_ 176 NFCAndBLEKeyEnaStsData15 1;
BA_ "GenSigSendType" SG_ 176 NFCAndBLEKeyEnaStsData16 1;
BA_ "GenSigSendType" SG_ 176 NFCAndBLEKeyEnaStsData2 1;
BA_ "GenSigSendType" SG_ 176 NFCAndBLEKeyEnaStsData3 1;
BA_ "GenSigSendType" SG_ 176 NFCAndBLEKeyEnaStsData4 1;
BA_ "GenSigSendType" SG_ 176 NFCAndBLEKeyEnaStsData5 1;
BA_ "GenSigSendType" SG_ 176 NFCAndBLEKeyEnaStsData6 1;
BA_ "GenSigSendType" SG_ 176 NFCAndBLEKeyEnaStsData7 1;
BA_ "GenSigSendType" SG_ 176 NFCAndBLEKeyEnaStsData8 1;
BA_ "GenSigSendType" SG_ 176 NFCAndBLEKeyEnaStsData9 1;
BA_ "GenSigSendType" SG_ 192 NFCKeySearchRespData1 1;
BA_ "GenSigSendType" SG_ 192 NFCKeySearchRespData10 1;
BA_ "GenSigSendType" SG_ 192 NFCKeySearchRespData11 1;
BA_ "GenSigSendType" SG_ 192 NFCKeySearchRespData12 1;
BA_ "GenSigSendType" SG_ 192 NFCKeySearchRespData13 1;
BA_ "GenSigSendType" SG_ 192 NFCKeySearchRespData14 1;
BA_ "GenSigSendType" SG_ 192 NFCKeySearchRespData15 1;
BA_ "GenSigSendType" SG_ 192 NFCKeySearchRespData16 1;
BA_ "GenSigSendType" SG_ 192 NFCKeySearchRespData2 1;
BA_ "GenSigSendType" SG_ 192 NFCKeySearchRespData3 1;
BA_ "GenSigSendType" SG_ 192 NFCKeySearchRespData4 1;
BA_ "GenSigSendType" SG_ 192 NFCKeySearchRespData5 1;
BA_ "GenSigSendType" SG_ 192 NFCKeySearchRespData6 1;
BA_ "GenSigSendType" SG_ 192 NFCKeySearchRespData7 1;
BA_ "GenSigSendType" SG_ 192 NFCKeySearchRespData8 1;
BA_ "GenSigSendType" SG_ 192 NFCKeySearchRespData9 1;
BA_ "GenSigSendType" SG_ 736 NetTCAMActvt 0;
BA_ "GenSigSendType" SG_ 320 PasEntryEnaReq1 0;
BA_ "GenSigSendType" SG_ 928 PhoneForgottenRmnBNCM2 0;
BA_ "GenSigSendType" SG_ 848 PhoneForgottenRmnFrntLeWPC4 0;
BA_ "GenSigSendType" SG_ 848 PhoneForgottenRmnFrntRiWPC4 0;
BA_ "GenSigSendType" SG_ 544 PosnFromSatlt1Cntr 0;
BA_ "GenSigSendType" SG_ 544 PosnFromSatlt1PosnLat 0;
BA_ "GenSigStartValue" SG_ 544 PosnFromSatlt1PosnLat 323999740.8002074;
BA_ "GenSigSendType" SG_ 544 PosnFromSatlt1PosnLgt 0;
BA_ "GenSigStartValue" SG_ 544 PosnFromSatlt1PosnLgt 647999481.6004148;
BA_ "GenSigSendType" SG_ 544 PosnFromSatlt2Cntr 0;
BA_ "GenSigSendType" SG_ 544 PosnFromSatlt2PosnSpdosn 0;
BA_ "GenSigSendType" SG_ 544 PosnFromSatlt3Cntr 0;
BA_ "GenSigSendType" SG_ 544 PosnFromSatlt3PosnAlti 0;
BA_ "GenSigStartValue" SG_ 544 PosnFromSatlt3PosnAlti 1000;
BA_ "GenSigSendType" SG_ 544 PosnFromSatlt3PosnDir 0;
BA_ "GenSigStartValue" SG_ 544 PosnFromSatlt3PosnDir 100;
BA_ "GenSigSendType" SG_ 544 PosnFromSatlt3TiForMins 0;
BA_ "GenSigSendType" SG_ 544 PosnFromSatlt3TiForMsec 0;
BA_ "GenSigSendType" SG_ 544 PosnFromSatlt3TiForSec 0;
BA_ "GenSigSendType" SG_ 416 PrkgCmftModTiCtrlReq 1;
BA_ "GenSigSendType" SG_ 192 RKEAndNFCReqStsData1 1;
BA_ "GenSigSendType" SG_ 192 RKEAndNFCReqStsData10 1;
BA_ "GenSigSendType" SG_ 192 RKEAndNFCReqStsData11 1;
BA_ "GenSigSendType" SG_ 192 RKEAndNFCReqStsData12 1;
BA_ "GenSigSendType" SG_ 192 RKEAndNFCReqStsData13 1;
BA_ "GenSigSendType" SG_ 192 RKEAndNFCReqStsData14 1;
BA_ "GenSigSendType" SG_ 192 RKEAndNFCReqStsData15 1;
BA_ "GenSigSendType" SG_ 192 RKEAndNFCReqStsData16 1;
BA_ "GenSigSendType" SG_ 192 RKEAndNFCReqStsData2 1;
BA_ "GenSigSendType" SG_ 192 RKEAndNFCReqStsData3 1;
BA_ "GenSigSendType" SG_ 192 RKEAndNFCReqStsData4 1;
BA_ "GenSigSendType" SG_ 192 RKEAndNFCReqStsData5 1;
BA_ "GenSigSendType" SG_ 192 RKEAndNFCReqStsData6 1;
BA_ "GenSigSendType" SG_ 192 RKEAndNFCReqStsData7 1;
BA_ "GenSigSendType" SG_ 192 RKEAndNFCReqStsData8 1;
BA_ "GenSigSendType" SG_ 192 RKEAndNFCReqStsData9 1;
BA_ "GenSigSendType" SG_ 336 RemACChrgLidTelmReq 1;
BA_ "GenSigSendType" SG_ 336 RemBookChrgnTarVal 1;
BA_ "GenSigSendType" SG_ 336 RemChkTInVeh 1;
BA_ "GenSigSendType" SG_ 336 RemDCChrgLidTelmReq 1;
BA_ "GenSigSendType" SG_ 320 RemHvStrtActvReq 0;
BA_ "GenSigSendType" SG_ 416 RemRemoveStrangerPassWordReq 1;
BA_ "GenSigSendType" SG_ 416 RemStrtExtnTiReq 1;
BA_ "GenSigSendType" SG_ 416 RemStrtHvCtrlReqErsCmd 1;
BA_ "GenSigSendType" SG_ 416 RemStrtHvCtrlReqErsRunTime 1;
BA_ "GenSigSendType" SG_ 848 RemVSTDCtrlReq 1;
BA_ "GenSigSendType" SG_ 336 RemVentReq 1;
BA_ "GenSigSendType" SG_ 336 RemsSetDchaTarVal 1;
BA_ "GenSigSendType" SG_ 336 ReqFragLvlTelm 1;
BA_ "GenSigSendType" SG_ 336 SeatHeatDurgClimaEnadFromTelm 1;
BA_ "GenSigSendType" SG_ 80 SpdLimdSts 0;
BA_ "GenSigSendType" SG_ 336 SteerWhlHeatgDurgClimaEnadFromTelm 1;
BA_ "GenSigSendType" SG_ 336 SunRoofAndCurtCmdTelm 1;
BA_ "GenSigSendType" SG_ 336 TankFlapTelmLockgReq 1;
BA_ "GenSigSendType" SG_ 416 TcamResetResp 1;
BA_ "GenSigSendType" SG_ 336 TelmAirFragTasteReq 1;
BA_ "GenSigSendType" SG_ 336 TelmBookChrgnReq 1;
BA_ "GenSigSendType" SG_ 928 TelmBookChrgnTyp 0;
BA_ "GenSigSendType" SG_ 336 TelmBookClimaReqHmiCmptmtTSpSpcl 1;
BA_ "GenSigSendType" SG_ 336 TelmBookClimaReqOnOffNoReq 1;
BA_ "GenSigSendType" SG_ 336 TelmBookClimaReqTempRange 1;
BA_ "GenSigSendType" SG_ 336 TelmBookClimaTmr 1;
BA_ "GenSigSendType" SG_ 336 TelmBookSeatHeatClimalReqDrvHeatClimaLvl 1;
BA_ "GenSigSendType" SG_ 336 TelmBookSeatHeatClimalReqPassHeatClimaLvl 1;
BA_ "GenSigSendType" SG_ 336 TelmBookSeatHeatClimalReqSecLeHeatClimaLvl 1;
BA_ "GenSigSendType" SG_ 336 TelmBookSeatHeatClimalReqSecRiHeatClimaLvl 1;
BA_ "GenSigSendType" SG_ 336 TelmBookSeatHeatClimalReqThrdLeHeatClimaLvl 1;
BA_ "GenSigSendType" SG_ 336 TelmBookSeatHeatClimalReqThrdRiHeatClimaLvl 1;
BA_ "GenSigSendType" SG_ 336 TelmBookSeatVentnClimalReqDrvVentnClimaLvl 1;
BA_ "GenSigSendType" SG_ 336 TelmBookSeatVentnClimalReqPassVentnClimaLvl 1;
BA_ "GenSigSendType" SG_ 336 TelmBookSeatVentnClimalReqSecLeVentnClimaLvl 1;
BA_ "GenSigSendType" SG_ 336 TelmBookSeatVentnClimalReqSecRiVentnClimaLvl 1;
BA_ "GenSigSendType" SG_ 336 TelmBookSeatVentnClimalReqThrdLeVentnClimaLvl 1;
BA_ "GenSigSendType" SG_ 336 TelmBookSeatVentnClimalReqThrdRiVentnClimaL 1;
BA_ "GenSigSendType" SG_ 336 TelmBookSteerWhlHeatClimalReq 1;
BA_ "GenSigSendType" SG_ 336 TelmClimaReq 1;
BA_ "GenSigSendType" SG_ 336 TelmClimaTSetHmiCmptmtTSpSpcl 1;
BA_ "GenSigSendType" SG_ 336 TelmClimaTSetTempRange 1;
BA_ "GenSigSendType" SG_ 336 TelmClimaTmr 1;
BA_ "GenSigSendType" SG_ 336 TelmDefrostReq 1;
BA_ "GenSigSendType" SG_ 336 TelmEngDelayTi 1;
BA_ "GenSigSendType" SG_ 416 TelmExtrLiFileDeleteReqID 1;
BA_ "GenSigSendType" SG_ 416 TelmExtrLiFileDeleteReqNoReqOnOff 1;
BA_ "GenSigSendType" SG_ 416 TelmExtrLiFileDownloadReqID 1;
BA_ "GenSigSendType" SG_ 416 TelmExtrLiFileDownloadReqNoReqOnOff 1;
BA_ "GenSigSendType" SG_ 416 TelmExtrLiShowReqID 1;
BA_ "GenSigSendType" SG_ 416 TelmExtrLiShowReqNoReqOnOff 1;
BA_ "GenSigSendType" SG_ 336 TelmFctReq 1;
BA_ "GenSigSendType" SG_ 336 TelmLockgCenReqReqTyp 1;
BA_ "GenSigSendType" SG_ 336 TelmLockgCenReqTiVld 1;
BA_ "GenSigSendType" SG_ 336 TelmPM25Req 1;
BA_ "GenSigSendType" SG_ 336 TelmPreClimaPrio 1;
BA_ "GenSigStartValue" SG_ 336 TelmPreClimaPrio 2;
BA_ "GenSigSendType" SG_ 736 TelmPrkgCameraReq 1;
BA_ "GenSigSendType" SG_ 336 TelmSeatDrvHeatClimaLvl 1;
BA_ "GenSigSendType" SG_ 336 TelmSeatDrvVentnClimaLvl 1;
BA_ "GenSigSendType" SG_ 336 TelmSeatPassHeatClimaLvl 1;
BA_ "GenSigSendType" SG_ 336 TelmSeatPassVentnClimaLvl 1;
BA_ "GenSigSendType" SG_ 336 TelmSeatSecLeHeatClimaLvl 1;
BA_ "GenSigSendType" SG_ 336 TelmSeatSecLeVentnClimaLvl 1;
BA_ "GenSigSendType" SG_ 336 TelmSeatSecRiHeatClimaLvl 1;
BA_ "GenSigSendType" SG_ 336 TelmSeatSecRiVentnClimaLvl 1;
BA_ "GenSigSendType" SG_ 336 TelmSeatThrdLeHeatClimaLvl 1;
BA_ "GenSigSendType" SG_ 336 TelmSeatThrdLeVentnClimaLvl 1;
BA_ "GenSigSendType" SG_ 336 TelmSeatThrdRiHeatClimaLvl 1;
BA_ "GenSigSendType" SG_ 336 TelmSeatThrdRiVentnClimaLvl 1;
BA_ "GenSigSendType" SG_ 416 TelmStrangePassWordSetNo1 1;
BA_ "GenSigSendType" SG_ 416 TelmStrangePassWordSetNo2 1;
BA_ "GenSigSendType" SG_ 416 TelmStrangePassWordSetNo3 1;
BA_ "GenSigSendType" SG_ 416 TelmStrangePassWordSetNo4 1;
BA_ "GenSigSendType" SG_ 416 TelmStrangerModStopCtrlReq 1;
BA_ "GenSigSendType" SG_ 336 TelmStrtEngForChrgnReq 1;
BA_ "GenSigSendType" SG_ 336 TelmThermoTankReq1 1;
BA_ "GenSigSendType" SG_ 336 TelmThermoTankT 1;
BA_ "GenSigStartValue" SG_ 336 TelmThermoTankT 50;
BA_ "GenSigSendType" SG_ 336 TelmThermoTankTmr1 1;
BA_ "GenSigSendType" SG_ 337 TripResetSyncReqMsgTCAM 1;
BA_ "GenSigSendType" SG_ 544 UWBKeyDistrictStsKey0 0;
BA_ "GenSigSendType" SG_ 544 UWBKeyDistrictStsKey1 0;
BA_ "GenSigSendType" SG_ 544 UWBKeyDistrictStsKey2 0;
BA_ "GenSigSendType" SG_ 544 UWBKeyDistrictStsKey3 0;
BA_ "GenSigSendType" SG_ 336 UnlockAndLogInAccountReq 1;
BA_ "GenSigSendType" SG_ 736 UsgModChgReqFromUWB 0;
BA_ "GenSigSendType" SG_ 1353 VFCVectorTCAMBlockID 0;
BA_ "GenSigSendType" SG_ 1353 VFCVectorTCAMVFCid0 0;
BA_ "GenSigSendType" SG_ 1353 VFCVectorTCAMVFCid1 0;
BA_ "GenSigSendType" SG_ 1353 VFCVectorTCAMVFCid10 0;
BA_ "GenSigSendType" SG_ 1353 VFCVectorTCAMVFCid11 0;
BA_ "GenSigSendType" SG_ 1353 VFCVectorTCAMVFCid12 0;
BA_ "GenSigSendType" SG_ 1353 VFCVectorTCAMVFCid13 0;
BA_ "GenSigSendType" SG_ 1353 VFCVectorTCAMVFCid14 0;
BA_ "GenSigSendType" SG_ 1353 VFCVectorTCAMVFCid15 0;
BA_ "GenSigSendType" SG_ 1353 VFCVectorTCAMVFCid16 0;
BA_ "GenSigSendType" SG_ 1353 VFCVectorTCAMVFCid17 0;
BA_ "GenSigSendType" SG_ 1353 VFCVectorTCAMVFCid18 0;
BA_ "GenSigSendType" SG_ 1353 VFCVectorTCAMVFCid19 0;
BA_ "GenSigSendType" SG_ 1353 VFCVectorTCAMVFCid2 0;
BA_ "GenSigSendType" SG_ 1353 VFCVectorTCAMVFCid20 0;
BA_ "GenSigSendType" SG_ 1353 VFCVectorTCAMVFCid21 0;
BA_ "GenSigSendType" SG_ 1353 VFCVectorTCAMVFCid22 0;
BA_ "GenSigSendType" SG_ 1353 VFCVectorTCAMVFCid23 0;
BA_ "GenSigSendType" SG_ 1353 VFCVectorTCAMVFCid24 0;
BA_ "GenSigSendType" SG_ 1353 VFCVectorTCAMVFCid25 0;
BA_ "GenSigSendType" SG_ 1353 VFCVectorTCAMVFCid26 0;
BA_ "GenSigSendType" SG_ 1353 VFCVectorTCAMVFCid27 0;
BA_ "GenSigSendType" SG_ 1353 VFCVectorTCAMVFCid28 0;
BA_ "GenSigSendType" SG_ 1353 VFCVectorTCAMVFCid29 0;
BA_ "GenSigSendType" SG_ 1353 VFCVectorTCAMVFCid3 0;
BA_ "GenSigSendType" SG_ 1353 VFCVectorTCAMVFCid30 0;
BA_ "GenSigSendType" SG_ 1353 VFCVectorTCAMVFCid31 0;
BA_ "GenSigSendType" SG_ 1353 VFCVectorTCAMVFCid32 0;
BA_ "GenSigSendType" SG_ 1353 VFCVectorTCAMVFCid33 0;
BA_ "GenSigSendType" SG_ 1353 VFCVectorTCAMVFCid34 0;
BA_ "GenSigSendType" SG_ 1353 VFCVectorTCAMVFCid35 0;
BA_ "GenSigSendType" SG_ 1353 VFCVectorTCAMVFCid36 0;
BA_ "GenSigSendType" SG_ 1353 VFCVectorTCAMVFCid37 0;
BA_ "GenSigSendType" SG_ 1353 VFCVectorTCAMVFCid38 0;
BA_ "GenSigSendType" SG_ 1353 VFCVectorTCAMVFCid39 0;
BA_ "GenSigSendType" SG_ 1353 VFCVectorTCAMVFCid4 0;
BA_ "GenSigSendType" SG_ 1353 VFCVectorTCAMVFCid40 0;
BA_ "GenSigSendType" SG_ 1353 VFCVectorTCAMVFCid41 0;
BA_ "GenSigSendType" SG_ 1353 VFCVectorTCAMVFCid42 0;
BA_ "GenSigSendType" SG_ 1353 VFCVectorTCAMVFCid43 0;
BA_ "GenSigSendType" SG_ 1353 VFCVectorTCAMVFCid44 0;
BA_ "GenSigSendType" SG_ 1353 VFCVectorTCAMVFCid45 0;
BA_ "GenSigSendType" SG_ 1353 VFCVectorTCAMVFCid46 0;
BA_ "GenSigSendType" SG_ 1353 VFCVectorTCAMVFCid47 0;
BA_ "GenSigSendType" SG_ 1353 VFCVectorTCAMVFCid48 0;
BA_ "GenSigSendType" SG_ 1353 VFCVectorTCAMVFCid49 0;
BA_ "GenSigSendType" SG_ 1353 VFCVectorTCAMVFCid5 0;
BA_ "GenSigSendType" SG_ 1353 VFCVectorTCAMVFCid50 0;
BA_ "GenSigSendType" SG_ 1353 VFCVectorTCAMVFCid51 0;
BA_ "GenSigSendType" SG_ 1353 VFCVectorTCAMVFCid52 0;
BA_ "GenSigSendType" SG_ 1353 VFCVectorTCAMVFCid53 0;
BA_ "GenSigSendType" SG_ 1353 VFCVectorTCAMVFCid54 0;
BA_ "GenSigSendType" SG_ 1353 VFCVectorTCAMVFCid55 0;
BA_ "GenSigSendType" SG_ 1353 VFCVectorTCAMVFCid56 0;
BA_ "GenSigSendType" SG_ 1353 VFCVectorTCAMVFCid57 0;
BA_ "GenSigSendType" SG_ 1353 VFCVectorTCAMVFCid58 0;
BA_ "GenSigSendType" SG_ 1353 VFCVectorTCAMVFCid59 0;
BA_ "GenSigSendType" SG_ 1353 VFCVectorTCAMVFCid6 0;
BA_ "GenSigSendType" SG_ 1353 VFCVectorTCAMVFCid60 0;
BA_ "GenSigSendType" SG_ 1353 VFCVectorTCAMVFCid61 0;
BA_ "GenSigSendType" SG_ 1353 VFCVectorTCAMVFCid7 0;
BA_ "GenSigSendType" SG_ 1353 VFCVectorTCAMVFCid8 0;
BA_ "GenSigSendType" SG_ 1353 VFCVectorTCAMVFCid9 0;
BA_ "GenSigSendType" SG_ 928 WPCChrgnStsFrntLeWPC4 0;
BA_ "GenSigSendType" SG_ 928 WPCChrgnStsFrntRiWPC4 0;
BA_ "GenSigSendType" SG_ 928 WPCCtrlResFrntLeWPC4 0;
BA_ "GenSigSendType" SG_ 928 WPCCtrlResFrntRiWPC4 0;
BA_ "GenSigSendType" SG_ 928 WPCFailureStsFrntLeWPC4 0;
BA_ "GenSigSendType" SG_ 928 WPCFailureStsFrntRiWPC4 0;
BA_ "GenSigSendType" SG_ 928 WPCModuleStsBNCM2 0;
BA_ "GenSigStartValue" SG_ 928 WPCModuleStsBNCM2 1;
BA_ "GenSigSendType" SG_ 928 WPCModuleStsFrntLeWPC4 0;
BA_ "GenSigStartValue" SG_ 928 WPCModuleStsFrntLeWPC4 1;
BA_ "GenSigSendType" SG_ 928 WPCModuleStsFrntRiWPC4 0;
BA_ "GenSigStartValue" SG_ 928 WPCModuleStsFrntRiWPC4 1;
BA_ "GenSigSendType" SG_ 1289 WakeUpReasonsforTCAM 0;
BA_ "GenSigSendType" SG_ 336 WinOpenClsGlbReqFromTelmWinOpenClsGlbSts 1;
BA_ "GenSigSendType" SG_ 336 WinOpenClsGlbReqFromTelmWindowOpenValue 1;
VAL_ 336 BattPreHeatgLvl 0 "ModeLvl_Default" 1 "ModeLvl_Econ" 2 "ModeLvl_Sport" 3 "ModeLvl_Reserved";
VAL_ 336 BookChrgnActvdReq 0 "Boolean_FALSE" 1 "Boolean_TRUE";
VAL_ 336 BookStopTiAchieved 0 "Boolean_FALSE" 1 "Boolean_TRUE";
VAL_ 336 BookTrvlClimaActvReq 0 "OnOffNoReq_NoReq" 1 "OnOffNoReq_On" 2 "OnOffNoReq_Off";
VAL_ 336 CarFindrHornLiReqFromTelm 0 "CarFindrHornLiReqFromTelm_NoReq" 1 "CarFindrHornLiReqFromTelm_HornReq" 2 "CarFindrHornLiReqFromTelm_LiReq" 3 "CarFindrHornLiReqFromTelm_HornLiReq";
VAL_ 336 CbnOverHeatProtnEnaFromTelm 0 "OnOff1_Off" 1 "OnOff1_On";
VAL_ 336 ChrgLidTelmLockgReq 0 "ReqSts1_NotReqd" 1 "ReqSts1_Reqd";
VAL_ 336 ChrgnCtrlToEndOrRetartFromApp 0 "OnOffNoReq_NoReq" 1 "OnOffNoReq_On" 2 "OnOffNoReq_Off";
VAL_ 336 ClimaRqrd1 0 "OnOffNoReq_NoReq" 1 "OnOffNoReq_On" 2 "OnOffNoReq_Off";
VAL_ 336 ClimaTmrStsTelmRqrd 0 "OnOff1_Off" 1 "OnOff1_On";
VAL_ 336 CnclBookTrvlReq 0 "ReqSts1_NotReqd" 1 "ReqSts1_Reqd";
VAL_ 336 EmgyAsscTrigSts 0 "AfsStsReq_Inactive" 1 "AfsStsReq_AutomaticallySet" 2 "AfsStsReq_ManuallySet" 3 "AfsStsReq_Fault";
VAL_ 336 EngForbidReqFromTelm 0 "ReqSts1_NotReqd" 1 "ReqSts1_Reqd";
VAL_ 336 EngPermitReqFromTelm 0 "ReqSts1_NotReqd" 1 "ReqSts1_Reqd";
VAL_ 336 ErsCmdRecErsCmd 0 "ErsCmd_ErsCmdNotSet" 1 "ErsCmd_ErsCmdOn" 2 "ErsCmd_ErsCmdOff";
VAL_ 336 MemPosnFromTelm 0 "MemPosn_ProfPosn" 1 "MemPosn_MemBnk1" 2 "MemPosn_MemBnk2" 3 "MemPosn_MemBnk3";
VAL_ 336 RemACChrgLidTelmReq 0 "OnOffNoReq_NoReq" 1 "OnOffNoReq_On" 2 "OnOffNoReq_Off";
VAL_ 336 RemChkTInVeh 0 "ReqSts1_NotReqd" 1 "ReqSts1_Reqd";
VAL_ 336 RemDCChrgLidTelmReq 0 "OnOffNoReq_NoReq" 1 "OnOffNoReq_On" 2 "OnOffNoReq_Off";
VAL_ 336 RemVentReq 0 "OnOffNoReq_NoReq" 1 "OnOffNoReq_On" 2 "OnOffNoReq_Off";
VAL_ 336 ReqFragLvlTelm 0 "ReqFragLvl_OFF" 1 "ReqFragLvl_Level1" 2 "ReqFragLvl_Level2" 3 "ReqFragLvl_Level3";
VAL_ 336 SeatHeatDurgClimaEnadFromTelm 0 "SeatHeatDurgClimaEnad2_SeatHeatOff" 1 "SeatHeatDurgClimaEnad2_SeatDrvOn" 2 "SeatHeatDurgClimaEnad2_SeatPassOn" 3 "SeatHeatDurgClimaEnad2_SeatDrvrAndPass" 4 "SeatHeatDurgClimaEnad2_SeatLeftRearOn" 5 "SeatHeatDurgClimaEnad2_SeatRightRearOn";
VAL_ 336 SteerWhlHeatgDurgClimaEnadFromTelm 0 "OnOff1_Off" 1 "OnOff1_On";
VAL_ 336 SunRoofAndCurtCmdTelm 0 "SunRoofAndCurtCmdExt_Idle" 1 "SunRoofAndCurtCmdExt_OpenCurtain" 2 "SunRoofAndCurtCmdExt_CloseCurtain" 3 "SunRoofAndCurtCmdExt_OpenPanel" 4 "SunRoofAndCurtCmdExt_ClosePanel" 5 "SunRoofAndCurtCmdExt_OpenManual" 6 "SunRoofAndCurtCmdExt_CloseManual" 7 "SunRoofAndCurtCmdExt_OpenTilt";
VAL_ 336 TankFlapTelmLockgReq 0 "LockActvn2_LockActvnOff" 1 "LockActvn2_LockActvnUnlck" 2 "LockActvn2_LockActvnLock" 3 "LockActvn2_LockActvnSafe" 4 "LockActvn2_LockActvnUnlckByCrash";
VAL_ 336 TelmAirFragTasteReq 0 "TelmAirFragChReq_NoReq" 1 "TelmAirFragChReq_Ch1" 2 "TelmAirFragChReq_Ch2" 3 "TelmAirFragChReq_Ch3" 4 "TelmAirFragChReq_Ch4" 5 "TelmAirFragChReq_Ch5";
VAL_ 336 TelmBookChrgnReq 0 "OnOffNoReq_NoReq" 1 "OnOffNoReq_On" 2 "OnOffNoReq_Off";
VAL_ 336 TelmBookClimaReqHmiCmptmtTSpSpcl 0 "NormalLowHigh_Normal" 1 "NormalLowHigh_Low" 2 "NormalLowHigh_High";
VAL_ 336 TelmBookClimaReqOnOffNoReq 0 "NoReqOnOff_Norequest" 1 "NoReqOnOff_On" 2 "NoReqOnOff_Off";
VAL_ 336 TelmBookSeatHeatClimalReqDrvHeatClimaLvl 0 "TelmSeatClimaLvl_off" 1 "TelmSeatClimaLvl_Lvl1" 2 "TelmSeatClimaLvl_Lvl2" 3 "TelmSeatClimaLvl_Lvl3";
VAL_ 336 TelmBookSeatHeatClimalReqPassHeatClimaLvl 0 "TelmSeatClimaLvl_off" 1 "TelmSeatClimaLvl_Lvl1" 2 "TelmSeatClimaLvl_Lvl2" 3 "TelmSeatClimaLvl_Lvl3";
VAL_ 336 TelmBookSeatHeatClimalReqSecLeHeatClimaLvl 0 "TelmSeatClimaLvl_off" 1 "TelmSeatClimaLvl_Lvl1" 2 "TelmSeatClimaLvl_Lvl2" 3 "TelmSeatClimaLvl_Lvl3";
VAL_ 336 TelmBookSeatHeatClimalReqSecRiHeatClimaLvl 0 "TelmSeatClimaLvl_off" 1 "TelmSeatClimaLvl_Lvl1" 2 "TelmSeatClimaLvl_Lvl2" 3 "TelmSeatClimaLvl_Lvl3";
VAL_ 336 TelmBookSeatHeatClimalReqThrdLeHeatClimaLvl 0 "TelmSeatClimaLvl_off" 1 "TelmSeatClimaLvl_Lvl1" 2 "TelmSeatClimaLvl_Lvl2" 3 "TelmSeatClimaLvl_Lvl3";
VAL_ 336 TelmBookSeatHeatClimalReqThrdRiHeatClimaLvl 0 "TelmSeatClimaLvl_off" 1 "TelmSeatClimaLvl_Lvl1" 2 "TelmSeatClimaLvl_Lvl2" 3 "TelmSeatClimaLvl_Lvl3";
VAL_ 336 TelmBookSeatVentnClimalReqDrvVentnClimaLvl 0 "TelmSeatClimaLvl_off" 1 "TelmSeatClimaLvl_Lvl1" 2 "TelmSeatClimaLvl_Lvl2" 3 "TelmSeatClimaLvl_Lvl3";
VAL_ 336 TelmBookSeatVentnClimalReqPassVentnClimaLvl 0 "TelmSeatClimaLvl_off" 1 "TelmSeatClimaLvl_Lvl1" 2 "TelmSeatClimaLvl_Lvl2" 3 "TelmSeatClimaLvl_Lvl3";
VAL_ 336 TelmBookSeatVentnClimalReqSecLeVentnClimaLvl 0 "TelmSeatClimaLvl_off" 1 "TelmSeatClimaLvl_Lvl1" 2 "TelmSeatClimaLvl_Lvl2" 3 "TelmSeatClimaLvl_Lvl3";
VAL_ 336 TelmBookSeatVentnClimalReqSecRiVentnClimaLvl 0 "TelmSeatClimaLvl_off" 1 "TelmSeatClimaLvl_Lvl1" 2 "TelmSeatClimaLvl_Lvl2" 3 "TelmSeatClimaLvl_Lvl3";
VAL_ 336 TelmBookSeatVentnClimalReqThrdLeVentnClimaLvl 0 "TelmSeatClimaLvl_off" 1 "TelmSeatClimaLvl_Lvl1" 2 "TelmSeatClimaLvl_Lvl2" 3 "TelmSeatClimaLvl_Lvl3";
VAL_ 336 TelmBookSeatVentnClimalReqThrdRiVentnClimaL 0 "TelmSeatClimaLvl_off" 1 "TelmSeatClimaLvl_Lvl1" 2 "TelmSeatClimaLvl_Lvl2" 3 "TelmSeatClimaLvl_Lvl3";
VAL_ 336 TelmBookSteerWhlHeatClimalReq 0 "OnOff1_Off" 1 "OnOff1_On";
VAL_ 336 TelmClimaReq 0 "OnOffNoReq_NoReq" 1 "OnOffNoReq_On" 2 "OnOffNoReq_Off";
VAL_ 336 TelmClimaTSetHmiCmptmtTSpSpcl 0 "HmiCmptmtTSpSpcl_Norm" 1 "HmiCmptmtTSpSpcl_Lo" 2 "HmiCmptmtTSpSpcl_Hi";
VAL_ 336 TelmDefrostReq 0 "OnOffNoReq_NoReq" 1 "OnOffNoReq_On" 2 "OnOffNoReq_Off";
VAL_ 336 TelmFctReq 0 "Boolean_FALSE" 1 "Boolean_TRUE";
VAL_ 336 TelmLockgCenReqReqTyp 0 "TelmLockgCenReq2_TelmNoReq" 1 "TelmLockgCenReq2_TelmLock" 2 "TelmLockgCenReq2_TelmUnlck" 3 "TelmLockgCenReq2_TelmUnlckByTrSwtEna";
VAL_ 336 TelmPM25Req 0 "ReqSts1_NotReqd" 1 "ReqSts1_Reqd";
VAL_ 336 TelmPreClimaPrio 0 "PreClimaPrio_Range" 1 "PreClimaPrio_KeepSOC" 2 "PreClimaPrio_Comfort" 3 "PreClimaPrio_Reserved";
VAL_ 336 TelmSeatDrvHeatClimaLvl 0 "TelmSeatClimaLvl_off" 1 "TelmSeatClimaLvl_Lvl1" 2 "TelmSeatClimaLvl_Lvl2" 3 "TelmSeatClimaLvl_Lvl3";
VAL_ 336 TelmSeatDrvVentnClimaLvl 0 "TelmSeatClimaLvl_off" 1 "TelmSeatClimaLvl_Lvl1" 2 "TelmSeatClimaLvl_Lvl2" 3 "TelmSeatClimaLvl_Lvl3";
VAL_ 336 TelmSeatPassHeatClimaLvl 0 "TelmSeatClimaLvl_off" 1 "TelmSeatClimaLvl_Lvl1" 2 "TelmSeatClimaLvl_Lvl2" 3 "TelmSeatClimaLvl_Lvl3";
VAL_ 336 TelmSeatPassVentnClimaLvl 0 "TelmSeatClimaLvl_off" 1 "TelmSeatClimaLvl_Lvl1" 2 "TelmSeatClimaLvl_Lvl2" 3 "TelmSeatClimaLvl_Lvl3";
VAL_ 336 TelmSeatSecLeHeatClimaLvl 0 "TelmSeatClimaLvl_off" 1 "TelmSeatClimaLvl_Lvl1" 2 "TelmSeatClimaLvl_Lvl2" 3 "TelmSeatClimaLvl_Lvl3";
VAL_ 336 TelmSeatSecLeVentnClimaLvl 0 "TelmSeatClimaLvl_off" 1 "TelmSeatClimaLvl_Lvl1" 2 "TelmSeatClimaLvl_Lvl2" 3 "TelmSeatClimaLvl_Lvl3";
VAL_ 336 TelmSeatSecRiHeatClimaLvl 0 "TelmSeatClimaLvl_off" 1 "TelmSeatClimaLvl_Lvl1" 2 "TelmSeatClimaLvl_Lvl2" 3 "TelmSeatClimaLvl_Lvl3";
VAL_ 336 TelmSeatSecRiVentnClimaLvl 0 "TelmSeatClimaLvl_off" 1 "TelmSeatClimaLvl_Lvl1" 2 "TelmSeatClimaLvl_Lvl2" 3 "TelmSeatClimaLvl_Lvl3";
VAL_ 336 TelmSeatThrdLeHeatClimaLvl 0 "TelmSeatClimaLvl_off" 1 "TelmSeatClimaLvl_Lvl1" 2 "TelmSeatClimaLvl_Lvl2" 3 "TelmSeatClimaLvl_Lvl3";
VAL_ 336 TelmSeatThrdLeVentnClimaLvl 0 "TelmSeatClimaLvl_off" 1 "TelmSeatClimaLvl_Lvl1" 2 "TelmSeatClimaLvl_Lvl2" 3 "TelmSeatClimaLvl_Lvl3";
VAL_ 336 TelmSeatThrdRiHeatClimaLvl 0 "TelmSeatClimaLvl_off" 1 "TelmSeatClimaLvl_Lvl1" 2 "TelmSeatClimaLvl_Lvl2" 3 "TelmSeatClimaLvl_Lvl3";
VAL_ 336 TelmSeatThrdRiVentnClimaLvl 0 "TelmSeatClimaLvl_off" 1 "TelmSeatClimaLvl_Lvl1" 2 "TelmSeatClimaLvl_Lvl2" 3 "TelmSeatClimaLvl_Lvl3";
VAL_ 336 TelmStrtEngForChrgnReq 0 "ErsCmd_ErsCmdNotSet" 1 "ErsCmd_ErsCmdOn" 2 "ErsCmd_ErsCmdOff";
VAL_ 336 TelmThermoTankReq1 0 "Req_NoReq" 1 "Req_off" 2 "Req_Coolg" 3 "Req_Heatlg";
VAL_ 336 UnlockAndLogInAccountReq 0 "OnOffNoReq_NoReq" 1 "OnOffNoReq_On" 2 "OnOffNoReq_Off";
VAL_ 336 WinOpenClsGlbReqFromTelmWinOpenClsGlbSts 0 "WinOpenClsGlbReqFromTelm_Idle" 1 "WinOpenClsGlbReqFromTelm_Open" 2 "WinOpenClsGlbReqFromTelm_Close";
VAL_ 320 GuestrSts1Validity 0 "Validity_NotValid" 1 "Validity_Valid";
VAL_ 320 KickTailgateSig 0 "Boolean_FALSE" 1 "Boolean_TRUE";
VAL_ 320 MobDevRPAReq1RPAOutModeSubT 0 "RPAOutModeSubT_Idle" 1 "RPAOutModeSubT_PrlRiOut" 2 "RPAOutModeSubT_RrlLeOut" 3 "RPAOutModeSubT_HeadPrpndRiOut" 4 "RPAOutModeSubT_HeadPrpndLeOut" 5 "RPAOutModeSubT_TailPrpndRiOut" 6 "RPAOutModeSubT_TailPrpndLeOut" 7 "RPAOutModeSubT_Resd1" 8 "RPAOutModeSubT_Resd2";
VAL_ 320 MobDevRPAReq1RPAReq 0 "RPAReq_Idle" 1 "RPAReq_Start" 2 "RPAReq_Stop" 3 "RPAReq_OutMode" 4 "RPAReq_Undo" 5 "RPAReq_Start_Searching" 6 "RPAReq_Start_Parking_In" 7 "RPAReq_Start_Parking_Out" 8 "RPAReq_Pause" 9 "RPAReq_Continue" 10 "RPAReq_Reserved" 11 "RPAReq_RPA_Park_Out_Req" 12 "RPAReq_Return_To_Previous_Menu" 13 "RPAReq_Clickremoteparkinginbutton" 14 "RPAReq_RemParkOutCrsSwtON" 15 "RPAReq_RemParkOutCrsSwtOFF";
VAL_ 320 MobDevRPAReq1RSPACtrl 0 "RSPACtrl_Idle" 1 "RSPACtrl_Function_On" 2 "RSPACtrl_Backward" 3 "RSPACtrl_Forward" 4 "RSPACtrl_Release_Button" 5 "RSPACtrl_Exit_Function" 6 "RSPACtrl_RSPA_Complete";
VAL_ 320 PasEntryEnaReq1 0 "OnOff1_Off" 1 "OnOff1_On";
VAL_ 320 RemHvStrtActvReq 0 "OnOffNoReq_NoReq" 1 "OnOffNoReq_On" 2 "OnOffNoReq_Off";
VAL_ 928 CarSharingMde 0 "Boolean_FALSE" 1 "Boolean_TRUE";
VAL_ 928 MobDevBtnPanicReq 0 "OnOffNoReq_NoReq" 1 "OnOffNoReq_On" 2 "OnOffNoReq_Off";
VAL_ 928 PhoneForgottenRmnBNCM2 0 "Boolean_FALSE" 1 "Boolean_TRUE";
VAL_ 928 TelmBookChrgnTyp 0 "TelmBookChrgnTyp_Idle" 1 "TelmBookChrgnTyp_Off" 2 "TelmBookChrgnTyp_SingleBooking" 3 "TelmBookChrgnTyp_CyclicBooking" 4 "TelmBookChrgnTyp_PlugInBooking";
VAL_ 928 WPCChrgnStsFrntLeWPC4 0 "WPCChrgnSts_Standby" 1 "WPCChrgnSts_Charging" 2 "WPCChrgnSts_ChargingcompletedAvailedwhenRxsupport" 3 "WPCChrgnSts_Notinstandby";
VAL_ 928 WPCChrgnStsFrntRiWPC4 0 "WPCChrgnSts_Standby" 1 "WPCChrgnSts_Charging" 2 "WPCChrgnSts_ChargingcompletedAvailedwhenRxsupport" 3 "WPCChrgnSts_Notinstandby";
VAL_ 928 WPCCtrlResFrntLeWPC4 0 "WPCCtrlRes_WPCenabled" 1 "WPCCtrlRes_WPCdisabledbyPEPS" 2 "WPCCtrlRes_WPCshutdownbySwitchOrCAN" 3 "WPCCtrlRes_WPCdisabledbyNFC";
VAL_ 928 WPCCtrlResFrntRiWPC4 0 "WPCCtrlRes_WPCenabled" 1 "WPCCtrlRes_WPCdisabledbyPEPS" 2 "WPCCtrlRes_WPCshutdownbySwitchOrCAN" 3 "WPCCtrlRes_WPCdisabledbyNFC";
VAL_ 928 WPCFailureStsFrntLeWPC4 0 "WPCFailureSts_NoFailure" 1 "WPCFailureSts_OverTemperature" 2 "WPCFailureSts_RFOD" 3 "WPCFailureSts_VoltageProtected" 4 "WPCFailureSts_OverPowerProtected" 5 "WPCFailureSts_InternalFailure" 6 "WPCFailureSts_SmartPhoneNoResponseOrUnknown" 7 "WPCFailureSts_OFOD" 8 "WPCFailureSts_Reserved1" 9 "WPCFailureSts_Reserved2" 10 "WPCFailureSts_Reserved3" 11 "WPCFailureSts_Reserved4" 12 "WPCFailureSts_Reserved5" 13 "WPCFailureSts_Reserved6" 14 "WPCFailureSts_Reserved7" 15 "WPCFailureSts_Invalid";
VAL_ 928 WPCFailureStsFrntRiWPC4 0 "WPCFailureSts_NoFailure" 1 "WPCFailureSts_OverTemperature" 2 "WPCFailureSts_RFOD" 3 "WPCFailureSts_VoltageProtected" 4 "WPCFailureSts_OverPowerProtected" 5 "WPCFailureSts_InternalFailure" 6 "WPCFailureSts_SmartPhoneNoResponseOrUnknown" 7 "WPCFailureSts_OFOD" 8 "WPCFailureSts_Reserved1" 9 "WPCFailureSts_Reserved2" 10 "WPCFailureSts_Reserved3" 11 "WPCFailureSts_Reserved4" 12 "WPCFailureSts_Reserved5" 13 "WPCFailureSts_Reserved6" 14 "WPCFailureSts_Reserved7" 15 "WPCFailureSts_Invalid";
VAL_ 928 WPCModuleStsBNCM2 0 "WPCModuleSts_OverTemperatureProtected" 1 "WPCModuleSts_Standby" 2 "WPCModuleSts_Charging" 3 "WPCModuleSts_FOD" 4 "WPCModuleSts_VoltageProtected" 5 "WPCModuleSts_OverPowerProtected" 6 "WPCModuleSts_Transmittingcoildisable" 7 "WPCModuleSts_OFF" 8 "WPCModuleSts_ChargingCompleted" 9 "WPCModuleSts_DeactivatedbyUser" 10 "WPCModuleSts_50WCharging" 11 "WPCModuleSts_Resvd3" 12 "WPCModuleSts_Resvd4" 13 "WPCModuleSts_Resvd5" 14 "WPCModuleSts_Resvd6" 15 "WPCModuleSts_Invalid";
VAL_ 928 WPCModuleStsFrntLeWPC4 0 "WPCModuleSts_OverTemperatureProtected" 1 "WPCModuleSts_Standby" 2 "WPCModuleSts_Charging" 3 "WPCModuleSts_FOD" 4 "WPCModuleSts_VoltageProtected" 5 "WPCModuleSts_OverPowerProtected" 6 "WPCModuleSts_Transmittingcoildisable" 7 "WPCModuleSts_OFF" 8 "WPCModuleSts_ChargingCompleted" 9 "WPCModuleSts_DeactivatedbyUser" 10 "WPCModuleSts_50WCharging" 11 "WPCModuleSts_Resvd3" 12 "WPCModuleSts_Resvd4" 13 "WPCModuleSts_Resvd5" 14 "WPCModuleSts_Resvd6" 15 "WPCModuleSts_Invalid";
VAL_ 928 WPCModuleStsFrntRiWPC4 0 "WPCModuleSts_OverTemperatureProtected" 1 "WPCModuleSts_Standby" 2 "WPCModuleSts_Charging" 3 "WPCModuleSts_FOD" 4 "WPCModuleSts_VoltageProtected" 5 "WPCModuleSts_OverPowerProtected" 6 "WPCModuleSts_Transmittingcoildisable" 7 "WPCModuleSts_OFF" 8 "WPCModuleSts_ChargingCompleted" 9 "WPCModuleSts_DeactivatedbyUser" 10 "WPCModuleSts_50WCharging" 11 "WPCModuleSts_Resvd3" 12 "WPCModuleSts_Resvd4" 13 "WPCModuleSts_Resvd5" 14 "WPCModuleSts_Resvd6" 15 "WPCModuleSts_Invalid";
VAL_ 848 BLEKeyBattLoSts 0 "Boolean_FALSE" 1 "Boolean_TRUE";
VAL_ 848 PhoneForgottenRmnFrntLeWPC4 0 "Boolean_FALSE" 1 "Boolean_TRUE";
VAL_ 848 PhoneForgottenRmnFrntRiWPC4 0 "Boolean_FALSE" 1 "Boolean_TRUE";
VAL_ 848 RemVSTDCtrlReq 0 "OnOffNoReq_NoReq" 1 "OnOffNoReq_On" 2 "OnOffNoReq_Off";
VAL_ 736 BleConSts 0 "Boolean_FALSE" 1 "Boolean_TRUE";
VAL_ 736 CalltypeAndStsCallType 0 "CallType_NoCall" 1 "CallType_ManualEcall" 2 "CallType_AutoEcall" 3 "CallType_BcallOrIcall" 4 "CallType_Reserved1" 5 "CallType_Reserved2" 6 "CallType_Reserved3" 7 "CallType_Reserved4";
VAL_ 736 CalltypeAndStsEcallStatus 0 "EcallStatus_Default" 1 "EcallStatus_Calltart" 2 "EcallStatus_CallConnecting" 3 "EcallStatus_CallDataSenting" 4 "EcallStatus_CallConnected" 5 "EcallStatus_CallEnded" 6 "EcallStatus_IncomingCall" 7 "EcallStatus_CallFailed";
VAL_ 736 CarLocatorActvSts 0 "ActvnAvl3_Idle" 1 "ActvnAvl3_Actvn" 2 "ActvnAvl3_Deactvn";
VAL_ 736 TelmPrkgCameraReq 0 "OnOffNoReq_NoReq" 1 "OnOffNoReq_On" 2 "OnOffNoReq_Off";
VAL_ 736 UsgModChgReqFromUWB 0 "ReqSts1_NotReqd" 1 "ReqSts1_Reqd";
VAL_ 416 PrkgCmftModTiCtrlReq 0 "OnOffNoReq_NoReq" 1 "OnOffNoReq_On" 2 "OnOffNoReq_Off";
VAL_ 416 RemRemoveStrangerPassWordReq 0 "ReqSts1_NotReqd" 1 "ReqSts1_Reqd";
VAL_ 416 RemStrtHvCtrlReqErsCmd 0 "ErsCmd_ErsCmdNotSet" 1 "ErsCmd_ErsCmdOn" 2 "ErsCmd_ErsCmdOff";
VAL_ 416 TcamResetResp 0 "SuccessFailNoResp_NoResponse" 1 "SuccessFailNoResp_Success" 2 "SuccessFailNoResp_Fail" 3 "SuccessFailNoResp_Reserved";
VAL_ 416 TelmExtrLiFileDeleteReqNoReqOnOff 0 "NoReqOnOff_Norequest" 1 "NoReqOnOff_On" 2 "NoReqOnOff_Off";
VAL_ 416 TelmExtrLiFileDownloadReqNoReqOnOff 0 "NoReqOnOff_Norequest" 1 "NoReqOnOff_On" 2 "NoReqOnOff_Off";
VAL_ 416 TelmExtrLiShowReqNoReqOnOff 0 "NoReqOnOff_Norequest" 1 "NoReqOnOff_On" 2 "NoReqOnOff_Off";
VAL_ 416 TelmStrangerModStopCtrlReq 0 "ReqSts1_NotReqd" 1 "ReqSts1_Reqd";
VAL_ 544 GNSSSolution1SatItSysNo1InUse 0 "NoYes1_No" 1 "NoYes1_Yes";
VAL_ 544 GNSSSolution1SatItSysNo2InUse 0 "NoYes1_No" 1 "NoYes1_Yes";
VAL_ 544 GNSSSolution1SatItSysNo3InUse 0 "NoYes1_No" 1 "NoYes1_Yes";
VAL_ 544 GNSSSolution1SatItSysNo4InUse 0 "NoYes1_No" 1 "NoYes1_Yes";
VAL_ 544 GNSSSolution1SatItSysNo5InUse 0 "NoYes1_No" 1 "NoYes1_Yes";
VAL_ 544 GNSSSolution1SatItSysNo6InUse 0 "NoYes1_No" 1 "NoYes1_Yes";
VAL_ 544 GNSSSolution1SatItSysNo7InUse 0 "NoYes1_No" 1 "NoYes1_Yes";
VAL_ 544 GNSSSolution1SatltPosnStsPrm1 0 "SatltPosnSts_PosnStsOfLvl1" 1 "SatltPosnSts_PosnStsOfLvl2" 2 "SatltPosnSts_PosnStsOfLvl3" 3 "SatltPosnSts_PosnStsOfLvl4";
VAL_ 544 GNSSSolution1SatltPosnStsPrm2 0 "Boolean_FALSE" 1 "Boolean_TRUE";
VAL_ 544 ImobVehRemReqAndRespImobVehRemReqCmd 0 "ImobVehRemReqCmd_ImobRemReqIdle" 1 "ImobVehRemReqCmd_NoImobnRemReq" 2 "ImobVehRemReqCmd_ImobnRemReq" 3 "ImobVehRemReqCmd_SpdLimRemReq" 4 "ImobVehRemReqCmd_ImobRemChkReq" 5 "ImobVehRemReqCmd_ImobRemStsReq";
VAL_ 544 LowrReAxle 0 "ReqSts1_NotReqd" 1 "ReqSts1_Reqd";
VAL_ 544 MobDevRCVReq1RCVCtrl 0 "RCVCtrl_Idle" 1 "RCVCtrl_Request" 2 "RCVCtrl_Start" 3 "RCVCtrl_Forward" 4 "RCVCtrl_Backward" 5 "RCVCtrl_Release" 6 "RCVCtrl_Quit" 7 "RCVCtrl_Complete" 8 "RCVCtrl_ForwardExchange" 9 "RCVCtrl_BackwardExchange";
VAL_ 544 MobDevRCVReq1Steertrim 0 "Steertrim_Idle" 1 "Steertrim_TurnLeft" 2 "Steertrim_TurnRight" 3 "Steertrim_TurnLeftExchange" 4 "Steertrim_TurnRightExchange" 5 "Steertrim_Release";
VAL_ 544 UWBKeyDistrictStsKey0 0 "UWBKeySts_idle" 1 "UWBKeySts_NotKeyFound" 2 "UWBKeySts_InternalFound" 3 "UWBKeySts_External_ExceedSixMeter" 4 "UWBKeySts_External_FrntFound" 5 "UWBKeySts_External_LeFrntFound" 6 "UWBKeySts_External_RiFrntFound" 7 "UWBKeySts_External_LeFound" 8 "UWBKeySts_External_RiFound" 9 "UWBKeySts_External_RearFound" 10 "UWBKeySts_External_LeRearFound" 11 "UWBKeySts_External_RiRearFound";
VAL_ 544 UWBKeyDistrictStsKey1 0 "UWBKeySts_idle" 1 "UWBKeySts_NotKeyFound" 2 "UWBKeySts_InternalFound" 3 "UWBKeySts_External_ExceedSixMeter" 4 "UWBKeySts_External_FrntFound" 5 "UWBKeySts_External_LeFrntFound" 6 "UWBKeySts_External_RiFrntFound" 7 "UWBKeySts_External_LeFound" 8 "UWBKeySts_External_RiFound" 9 "UWBKeySts_External_RearFound" 10 "UWBKeySts_External_LeRearFound" 11 "UWBKeySts_External_RiRearFound";
VAL_ 544 UWBKeyDistrictStsKey2 0 "UWBKeySts_idle" 1 "UWBKeySts_NotKeyFound" 2 "UWBKeySts_InternalFound" 3 "UWBKeySts_External_ExceedSixMeter" 4 "UWBKeySts_External_FrntFound" 5 "UWBKeySts_External_LeFrntFound" 6 "UWBKeySts_External_RiFrntFound" 7 "UWBKeySts_External_LeFound" 8 "UWBKeySts_External_RiFound" 9 "UWBKeySts_External_RearFound" 10 "UWBKeySts_External_LeRearFound" 11 "UWBKeySts_External_RiRearFound";
VAL_ 544 UWBKeyDistrictStsKey3 0 "UWBKeySts_idle" 1 "UWBKeySts_NotKeyFound" 2 "UWBKeySts_InternalFound" 3 "UWBKeySts_External_ExceedSixMeter" 4 "UWBKeySts_External_FrntFound" 5 "UWBKeySts_External_LeFrntFound" 6 "UWBKeySts_External_RiFrntFound" 7 "UWBKeySts_External_LeFound" 8 "UWBKeySts_External_RiFound" 9 "UWBKeySts_External_RearFound" 10 "UWBKeySts_External_LeRearFound" 11 "UWBKeySts_External_RiRearFound";
VAL_ 80 SpdLimdSts 0 "Boolean_FALSE" 1 "Boolean_TRUE";
VAL_ 1353 VFCVectorTCAMVFCid0 0 "VFCOnOff_Off" 1 "VFCOnOff_On";
VAL_ 1353 VFCVectorTCAMVFCid1 0 "VFCOnOff_Off" 1 "VFCOnOff_On";
VAL_ 1353 VFCVectorTCAMVFCid10 0 "VFCOnOff_Off" 1 "VFCOnOff_On";
VAL_ 1353 VFCVectorTCAMVFCid11 0 "VFCOnOff_Off" 1 "VFCOnOff_On";
VAL_ 1353 VFCVectorTCAMVFCid12 0 "VFCOnOff_Off" 1 "VFCOnOff_On";
VAL_ 1353 VFCVectorTCAMVFCid13 0 "VFCOnOff_Off" 1 "VFCOnOff_On";
VAL_ 1353 VFCVectorTCAMVFCid14 0 "VFCOnOff_Off" 1 "VFCOnOff_On";
VAL_ 1353 VFCVectorTCAMVFCid15 0 "VFCOnOff_Off" 1 "VFCOnOff_On";
VAL_ 1353 VFCVectorTCAMVFCid16 0 "VFCOnOff_Off" 1 "VFCOnOff_On";
VAL_ 1353 VFCVectorTCAMVFCid17 0 "VFCOnOff_Off" 1 "VFCOnOff_On";
VAL_ 1353 VFCVectorTCAMVFCid18 0 "VFCOnOff_Off" 1 "VFCOnOff_On";
VAL_ 1353 VFCVectorTCAMVFCid19 0 "VFCOnOff_Off" 1 "VFCOnOff_On";
VAL_ 1353 VFCVectorTCAMVFCid2 0 "VFCOnOff_Off" 1 "VFCOnOff_On";
VAL_ 1353 VFCVectorTCAMVFCid20 0 "VFCOnOff_Off" 1 "VFCOnOff_On";
VAL_ 1353 VFCVectorTCAMVFCid21 0 "VFCOnOff_Off" 1 "VFCOnOff_On";
VAL_ 1353 VFCVectorTCAMVFCid22 0 "VFCOnOff_Off" 1 "VFCOnOff_On";
VAL_ 1353 VFCVectorTCAMVFCid23 0 "VFCOnOff_Off" 1 "VFCOnOff_On";
VAL_ 1353 VFCVectorTCAMVFCid24 0 "VFCOnOff_Off" 1 "VFCOnOff_On";
VAL_ 1353 VFCVectorTCAMVFCid25 0 "VFCOnOff_Off" 1 "VFCOnOff_On";
VAL_ 1353 VFCVectorTCAMVFCid26 0 "VFCOnOff_Off" 1 "VFCOnOff_On";
VAL_ 1353 VFCVectorTCAMVFCid27 0 "VFCOnOff_Off" 1 "VFCOnOff_On";
VAL_ 1353 VFCVectorTCAMVFCid28 0 "VFCOnOff_Off" 1 "VFCOnOff_On";
VAL_ 1353 VFCVectorTCAMVFCid29 0 "VFCOnOff_Off" 1 "VFCOnOff_On";
VAL_ 1353 VFCVectorTCAMVFCid3 0 "VFCOnOff_Off" 1 "VFCOnOff_On";
VAL_ 1353 VFCVectorTCAMVFCid30 0 "VFCOnOff_Off" 1 "VFCOnOff_On";
VAL_ 1353 VFCVectorTCAMVFCid31 0 "VFCOnOff_Off" 1 "VFCOnOff_On";
VAL_ 1353 VFCVectorTCAMVFCid32 0 "VFCOnOff_Off" 1 "VFCOnOff_On";
VAL_ 1353 VFCVectorTCAMVFCid33 0 "VFCOnOff_Off" 1 "VFCOnOff_On";
VAL_ 1353 VFCVectorTCAMVFCid34 0 "VFCOnOff_Off" 1 "VFCOnOff_On";
VAL_ 1353 VFCVectorTCAMVFCid35 0 "VFCOnOff_Off" 1 "VFCOnOff_On";
VAL_ 1353 VFCVectorTCAMVFCid36 0 "VFCOnOff_Off" 1 "VFCOnOff_On";
VAL_ 1353 VFCVectorTCAMVFCid37 0 "VFCOnOff_Off" 1 "VFCOnOff_On";
VAL_ 1353 VFCVectorTCAMVFCid38 0 "VFCOnOff_Off" 1 "VFCOnOff_On";
VAL_ 1353 VFCVectorTCAMVFCid39 0 "VFCOnOff_Off" 1 "VFCOnOff_On";
VAL_ 1353 VFCVectorTCAMVFCid4 0 "VFCOnOff_Off" 1 "VFCOnOff_On";
VAL_ 1353 VFCVectorTCAMVFCid40 0 "VFCOnOff_Off" 1 "VFCOnOff_On";
VAL_ 1353 VFCVectorTCAMVFCid41 0 "VFCOnOff_Off" 1 "VFCOnOff_On";
VAL_ 1353 VFCVectorTCAMVFCid42 0 "VFCOnOff_Off" 1 "VFCOnOff_On";
VAL_ 1353 VFCVectorTCAMVFCid43 0 "VFCOnOff_Off" 1 "VFCOnOff_On";
VAL_ 1353 VFCVectorTCAMVFCid44 0 "VFCOnOff_Off" 1 "VFCOnOff_On";
VAL_ 1353 VFCVectorTCAMVFCid45 0 "VFCOnOff_Off" 1 "VFCOnOff_On";
VAL_ 1353 VFCVectorTCAMVFCid46 0 "VFCOnOff_Off" 1 "VFCOnOff_On";
VAL_ 1353 VFCVectorTCAMVFCid47 0 "VFCOnOff_Off" 1 "VFCOnOff_On";
VAL_ 1353 VFCVectorTCAMVFCid48 0 "VFCOnOff_Off" 1 "VFCOnOff_On";
VAL_ 1353 VFCVectorTCAMVFCid49 0 "VFCOnOff_Off" 1 "VFCOnOff_On";
VAL_ 1353 VFCVectorTCAMVFCid5 0 "VFCOnOff_Off" 1 "VFCOnOff_On";
VAL_ 1353 VFCVectorTCAMVFCid50 0 "VFCOnOff_Off" 1 "VFCOnOff_On";
VAL_ 1353 VFCVectorTCAMVFCid51 0 "VFCOnOff_Off" 1 "VFCOnOff_On";
VAL_ 1353 VFCVectorTCAMVFCid52 0 "VFCOnOff_Off" 1 "VFCOnOff_On";
VAL_ 1353 VFCVectorTCAMVFCid53 0 "VFCOnOff_Off" 1 "VFCOnOff_On";
VAL_ 1353 VFCVectorTCAMVFCid54 0 "VFCOnOff_Off" 1 "VFCOnOff_On";
VAL_ 1353 VFCVectorTCAMVFCid55 0 "VFCOnOff_Off" 1 "VFCOnOff_On";
VAL_ 1353 VFCVectorTCAMVFCid56 0 "VFCOnOff_Off" 1 "VFCOnOff_On";
VAL_ 1353 VFCVectorTCAMVFCid57 0 "VFCOnOff_Off" 1 "VFCOnOff_On";
VAL_ 1353 VFCVectorTCAMVFCid58 0 "VFCOnOff_Off" 1 "VFCOnOff_On";
VAL_ 1353 VFCVectorTCAMVFCid59 0 "VFCOnOff_Off" 1 "VFCOnOff_On";
VAL_ 1353 VFCVectorTCAMVFCid6 0 "VFCOnOff_Off" 1 "VFCOnOff_On";
VAL_ 1353 VFCVectorTCAMVFCid60 0 "VFCOnOff_Off" 1 "VFCOnOff_On";
VAL_ 1353 VFCVectorTCAMVFCid61 0 "VFCOnOff_Off" 1 "VFCOnOff_On";
VAL_ 1353 VFCVectorTCAMVFCid7 0 "VFCOnOff_Off" 1 "VFCOnOff_On";
VAL_ 1353 VFCVectorTCAMVFCid8 0 "VFCOnOff_Off" 1 "VFCOnOff_On";
VAL_ 1353 VFCVectorTCAMVFCid9 0 "VFCOnOff_Off" 1 "VFCOnOff_On";
VAL_ 1289 WakeUpReasonsforTCAM 0 "WakeupReasons_667949" 1 "WakeupReasons_667950" 2 "WakeupReasons_169654" 3 "WakeupReasons_667951" 4 "WakeupReasons_168965" 5 "WakeupReasons_197643" 6 "WakeupReasons_264933" 7 "WakeupReasons_45654" 8 "WakeupReasons_22058" 9 "WakeupReasons_49446" 10 "WakeupReasons_22060" 11 "WakeupReasons_269740" 12 "WakeupReasons_269735" 13 "WakeupReasons_269739" 14 "WakeupReasons_658500" 15 "WakeupReasons_21901" 16 "WakeupReasons_45793" 17 "WakeupReasons_45794" 18 "WakeupReasons_22005" 19 "WakeupReasons_22013" 20 "WakeupReasons_22100" 21 "WakeupReasons_45659" 22 "WakeupReasons_45657" 23 "WakeupReasons_140084" 24 "WakeupReasons_21973" 25 "WakeupReasons_91253" 26 "WakeupReasons_88123" 27 "WakeupReasons_88125" 28 "WakeupReasons_321583" 29 "WakeupReasons_74188" 30 "WakeupReasons_667945" 31 "WakeupReasons_169655" 32 "WakeupReasons_667948" 33 "WakeupReasons_168966" 34 "WakeupReasons_170865" 35 "WakeupReasons_197642" 36 "WakeupReasons_264876" 37 "WakeupReasons_191050" 38 "WakeupReasons_182033" 39 "WakeupReasons_200937" 40 "WakeupReasons_170807" 41 "WakeupReasons_319139" 42 "WakeupReasons_100298" 43 "WakeupReasons_100275" 44 "WakeupReasons_100300" 45 "WakeupReasons_100278" 46 "WakeupReasons_100281" 47 "WakeupReasons_265333" 48 "WakeupReasons_108776" 49 "WakeupReasons_176921" 50 "WakeupReasons_197826" 51 "WakeupReasons_185670" 52 "WakeupReasons_161066" 53 "WakeupReasons_200156" 54 "WakeupReasons_225696" 55 "WakeupReasons_21997" 56 "WakeupReasons_45656" 57 "WakeupReasons_266860" 58 "WakeupReasons_169894" 59 "WakeupReasons_320282" 60 "WakeupReasons_319422" 61 "WakeupReasons_320277" 62 "WakeupReasons_355601" 63 "WakeupReasons_360904" 64 "WakeupReasons_361505" 65 "WakeupReasons_361509" 66 "WakeupReasons_645094" 67 "WakeupReasons_68676" 68 "WakeupReasons_360008" 69 "WakeupReasons_109382" 70 "WakeupReasons_119273" 71 "WakeupReasons_224065" 72 "WakeupReasons_68644" 73 "WakeupReasons_109364" 74 "WakeupReasons_68481" 75 "WakeupReasons_224061" 76 "WakeupReasons_360006" 77 "WakeupReasons_138997" 78 "WakeupReasons_634696" 79 "WakeupReasons_645810" 80 "WakeupReasons_297868" 81 "WakeupReasons_315364" 82 "WakeupReasons_109367" 83 "WakeupReasons_320126" 84 "WakeupReasons_109387" 85 "WakeupReasons_634710" 86 "WakeupReasons_338820" 87 "WakeupReasons_67182" 88 "WakeupReasons_152237" 89 "WakeupReasons_145707" 90 "WakeupReasons_199172" 91 "WakeupReasons_144897" 92 "WakeupReasons_186489" 93 "WakeupReasons_144970" 94 "WakeupReasons_152786" 95 "WakeupReasons_264932" 96 "WakeupReasons_264934" 97 "WakeupReasons_356190" 98 "WakeupReasons_145688" 99 "WakeupReasons_95444" 100 "WakeupReasons_169945" 101 "WakeupReasons_140678" 102 "WakeupReasons_222553" 103 "WakeupReasons_224831" 104 "WakeupReasons_201815" 105 "WakeupReasons_45864" 106 "WakeupReasons_659549" 107 "WakeupReasons_45866" 108 "WakeupReasons_45867" 109 "WakeupReasons_169884" 110 "WakeupReasons_264962" 111 "WakeupReasons_201348" 112 "WakeupReasons_320287" 113 "WakeupReasons_156412" 114 "WakeupReasons_133749" 115 "WakeupReasons_355409" 116 "WakeupReasons_636692" 117 "WakeupReasons_533044" 118 "WakeupReasons_106774" 119 "WakeupReasons_145311" 120 "WakeupReasons_145319" 121 "WakeupReasons_152774" 122 "WakeupReasons_145330" 123 "WakeupReasons_145388" 124 "WakeupReasons_145399" 125 "WakeupReasons_145362" 126 "WakeupReasons_145385" 127 "WakeupReasons_145373" 128 "WakeupReasons_145288" 129 "WakeupReasons_145419" 130 "WakeupReasons_145454" 131 "WakeupReasons_145462" 132 "WakeupReasons_269156" 133 "WakeupReasons_300427" 134 "WakeupReasons_220322" 135 "WakeupReasons_224617" 136 "WakeupReasons_224634" 137 "WakeupReasons_300682" 138 "WakeupReasons_264958" 139 "WakeupReasons_160597" 140 "WakeupReasons_160602" 141 "WakeupReasons_108841" 142 "WakeupReasons_265569" 143 "WakeupReasons_526429" 144 "WakeupReasons_514545" 145 "WakeupReasons_265232" 146 "WakeupReasons_644550" 147 "WakeupReasons_317616" 148 "WakeupReasons_354791" 149 "WakeupReasons_320631" 150 "WakeupReasons_337565" 151 "WakeupReasons_532007" 152 "WakeupReasons_514503" 153 "WakeupReasons_299117" 154 "WakeupReasons_340667" 155 "WakeupReasons_321845" 156 "WakeupReasons_179103" 157 "WakeupReasons_108810" 158 "WakeupReasons_322857" 159 "WakeupReasons_658603" 160 "WakeupReasons_197648" 161 "WakeupReasons_160596" 162 "WakeupReasons_361272" 163 "WakeupReasons_361279" 164 "WakeupReasons_265305" 165 "WakeupReasons_265328" 166 "WakeupReasons_265330" 167 "WakeupReasons_298808" 168 "WakeupReasons_515804" 169 "WakeupReasons_514502" 170 "WakeupReasons_645753" 171 "WakeupReasons_646109" 172 "WakeupReasons_299547" 173 "WakeupReasons_318342" 174 "WakeupReasons_360543" 175 "WakeupReasons_356549" 176 "WakeupReasons_198484" 177 "WakeupReasons_300681" 178 "WakeupReasons_359211" 179 "WakeupReasons_534077" 180 "WakeupReasons_525705" 181 "WakeupReasons_360299" 182 "WakeupReasons_526445" 183 "WakeupReasons_534145" 184 "WakeupReasons_192030" 185 "WakeupReasons_652361" 186 "WakeupReasons_355214" 187 "WakeupReasons_321317" 188 "WakeupReasons_359187" 189 "WakeupReasons_321057" 190 "WakeupReasons_321319" 191 "WakeupReasons_321323" 192 "WakeupReasons_321077" 193 "WakeupReasons_320895" 194 "WakeupReasons_655340" 195 "WakeupReasons_636556" 196 "WakeupReasons_108834" 197 "WakeupReasons_265937" 198 "WakeupReasons_533050" 199 "WakeupReasons_526426" 200 "WakeupReasons_264712" 201 "WakeupReasons_319401" 202 "WakeupReasons_643973" 203 "WakeupReasons_223715" 204 "WakeupReasons_199159" 205 "WakeupReasons_318382" 206 "WakeupReasons_226967" 207 "WakeupReasons_531743" 208 "WakeupReasons_360542" 209 "WakeupReasons_264726" 210 "WakeupReasons_535214" 211 "WakeupReasons_335068" 212 "WakeupReasons_316796" 213 "WakeupReasons_526438" 214 "WakeupReasons_198433" 215 "WakeupReasons_225961" 216 "WakeupReasons_197665" 217 "WakeupReasons_224550" 218 "WakeupReasons_667962" 219 "WakeupReasons_667953" 220 "WakeupReasons_110885" 221 "WakeupReasons_224552" 222 "WakeupReasons_224553" 223 "WakeupReasons_652546" 224 "WakeupReasons_331194" 225 "WakeupReasons_667820" 226 "WakeupReasons_659350" 227 "WakeupReasons_101706" 228 "WakeupReasons_101725" 229 "WakeupReasons_101728" 230 "WakeupReasons_101727" 231 "WakeupReasons_166267" 232 "WakeupReasons_156440" 233 "WakeupReasons_95949" 234 "WakeupReasons_112799" 235 "WakeupReasons_146470" 236 "WakeupReasons_176748" 237 "WakeupReasons_223920" 238 "WakeupReasons_668531" 239 "WakeupReasons_670087" 240 "WakeupReasons_668529" 241 "WakeupReasons_45858" 242 "WakeupReasons_315981" 243 "WakeupReasons_533370" 244 "WakeupReasons_533371" 245 "WakeupReasons_533372" 246 "WakeupReasons_241902" 247 "WakeupReasons_359559" 248 "WakeupReasons_516327" 249 "WakeupReasons_533872" 250 "WakeupReasons_45856" 251 "WakeupReasons_45853" 252 "WakeupReasons_45854" 253 "WakeupReasons_45852" 254 "WakeupReasons_45851" 255 "WakeupReasons_45850" 256 "WakeupReasons_45849" 257 "WakeupReasons_636801" 258 "WakeupReasons_109466" 259 "WakeupReasons_109467" 260 "WakeupReasons_670345" 261 "WakeupReasons_NMPDUReceived" 262 "WakeupReasons_358832" 263 "WakeupReasons_200683" 264 "WakeupReasons_198452" 265 "WakeupReasons_185457" 266 "WakeupReasons_185490" 267 "WakeupReasons_4471" 268 "WakeupReasons_269034" 269 "WakeupReasons_215560" 270 "WakeupReasons_312881" 271 "WakeupReasons_269140" 272 "WakeupReasons_197653" 273 "WakeupReasons_337991" 274 "WakeupReasons_658188" 275 "WakeupReasons_674953" 276 "WakeupReasons_675064" 277 "WakeupReasons_674958" 278 "WakeupReasons_675494" 279 "WakeupReasons_675837" 280 "WakeupReasons_667879" 281 "WakeupReasons_667947" 282 "WakeupReasons_676265" 283 "WakeupReasons_669465" 284 "WakeupReasons_670928" 285 "WakeupReasons_669447" 286 "WakeupReasons_667922" 287 "WakeupReasons_670753" 288 "WakeupReasons_668395" 289 "WakeupReasons_668393" 290 "WakeupReasons_667850" 291 "WakeupReasons_667848" 292 "WakeupReasons_311279" 293 "WakeupReasons_182918" 294 "WakeupReasons_667988" 295 "WakeupReasons_532555" 296 "WakeupReasons_532556" 297 "WakeupReasons_113348" 298 "WakeupReasons_193474" 299 "WakeupReasons_667871" 300 "WakeupReasons_670966" 301 "WakeupReasons_667985" 302 "WakeupReasons_670354" 303 "WakeupReasons_46017" 304 "WakeupReasons_675742" 305 "WakeupReasons_106669" 306 "WakeupReasons_80609" 307 "WakeupReasons_199714" 308 "WakeupReasons_200090" 309 "WakeupReasons_139075" 310 "WakeupReasons_268983" 311 "WakeupReasons_265131" 312 "WakeupReasons_263473" 313 "WakeupReasons_45887" 314 "WakeupReasons_69678" 315 "WakeupReasons_69679" 316 "WakeupReasons_45897" 317 "WakeupReasons_45898" 318 "WakeupReasons_80608" 319 "WakeupReasons_45869" 320 "WakeupReasons_45870" 321 "WakeupReasons_45872" 322 "WakeupReasons_45875" 323 "WakeupReasons_45871" 324 "WakeupReasons_45876" 325 "WakeupReasons_667980" 326 "WakeupReasons_45877" 327 "WakeupReasons_667973" 328 "WakeupReasons_670962" 329 "WakeupReasons_45888" 330 "WakeupReasons_45890" 331 "WakeupReasons_667869" 332 "WakeupReasons_45846" 333 "WakeupReasons_45847" 334 "WakeupReasons_45848" 335 "WakeupReasons_262872" 336 "WakeupReasons_127924" 337 "WakeupReasons_127926" 338 "WakeupReasons_674223" 339 "WakeupReasons_667982" 340 "WakeupReasons_657121" 341 "WakeupReasons_265745" 342 "WakeupReasons_657120" 343 "WakeupReasons_675564" 344 "WakeupReasons_197644" 345 "WakeupReasons_264943" 346 "WakeupReasons_264697" 347 "WakeupReasons_69216" 348 "WakeupReasons_128671" 349 "WakeupReasons_356598" 350 "WakeupReasons_675745" 351 "WakeupReasons_667983" 352 "WakeupReasons_667987" 353 "WakeupReasons_75103" 354 "WakeupReasons_305818" 355 "WakeupReasons_670942" 356 "WakeupReasons_532932" 357 "WakeupReasons_532933" 358 "WakeupReasons_83199" 359 "WakeupReasons_45900" 360 "WakeupReasons_88458" 361 "WakeupReasons_329457" 362 "WakeupReasons_45902" 363 "WakeupReasons_224211" 364 "WakeupReasons_667981" 365 "WakeupReasons_667874" 366 "WakeupReasons_46020" 367 "WakeupReasons_667842" 368 "WakeupReasons_145161" 369 "WakeupReasons_233755" 370 "WakeupReasons_297056" 371 "WakeupReasons_264691" 372 "WakeupReasons_262871" 373 "WakeupReasons_264964" 374 "WakeupReasons_667872" 375 "WakeupReasons_45655" 376 "WakeupReasons_177214" 377 "WakeupReasons_671005" 378 "WakeupReasons_680712" 379 "WakeupReasons_669822" 380 "WakeupReasons_668523" 381 "WakeupReasons_680974" 382 "WakeupReasons_680975" 383 "WakeupReasons_681028" 384 "WakeupReasons_670462" 385 "WakeupReasons_681134" 386 "WakeupReasons_681031" 387 "WakeupReasons_681711" 388 "WakeupReasons_682034" 389 "WakeupReasons_674839" 390 "WakeupReasons_681915" 391 "WakeupReasons_682032" 392 "WakeupReasons_682037" 393 "WakeupReasons_682688" 394 "WakeupReasons_681789" 395 "WakeupReasons_682023" 396 "WakeupReasons_681023" 397 "WakeupReasons_676285" 398 "WakeupReasons_682077" 399 "WakeupReasons_682076" 400 "WakeupReasons_682078" 401 "WakeupReasons_682153" 402 "WakeupReasons_682155" 403 "WakeupReasons_682152" 404 "WakeupReasons_682154" 405 "WakeupReasons_682074";
VAL_ 338 DigKeyReqSts 0 "DigKeyReqStatus_Idle" 1 "DigKeyReqStatus_OwnerPairingInprocess" 2 "DigKeyReqStatus_UnpairingInprocess" 3 "DigKeyReqStatus_TerminationInprocess" 4 "DigKeyReqStatus_SuspendInprocess" 5 "DigKeyReqStatus_ResumeInprocess" 6 "DigKeyReqStatus_ValidKeySearchInProc" 7 "DigKeyReqStatus_WaitMobDevInProc" 8 "DigKeyReqStatus_ToBeReady" 9 "DigKeyReqStatus_OPPrecondiitonCheckInproc" 10 "DigKeyReqStatus_Reserved2" 11 "DigKeyReqStatus_Reserved3" 12 "DigKeyReqStatus_Reserved4" 13 "DigKeyReqStatus_Reserved5" 14 "DigKeyReqStatus_Reserved6" 15 "DigKeyReqStatus_Reserved7";
SIG_GROUP_ 176 ApproachReq 1 : ApproachReqData1 ApproachReqData10 ApproachReqData11 ApproachReqData12 ApproachReqData13 ApproachReqData14 ApproachReqData15 ApproachReqData16 ApproachReqData2 ApproachReqData3 ApproachReqData4 ApproachReqData5 ApproachReqData6 ApproachReqData7 ApproachReqData8 ApproachReqData9;
SIG_GROUP_ 544 BiasedPosnFromSatlt1 1 : BiasedPosnFromSatlt1Cntr BiasedPosnFromSatlt1PosnLat BiasedPosnFromSatlt1PosnLgt;
SIG_GROUP_ 176 BLEKeySearchResp 1 : BLEKeySearchRespData1 BLEKeySearchRespData10 BLEKeySearchRespData11 BLEKeySearchRespData12 BLEKeySearchRespData13 BLEKeySearchRespData14 BLEKeySearchRespData15 BLEKeySearchRespData16 BLEKeySearchRespData2 BLEKeySearchRespData3 BLEKeySearchRespData4 BLEKeySearchRespData5 BLEKeySearchRespData6 BLEKeySearchRespData7 BLEKeySearchRespData8 BLEKeySearchRespData9;
SIG_GROUP_ 736 CalltypeAndSts 1 : CalltypeAndStsCallType CalltypeAndStsEcallStatus;
SIG_GROUP_ 176 DigKeyDataToHMI 1 : DigKeyDataToHMIAcknowledgment DigKeyDataToHMIDKDataByte1 DigKeyDataToHMIDKDataByte2 DigKeyDataToHMIDKDataByte3 DigKeyDataToHMIDKDataByte4 DigKeyDataToHMIDKDataByte5 DigKeyDataToHMIDKDataByte6 DigKeyDataToHMIHeader;
SIG_GROUP_ 336 DigKeyGidInfo1 1 : DigKeyGidInfo1Byte0 DigKeyGidInfo1Byte1 DigKeyGidInfo1Byte2 DigKeyGidInfo1Byte3 DigKeyGidInfo1Byte4 DigKeyGidInfo1Byte5 DigKeyGidInfo1Byte6 DigKeyGidInfo1Byte7;
SIG_GROUP_ 336 DigKeyGidInfo2 1 : DigKeyGidInfo2Byte0 DigKeyGidInfo2Byte1 DigKeyGidInfo2Byte2 DigKeyGidInfo2Byte3 DigKeyGidInfo2Byte4 DigKeyGidInfo2Byte5 DigKeyGidInfo2Byte6 DigKeyGidInfo2Byte7;
SIG_GROUP_ 192 DKDataFromBLE 1 : DKDataFromBLEAcknowledgment DKDataFromBLEDKDataByte1 DKDataFromBLEDKDataByte2 DKDataFromBLEDKDataByte3 DKDataFromBLEDKDataByte4 DKDataFromBLEDKDataByte5 DKDataFromBLEDKDataByte6 DKDataFromBLEHeader;
SIG_GROUP_ 336 DKDataFromTelm 1 : DKDataFromTelmAcknowledgment DKDataFromTelmDKDataByte1 DKDataFromTelmDKDataByte2 DKDataFromTelmDKDataByte3 DKDataFromTelmDKDataByte4 DKDataFromTelmDKDataByte5 DKDataFromTelmDKDataByte6 DKDataFromTelmHeader;
SIG_GROUP_ 192 DKDataFromTelm1 1 : DKDataFromTelm1Acknowledgment DKDataFromTelm1DKDataByte1 DKDataFromTelm1DKDataByte2 DKDataFromTelm1DKDataByte3 DKDataFromTelm1DKDataByte4 DKDataFromTelm1DKDataByte5 DKDataFromTelm1DKDataByte6 DKDataFromTelm1Header;
SIG_GROUP_ 336 ErsCmdRec 1 : ErsCmdRecErsCmd ErsCmdRecErsRunTime;
SIG_GROUP_ 544 GNSSSolution1 1 : GNSSSolution1Cntr GNSSSolution1NoOfSatItForSysNo1 GNSSSolution1NoOfSatItForSysNo2 GNSSSolution1NoOfSatItForSysNo3 GNSSSolution1NoOfSatItForSysNo4 GNSSSolution1NoOfSatItForSysNo5 GNSSSolution1NoOfSatItForSysNo6 GNSSSolution1NoOfSatItForSysNo7 GNSSSolution1SatItSysNo1InUse GNSSSolution1SatItSysNo2InUse GNSSSolution1SatItSysNo3InUse GNSSSolution1SatItSysNo4InUse GNSSSolution1SatItSysNo5InUse GNSSSolution1SatItSysNo6InUse GNSSSolution1SatItSysNo7InUse GNSSSolution1SatltPosnStsPrm1 GNSSSolution1SatltPosnStsPrm2;
SIG_GROUP_ 544 GNSSSolution2 1 : GNSSSolution2Cntr GNSSSolution2PreHozlDil GNSSSolution2PrePosnDil GNSSSolution2PreVertDil;
SIG_GROUP_ 320 GuestrSts1 1 : GuestrSts1Chks GuestrSts1Cntr GuestrSts1Validity;
SIG_GROUP_ 544 ImobVehRemReqAndResp 1 : ImobVehRemReqAndRespImobVehDataRemReq0 ImobVehRemReqAndRespImobVehDataRemReq1 ImobVehRemReqAndRespImobVehDataRemReq2 ImobVehRemReqAndRespImobVehDataRemReq3 ImobVehRemReqAndRespImobVehDataRemReq4 ImobVehRemReqAndRespImobVehRemReqCmd ImobVehRemReqAndRespImobVehRemTmrOrSpdLim;
SIG_GROUP_ 544 MobDevRCVReq1 1 : MobDevRCVReq1Chks MobDevRCVReq1Cntr MobDevRCVReq1MobDevSts MobDevRCVReq1RCVCtrl MobDevRCVReq1Steertrim;
SIG_GROUP_ 320 MobDevRPAAuthResp1 1 : MobDevRPAAuthResp1Answer MobDevRPAAuthResp1Chks MobDevRPAAuthResp1Cntr MobDevRPAAuthResp1X MobDevRPAAuthResp1Y;
SIG_GROUP_ 320 MobDevRPAReq1 1 : MobDevRPAReq1Chks MobDevRPAReq1Cntr MobDevRPAReq1MobDevSts MobDevRPAReq1RPAOutModeSubT MobDevRPAReq1RPAReq MobDevRPAReq1RSPACtrl;
SIG_GROUP_ 176 NFCAndBLEKeyEnaSts 1 : NFCAndBLEKeyEnaStsData1 NFCAndBLEKeyEnaStsData10 NFCAndBLEKeyEnaStsData11 NFCAndBLEKeyEnaStsData12 NFCAndBLEKeyEnaStsData13 NFCAndBLEKeyEnaStsData14 NFCAndBLEKeyEnaStsData15 NFCAndBLEKeyEnaStsData16 NFCAndBLEKeyEnaStsData2 NFCAndBLEKeyEnaStsData3 NFCAndBLEKeyEnaStsData4 NFCAndBLEKeyEnaStsData5 NFCAndBLEKeyEnaStsData6 NFCAndBLEKeyEnaStsData7 NFCAndBLEKeyEnaStsData8 NFCAndBLEKeyEnaStsData9;
SIG_GROUP_ 192 NFCKeySearchResp 1 : NFCKeySearchRespData1 NFCKeySearchRespData10 NFCKeySearchRespData11 NFCKeySearchRespData12 NFCKeySearchRespData13 NFCKeySearchRespData14 NFCKeySearchRespData15 NFCKeySearchRespData16 NFCKeySearchRespData2 NFCKeySearchRespData3 NFCKeySearchRespData4 NFCKeySearchRespData5 NFCKeySearchRespData6 NFCKeySearchRespData7 NFCKeySearchRespData8 NFCKeySearchRespData9;
SIG_GROUP_ 544 PosnFromSatlt1 1 : PosnFromSatlt1Cntr PosnFromSatlt1PosnLat PosnFromSatlt1PosnLgt;
SIG_GROUP_ 544 PosnFromSatlt2 1 : PosnFromSatlt2Cntr PosnFromSatlt2PosnSpdosn;
SIG_GROUP_ 544 PosnFromSatlt3 1 : PosnFromSatlt3Cntr PosnFromSatlt3PosnAlti PosnFromSatlt3PosnDir PosnFromSatlt3TiForMins PosnFromSatlt3TiForMsec PosnFromSatlt3TiForSec;
SIG_GROUP_ 416 RemStrtHvCtrlReq 1 : RemStrtHvCtrlReqErsCmd RemStrtHvCtrlReqErsRunTime;
SIG_GROUP_ 192 RKEAndNFCReqSts 1 : RKEAndNFCReqStsData1 RKEAndNFCReqStsData10 RKEAndNFCReqStsData11 RKEAndNFCReqStsData12 RKEAndNFCReqStsData13 RKEAndNFCReqStsData14 RKEAndNFCReqStsData15 RKEAndNFCReqStsData16 RKEAndNFCReqStsData2 RKEAndNFCReqStsData3 RKEAndNFCReqStsData4 RKEAndNFCReqStsData5 RKEAndNFCReqStsData6 RKEAndNFCReqStsData7 RKEAndNFCReqStsData8 RKEAndNFCReqStsData9;
SIG_GROUP_ 336 TelmBookClimaReq 1 : TelmBookClimaReqHmiCmptmtTSpSpcl TelmBookClimaReqOnOffNoReq TelmBookClimaReqTempRange;
SIG_GROUP_ 336 TelmBookSeatHeatClimalReq 1 : TelmBookSeatHeatClimalReqDrvHeatClimaLvl TelmBookSeatHeatClimalReqPassHeatClimaLvl TelmBookSeatHeatClimalReqSecLeHeatClimaLvl TelmBookSeatHeatClimalReqSecRiHeatClimaLvl TelmBookSeatHeatClimalReqThrdLeHeatClimaLvl TelmBookSeatHeatClimalReqThrdRiHeatClimaLvl;
SIG_GROUP_ 336 TelmBookSeatVentnClimalReq 1 : TelmBookSeatVentnClimalReqDrvVentnClimaLvl TelmBookSeatVentnClimalReqPassVentnClimaLvl TelmBookSeatVentnClimalReqSecLeVentnClimaLvl TelmBookSeatVentnClimalReqSecRiVentnClimaLvl TelmBookSeatVentnClimalReqThrdLeVentnClimaLvl TelmBookSeatVentnClimalReqThrdRiVentnClimaL;
SIG_GROUP_ 336 TelmClimaTSet 1 : TelmClimaTSetHmiCmptmtTSpSpcl TelmClimaTSetTempRange;
SIG_GROUP_ 416 TelmExtrLiFileDeleteReq 1 : TelmExtrLiFileDeleteReqID TelmExtrLiFileDeleteReqNoReqOnOff;
SIG_GROUP_ 416 TelmExtrLiFileDownloadReq 1 : TelmExtrLiFileDownloadReqID TelmExtrLiFileDownloadReqNoReqOnOff;
SIG_GROUP_ 416 TelmExtrLiShowReq 1 : TelmExtrLiShowReqID TelmExtrLiShowReqNoReqOnOff;
SIG_GROUP_ 336 TelmLockgCenReq 1 : TelmLockgCenReqReqTyp TelmLockgCenReqTiVld;
SIG_GROUP_ 416 TelmStrangePassWordSet 1 : TelmStrangePassWordSetNo1 TelmStrangePassWordSetNo2 TelmStrangePassWordSetNo3 TelmStrangePassWordSetNo4;
SIG_GROUP_ 544 UWBKeyDistrictSts 1 : UWBKeyDistrictStsKey0 UWBKeyDistrictStsKey1 UWBKeyDistrictStsKey2 UWBKeyDistrictStsKey3;
SIG_GROUP_ 1353 VFCVectorTCAM 1 : VFCVectorTCAMBlockID VFCVectorTCAMVFCid0 VFCVectorTCAMVFCid1 VFCVectorTCAMVFCid10 VFCVectorTCAMVFCid11 VFCVectorTCAMVFCid12 VFCVectorTCAMVFCid13 VFCVectorTCAMVFCid14 VFCVectorTCAMVFCid15 VFCVectorTCAMVFCid16 VFCVectorTCAMVFCid17 VFCVectorTCAMVFCid18 VFCVectorTCAMVFCid19 VFCVectorTCAMVFCid2 VFCVectorTCAMVFCid20 VFCVectorTCAMVFCid21 VFCVectorTCAMVFCid22 VFCVectorTCAMVFCid23 VFCVectorTCAMVFCid24 VFCVectorTCAMVFCid25 VFCVectorTCAMVFCid26 VFCVectorTCAMVFCid27 VFCVectorTCAMVFCid28 VFCVectorTCAMVFCid29 VFCVectorTCAMVFCid3 VFCVectorTCAMVFCid30 VFCVectorTCAMVFCid31 VFCVectorTCAMVFCid32 VFCVectorTCAMVFCid33 VFCVectorTCAMVFCid34 VFCVectorTCAMVFCid35 VFCVectorTCAMVFCid36 VFCVectorTCAMVFCid37 VFCVectorTCAMVFCid38 VFCVectorTCAMVFCid39 VFCVectorTCAMVFCid4 VFCVectorTCAMVFCid40 VFCVectorTCAMVFCid41 VFCVectorTCAMVFCid42 VFCVectorTCAMVFCid43 VFCVectorTCAMVFCid44 VFCVectorTCAMVFCid45 VFCVectorTCAMVFCid46 VFCVectorTCAMVFCid47 VFCVectorTCAMVFCid48 VFCVectorTCAMVFCid49 VFCVectorTCAMVFCid5 VFCVectorTCAMVFCid50 VFCVectorTCAMVFCid51 VFCVectorTCAMVFCid52 VFCVectorTCAMVFCid53 VFCVectorTCAMVFCid54 VFCVectorTCAMVFCid55 VFCVectorTCAMVFCid56 VFCVectorTCAMVFCid57 VFCVectorTCAMVFCid58 VFCVectorTCAMVFCid59 VFCVectorTCAMVFCid6 VFCVectorTCAMVFCid60 VFCVectorTCAMVFCid61 VFCVectorTCAMVFCid7 VFCVectorTCAMVFCid8 VFCVectorTCAMVFCid9;
SIG_GROUP_ 336 WinOpenClsGlbReqFromTelm 1 : WinOpenClsGlbReqFromTelmWindowOpenValue WinOpenClsGlbReqFromTelmWinOpenClsGlbSts;
